VERSION "AgOpen Rate CAN ECU DBC with S0-S3 banks, 16 nodes, and service CAN"

NS_ :

BS_:

BU_: MASTER TOOL NODE1 NODE2 NODE3 NODE4 NODE5 NODE6 NODE7 NODE8 NODE9 NODE10 NODE11 NODE12 NODE13 NODE14 NODE15 NODE16

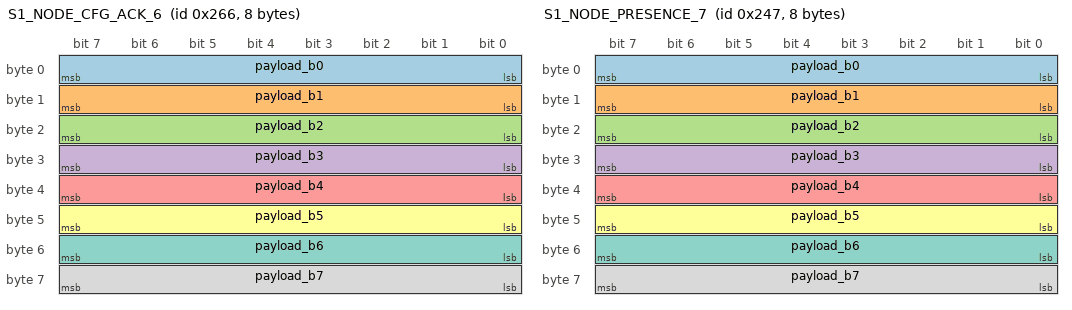
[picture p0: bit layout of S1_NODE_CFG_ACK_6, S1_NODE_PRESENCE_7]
BO_ 614 S1_NODE_CFG_ACK_6: 8 NODE6
 SG_ payload_b0 : 0|8@1+ (1,0) [0|255] "raw"  MASTER,NODE1,NODE2,NODE3,NODE4,NODE5,NODE6,NODE7,NODE8,NODE9,NODE10,NODE11,NODE12,NODE13,NODE14,NODE15,NODE16,TOOL
 SG_ payload_b1 : 8|8@1+ (1,0) [0|255] "raw"  MASTER,NODE1,NODE2,NODE3,NODE4,NODE5,NODE6,NODE7,NODE8,NODE9,NODE10,NODE11,NODE12,NODE13,NODE14,NODE15,NODE16,TOOL
 SG_ payload_b2 : 16|8@1+ (1,0) [0|255] "raw"  MASTER,NODE1,NODE2,NODE3,NODE4,NODE5,NODE6,NODE7,NODE8,NODE9,NODE10,NODE11,NODE12,NODE13,NODE14,NODE15,NODE16,TOOL
 SG_ payload_b3 : 24|8@1+ (1,0) [0|255] "raw"  MASTER,NODE1,NODE2,NODE3,NODE4,NODE5,NODE6,NODE7,NODE8,NODE9,NODE10,NODE11,NODE12,NODE13,NODE14,NODE15,NODE16,TOOL
 SG_ payload_b4 : 32|8@1+ (1,0) [0|255] "raw"  MASTER,NODE1,NODE2,NODE3,NODE4,NODE5,NODE6,NODE7,NODE8,NODE9,NODE10,NODE11,NODE12,NODE13,NODE14,NODE15,NODE16,TOOL
 SG_ payload_b5 : 40|8@1+ (1,0) [0|255] "raw"  MASTER,NODE1,NODE2,NODE3,NODE4,NODE5,NODE6,NODE7,NODE8,NODE9,NODE10,NODE11,NODE12,NODE13,NODE14,NODE15,NODE16,TOOL
 SG_ payload_b6 : 48|8@1+ (1,0) [0|255] "raw"  MASTER,NODE1,NODE2,NODE3,NODE4,NODE5,NODE6,NODE7,NODE8,NODE9,NODE10,NODE11,NODE12,NODE13,NODE14,NODE15,NODE16,TOOL
 SG_ payload_b7 : 56|8@1+ (1,0) [0|255] "raw"  MASTER,NODE1,NODE2,NODE3,NODE4,NODE5,NODE6,NODE7,NODE8,NODE9,NODE10,NODE11,NODE12,NODE13,NODE14,NODE15,NODE16,TOOL

BO_ 646 S1_NODE_STATUS_FAST_6: 8 NODE6
 SG_ status_flags : 0|8@1+ (1,0) [0|255] "bitfield"  MASTER,NODE1,NODE2,NODE3,NODE4,NODE5,NODE6,NODE7,NODE8,NODE9,NODE10,NODE11,NODE12,NODE13,NODE14,NODE15,NODE16,TOOL
 SG_ error_code : 8|8@1+ (1,0) [0|255] ""  MASTER,NODE1,NODE2,NODE3,NODE4,NODE5,NODE6,NODE7,NODE8,NODE9,NODE10,NODE11,NODE12,NODE13,NODE14,NODE15,NODE16,TOOL
 SG_ actual_rpm : 16|16@1+ (1,0) [0|10000] "rpm"  MASTER,NODE1,NODE2,NODE3,NODE4,NODE5,NODE6,NODE7,NODE8,NODE9,NODE10,NODE11,NODE12,NODE13,NODE14,NODE15,NODE16,TOOL
 SG_ actual_pos : 32|16@1+ (1.52587890625e-05,0) [0|0.9999847412109375] "rev"  MASTER,NODE1,NODE2,NODE3,NODE4,NODE5,NODE6,NODE7,NODE8,NODE9,NODE10,NODE11,NODE12,NODE13,NODE14,NODE15,NODE16,TOOL
 SG_ alive_counter : 48|8@1+ (1,0) [0|255] ""  MASTER,NODE1,NODE2,NODE3,NODE4,NODE5,NODE6,NODE7,NODE8,NODE9,NODE10,NODE11,NODE12,NODE13,NODE14,NODE15,NODE16,TOOL
 SG_ sync_error : 56|8@1- (0.00390625,0) [-0.5|0.49609375] "rev"  MASTER,NODE1,NODE2,NODE3,NODE4,NODE5,NODE6,NODE7,NODE8,NODE9,NODE10,NODE11,NODE12,NODE13,NODE14,NODE15,NODE16,TOOL

BO_ 710 S1_NODE_DIAG_6: 8 NODE6
 SG_ bus_voltage : 0|16@1+ (0.1,0) [0|6553.5] "V"  MASTER,NODE1,NODE2,NODE3,NODE4,NODE5,NODE6,NODE7,NODE8,NODE9,NODE10,NODE11,NODE12,NODE13,NODE14,NODE15,NODE16,TOOL
 SG_ motor_current : 16|16@1- (0.1,0) [-3276.8|3276.7] "A"  MASTER,NODE1,NODE2,NODE3,NODE4,NODE5,NODE6,NODE7,NODE8,NODE9,NODE10,NODE11,NODE12,NODE13,NODE14,NODE15,NODE16,TOOL
 SG_ controller_temp : 32|8@1- (1,0) [-128|127] "degC"  MASTER,NODE1,NODE2,NODE3,NODE4,NODE5,NODE6,NODE7,NODE8,NODE9,NODE10,NODE11,NODE12,NODE13,NODE14,NODE15,NODE16,TOOL
 SG_ motor_temp : 40|8@1- (1,0) [-128|127] "degC"  MASTER,NODE1,NODE2,NODE3,NODE4,NODE5,NODE6,NODE7,NODE8,NODE9,NODE10,NODE11,NODE12,NODE13,NODE14,NODE15,NODE16,TOOL
 SG_ fault_flags : 48|8@1+ (1,0) [0|255] "bitfield"  MASTER,NODE1,NODE2,NODE3,NODE4,NODE5,NODE6,NODE7,NODE8,NODE9,NODE10,NODE11,NODE12,NODE13,NODE14,NODE15,NODE16,TOOL
 SG_ warning_flags : 56|8@1+ (1,0) [0|255] "bitfield"  MASTER,NODE1,NODE2,NODE3,NODE4,NODE5,NODE6,NODE7,NODE8,NODE9,NODE10,NODE11,NODE12,NODE13,NODE14,NODE15,NODE16,TOOL

BO_ 535 S1_NODE_CMD_7: 8 MASTER
 SG_ node_command : 0|8@1+ (1,0) [0|255] ""  MASTER,NODE1,NODE2,NODE3,NODE4,NODE5,NODE6,NODE7,NODE8,NODE9,NODE10,NODE11,NODE12,NODE13,NODE14,NODE15,NODE16,TOOL
 SG_ node_flags : 8|8@1+ (1,0) [0|255] "bitfield"  MASTER,NODE1,NODE2,NODE3,NODE4,NODE5,NODE6,NODE7,NODE8,NODE9,NODE10,NODE11,NODE12,NODE13,NODE14,NODE15,NODE16,TOOL
 SG_ trim_rpm : 16|16@1- (0.1,0) [-3276.8|3276.7] "rpm"  MASTER,NODE1,NODE2,NODE3,NODE4,NODE5,NODE6,NODE7,NODE8,NODE9,NODE10,NODE11,NODE12,NODE13,NODE14,NODE15,NODE16,TOOL
 SG_ section_mask : 32|16@1+ (1,0) [0|65535] "bitmask"  MASTER,NODE1,NODE2,NODE3,NODE4,NODE5,NODE6,NODE7,NODE8,NODE9,NODE10,NODE11,NODE12,NODE13,NODE14,NODE15,NODE16,TOOL
 SG_ seq : 48|8@1+ (1,0) [0|255] ""  MASTER,NODE1,NODE2,NODE3,NODE4,NODE5,NODE6,NODE7,NODE8,NODE9,NODE10,NODE11,NODE12,NODE13,NODE14,NODE15,NODE16,TOOL
 SG_ reserved : 56|8@1+ (1,0) [0|255] ""  MASTER,NODE1,NODE2,NODE3,NODE4,NODE5,NODE6,NODE7,NODE8,NODE9,NODE10,NODE11,NODE12,NODE13,NODE14,NODE15,NODE16,TOOL

BO_ 583 S1_NODE_PRESENCE_7: 8 NODE7
 SG_ payload_b0 : 0|8@1+ (1,0) [0|255] "raw"  MASTER,NODE1,NODE2,NODE3,NODE4,NODE5,NODE6,NODE7,NODE8,NODE9,NODE10,NODE11,NODE12,NODE13,NODE14,NODE15,NODE16,TOOL
 SG_ payload_b1 : 8|8@1+ (1,0) [0|255] "raw"  MASTER,NODE1,NODE2,NODE3,NODE4,NODE5,NODE6,NODE7,NODE8,NODE9,NODE10,NODE11,NODE12,NODE13,NODE14,NODE15,NODE16,TOOL
 SG_ payload_b2 : 16|8@1+ (1,0) [0|255] "raw"  MASTER,NODE1,NODE2,NODE3,NODE4,NODE5,NODE6,NODE7,NODE8,NODE9,NODE10,NODE11,NODE12,NODE13,NODE14,NODE15,NODE16,TOOL
 SG_ payload_b3 : 24|8@1+ (1,0) [0|255] "raw"  MASTER,NODE1,NODE2,NODE3,NODE4,NODE5,NODE6,NODE7,NODE8,NODE9,NODE10,NODE11,NODE12,NODE13,NODE14,NODE15,NODE16,TOOL
 SG_ payload_b4 : 32|8@1+ (1,0) [0|255] "raw"  MASTER,NODE1,NODE2,NODE3,NODE4,NODE5,NODE6,NODE7,NODE8,NODE9,NODE10,NODE11,NODE12,NODE13,NODE14,NODE15,NODE16,TOOL
 SG_ payload_b5 : 40|8@1+ (1,0) [0|255] "raw"  MASTER,NODE1,NODE2,NODE3,NODE4,NODE5,NODE6,NODE7,NODE8,NODE9,NODE10,NODE11,NODE12,NODE13,NODE14,NODE15,NODE16,TOOL
 SG_ payload_b6 : 48|8@1+ (1,0) [0|255] "raw"  MASTER,NODE1,NODE2,NODE3,NODE4,NODE5,NODE6,NODE7,NODE8,NODE9,NODE10,NODE11,NODE12,NODE13,NODE14,NODE15,NODE16,TOOL
 SG_ payload_b7 : 56|8@1+ (1,0) [0|255] "raw"  MASTER,NODE1,NODE2,NODE3,NODE4,NODE5,NODE6,NODE7,NODE8,NODE9,NODE10,NODE11,NODE12,NODE13,NODE14,NODE15,NODE16,TOOL

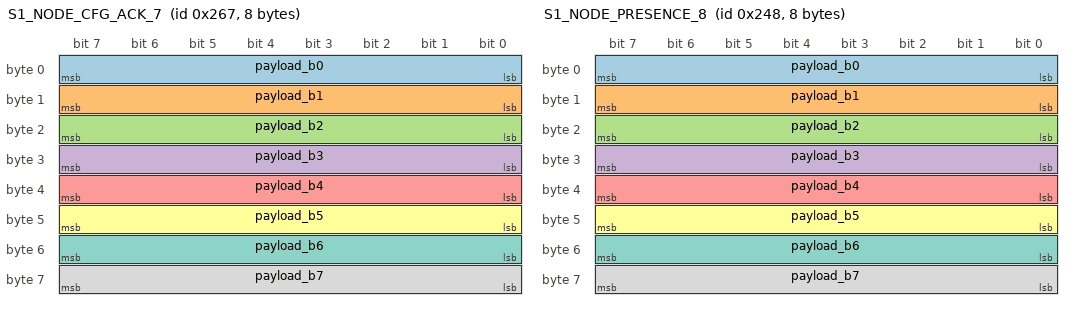
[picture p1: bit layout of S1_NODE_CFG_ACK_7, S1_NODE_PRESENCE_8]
BO_ 615 S1_NODE_CFG_ACK_7: 8 NODE7
 SG_ payload_b0 : 0|8@1+ (1,0) [0|255] "raw"  MASTER,NODE1,NODE2,NODE3,NODE4,NODE5,NODE6,NODE7,NODE8,NODE9,NODE10,NODE11,NODE12,NODE13,NODE14,NODE15,NODE16,TOOL
 SG_ payload_b1 : 8|8@1+ (1,0) [0|255] "raw"  MASTER,NODE1,NODE2,NODE3,NODE4,NODE5,NODE6,NODE7,NODE8,NODE9,NODE10,NODE11,NODE12,NODE13,NODE14,NODE15,NODE16,TOOL
 SG_ payload_b2 : 16|8@1+ (1,0) [0|255] "raw"  MASTER,NODE1,NODE2,NODE3,NODE4,NODE5,NODE6,NODE7,NODE8,NODE9,NODE10,NODE11,NODE12,NODE13,NODE14,NODE15,NODE16,TOOL
 SG_ payload_b3 : 24|8@1+ (1,0) [0|255] "raw"  MASTER,NODE1,NODE2,NODE3,NODE4,NODE5,NODE6,NODE7,NODE8,NODE9,NODE10,NODE11,NODE12,NODE13,NODE14,NODE15,NODE16,TOOL
 SG_ payload_b4 : 32|8@1+ (1,0) [0|255] "raw"  MASTER,NODE1,NODE2,NODE3,NODE4,NODE5,NODE6,NODE7,NODE8,NODE9,NODE10,NODE11,NODE12,NODE13,NODE14,NODE15,NODE16,TOOL
 SG_ payload_b5 : 40|8@1+ (1,0) [0|255] "raw"  MASTER,NODE1,NODE2,NODE3,NODE4,NODE5,NODE6,NODE7,NODE8,NODE9,NODE10,NODE11,NODE12,NODE13,NODE14,NODE15,NODE16,TOOL
 SG_ payload_b6 : 48|8@1+ (1,0) [0|255] "raw"  MASTER,NODE1,NODE2,NODE3,NODE4,NODE5,NODE6,NODE7,NODE8,NODE9,NODE10,NODE11,NODE12,NODE13,NODE14,NODE15,NODE16,TOOL
 SG_ payload_b7 : 56|8@1+ (1,0) [0|255] "raw"  MASTER,NODE1,NODE2,NODE3,NODE4,NODE5,NODE6,NODE7,NODE8,NODE9,NODE10,NODE11,NODE12,NODE13,NODE14,NODE15,NODE16,TOOL

BO_ 647 S1_NODE_STATUS_FAST_7: 8 NODE7
 SG_ status_flags : 0|8@1+ (1,0) [0|255] "bitfield"  MASTER,NODE1,NODE2,NODE3,NODE4,NODE5,NODE6,NODE7,NODE8,NODE9,NODE10,NODE11,NODE12,NODE13,NODE14,NODE15,NODE16,TOOL
 SG_ error_code : 8|8@1+ (1,0) [0|255] ""  MASTER,NODE1,NODE2,NODE3,NODE4,NODE5,NODE6,NODE7,NODE8,NODE9,NODE10,NODE11,NODE12,NODE13,NODE14,NODE15,NODE16,TOOL
 SG_ actual_rpm : 16|16@1+ (1,0) [0|10000] "rpm"  MASTER,NODE1,NODE2,NODE3,NODE4,NODE5,NODE6,NODE7,NODE8,NODE9,NODE10,NODE11,NODE12,NODE13,NODE14,NODE15,NODE16,TOOL
 SG_ actual_pos : 32|16@1+ (1.52587890625e-05,0) [0|0.9999847412109375] "rev"  MASTER,NODE1,NODE2,NODE3,NODE4,NODE5,NODE6,NODE7,NODE8,NODE9,NODE10,NODE11,NODE12,NODE13,NODE14,NODE15,NODE16,TOOL
 SG_ alive_counter : 48|8@1+ (1,0) [0|255] ""  MASTER,NODE1,NODE2,NODE3,NODE4,NODE5,NODE6,NODE7,NODE8,NODE9,NODE10,NODE11,NODE12,NODE13,NODE14,NODE15,NODE16,TOOL
 SG_ sync_error : 56|8@1- (0.00390625,0) [-0.5|0.49609375] "rev"  MASTER,NODE1,NODE2,NODE3,NODE4,NODE5,NODE6,NODE7,NODE8,NODE9,NODE10,NODE11,NODE12,NODE13,NODE14,NODE15,NODE16,TOOL

BO_ 711 S1_NODE_DIAG_7: 8 NODE7
 SG_ bus_voltage : 0|16@1+ (0.1,0) [0|6553.5] "V"  MASTER,NODE1,NODE2,NODE3,NODE4,NODE5,NODE6,NODE7,NODE8,NODE9,NODE10,NODE11,NODE12,NODE13,NODE14,NODE15,NODE16,TOOL
 SG_ motor_current : 16|16@1- (0.1,0) [-3276.8|3276.7] "A"  MASTER,NODE1,NODE2,NODE3,NODE4,NODE5,NODE6,NODE7,NODE8,NODE9,NODE10,NODE11,NODE12,NODE13,NODE14,NODE15,NODE16,TOOL
 SG_ controller_temp : 32|8@1- (1,0) [-128|127] "degC"  MASTER,NODE1,NODE2,NODE3,NODE4,NODE5,NODE6,NODE7,NODE8,NODE9,NODE10,NODE11,NODE12,NODE13,NODE14,NODE15,NODE16,TOOL
 SG_ motor_temp : 40|8@1- (1,0) [-128|127] "degC"  MASTER,NODE1,NODE2,NODE3,NODE4,NODE5,NODE6,NODE7,NODE8,NODE9,NODE10,NODE11,NODE12,NODE13,NODE14,NODE15,NODE16,TOOL
 SG_ fault_flags : 48|8@1+ (1,0) [0|255] "bitfield"  MASTER,NODE1,NODE2,NODE3,NODE4,NODE5,NODE6,NODE7,NODE8,NODE9,NODE10,NODE11,NODE12,NODE13,NODE14,NODE15,NODE16,TOOL
 SG_ warning_flags : 56|8@1+ (1,0) [0|255] "bitfield"  MASTER,NODE1,NODE2,NODE3,NODE4,NODE5,NODE6,NODE7,NODE8,NODE9,NODE10,NODE11,NODE12,NODE13,NODE14,NODE15,NODE16,TOOL

BO_ 536 S1_NODE_CMD_8: 8 MASTER
 SG_ node_command : 0|8@1+ (1,0) [0|255] ""  MASTER,NODE1,NODE2,NODE3,NODE4,NODE5,NODE6,NODE7,NODE8,NODE9,NODE10,NODE11,NODE12,NODE13,NODE14,NODE15,NODE16,TOOL
 SG_ node_flags : 8|8@1+ (1,0) [0|255] "bitfield"  MASTER,NODE1,NODE2,NODE3,NODE4,NODE5,NODE6,NODE7,NODE8,NODE9,NODE10,NODE11,NODE12,NODE13,NODE14,NODE15,NODE16,TOOL
 SG_ trim_rpm : 16|16@1- (0.1,0) [-3276.8|3276.7] "rpm"  MASTER,NODE1,NODE2,NODE3,NODE4,NODE5,NODE6,NODE7,NODE8,NODE9,NODE10,NODE11,NODE12,NODE13,NODE14,NODE15,NODE16,TOOL
 SG_ section_mask : 32|16@1+ (1,0) [0|65535] "bitmask"  MASTER,NODE1,NODE2,NODE3,NODE4,NODE5,NODE6,NODE7,NODE8,NODE9,NODE10,NODE11,NODE12,NODE13,NODE14,NODE15,NODE16,TOOL
 SG_ seq : 48|8@1+ (1,0) [0|255] ""  MASTER,NODE1,NODE2,NODE3,NODE4,NODE5,NODE6,NODE7,NODE8,NODE9,NODE10,NODE11,NODE12,NODE13,NODE14,NODE15,NODE16,TOOL
 SG_ reserved : 56|8@1+ (1,0) [0|255] ""  MASTER,NODE1,NODE2,NODE3,NODE4,NODE5,NODE6,NODE7,NODE8,NODE9,NODE10,NODE11,NODE12,NODE13,NODE14,NODE15,NODE16,TOOL

BO_ 584 S1_NODE_PRESENCE_8: 8 NODE8
 SG_ payload_b0 : 0|8@1+ (1,0) [0|255] "raw"  MASTER,NODE1,NODE2,NODE3,NODE4,NODE5,NODE6,NODE7,NODE8,NODE9,NODE10,NODE11,NODE12,NODE13,NODE14,NODE15,NODE16,TOOL
 SG_ payload_b1 : 8|8@1+ (1,0) [0|255] "raw"  MASTER,NODE1,NODE2,NODE3,NODE4,NODE5,NODE6,NODE7,NODE8,NODE9,NODE10,NODE11,NODE12,NODE13,NODE14,NODE15,NODE16,TOOL
 SG_ payload_b2 : 16|8@1+ (1,0) [0|255] "raw"  MASTER,NODE1,NODE2,NODE3,NODE4,NODE5,NODE6,NODE7,NODE8,NODE9,NODE10,NODE11,NODE12,NODE13,NODE14,NODE15,NODE16,TOOL
 SG_ payload_b3 : 24|8@1+ (1,0) [0|255] "raw"  MASTER,NODE1,NODE2,NODE3,NODE4,NODE5,NODE6,NODE7,NODE8,NODE9,NODE10,NODE11,NODE12,NODE13,NODE14,NODE15,NODE16,TOOL
 SG_ payload_b4 : 32|8@1+ (1,0) [0|255] "raw"  MASTER,NODE1,NODE2,NODE3,NODE4,NODE5,NODE6,NODE7,NODE8,NODE9,NODE10,NODE11,NODE12,NODE13,NODE14,NODE15,NODE16,TOOL
 SG_ payload_b5 : 40|8@1+ (1,0) [0|255] "raw"  MASTER,NODE1,NODE2,NODE3,NODE4,NODE5,NODE6,NODE7,NODE8,NODE9,NODE10,NODE11,NODE12,NODE13,NODE14,NODE15,NODE16,TOOL
 SG_ payload_b6 : 48|8@1+ (1,0) [0|255] "raw"  MASTER,NODE1,NODE2,NODE3,NODE4,NODE5,NODE6,NODE7,NODE8,NODE9,NODE10,NODE11,NODE12,NODE13,NODE14,NODE15,NODE16,TOOL
 SG_ payload_b7 : 56|8@1+ (1,0) [0|255] "raw"  MASTER,NODE1,NODE2,NODE3,NODE4,NODE5,NODE6,NODE7,NODE8,NODE9,NODE10,NODE11,NODE12,NODE13,NODE14,NODE15,NODE16,TOOL

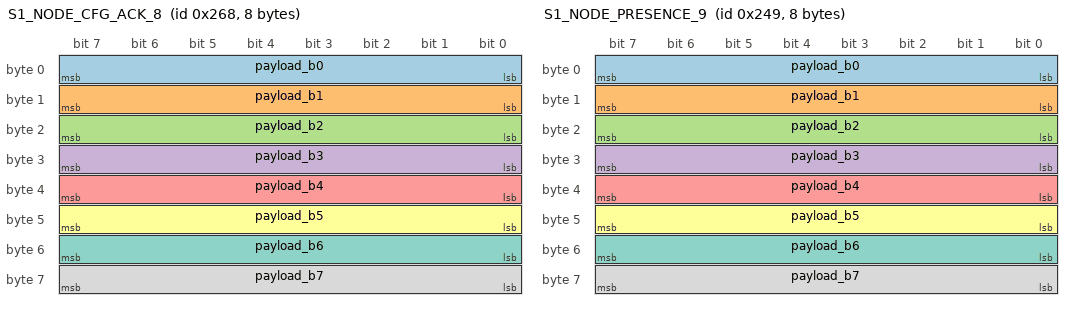
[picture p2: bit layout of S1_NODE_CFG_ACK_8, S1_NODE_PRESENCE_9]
BO_ 616 S1_NODE_CFG_ACK_8: 8 NODE8
 SG_ payload_b0 : 0|8@1+ (1,0) [0|255] "raw"  MASTER,NODE1,NODE2,NODE3,NODE4,NODE5,NODE6,NODE7,NODE8,NODE9,NODE10,NODE11,NODE12,NODE13,NODE14,NODE15,NODE16,TOOL
 SG_ payload_b1 : 8|8@1+ (1,0) [0|255] "raw"  MASTER,NODE1,NODE2,NODE3,NODE4,NODE5,NODE6,NODE7,NODE8,NODE9,NODE10,NODE11,NODE12,NODE13,NODE14,NODE15,NODE16,TOOL
 SG_ payload_b2 : 16|8@1+ (1,0) [0|255] "raw"  MASTER,NODE1,NODE2,NODE3,NODE4,NODE5,NODE6,NODE7,NODE8,NODE9,NODE10,NODE11,NODE12,NODE13,NODE14,NODE15,NODE16,TOOL
 SG_ payload_b3 : 24|8@1+ (1,0) [0|255] "raw"  MASTER,NODE1,NODE2,NODE3,NODE4,NODE5,NODE6,NODE7,NODE8,NODE9,NODE10,NODE11,NODE12,NODE13,NODE14,NODE15,NODE16,TOOL
 SG_ payload_b4 : 32|8@1+ (1,0) [0|255] "raw"  MASTER,NODE1,NODE2,NODE3,NODE4,NODE5,NODE6,NODE7,NODE8,NODE9,NODE10,NODE11,NODE12,NODE13,NODE14,NODE15,NODE16,TOOL
 SG_ payload_b5 : 40|8@1+ (1,0) [0|255] "raw"  MASTER,NODE1,NODE2,NODE3,NODE4,NODE5,NODE6,NODE7,NODE8,NODE9,NODE10,NODE11,NODE12,NODE13,NODE14,NODE15,NODE16,TOOL
 SG_ payload_b6 : 48|8@1+ (1,0) [0|255] "raw"  MASTER,NODE1,NODE2,NODE3,NODE4,NODE5,NODE6,NODE7,NODE8,NODE9,NODE10,NODE11,NODE12,NODE13,NODE14,NODE15,NODE16,TOOL
 SG_ payload_b7 : 56|8@1+ (1,0) [0|255] "raw"  MASTER,NODE1,NODE2,NODE3,NODE4,NODE5,NODE6,NODE7,NODE8,NODE9,NODE10,NODE11,NODE12,NODE13,NODE14,NODE15,NODE16,TOOL

BO_ 648 S1_NODE_STATUS_FAST_8: 8 NODE8
 SG_ status_flags : 0|8@1+ (1,0) [0|255] "bitfield"  MASTER,NODE1,NODE2,NODE3,NODE4,NODE5,NODE6,NODE7,NODE8,NODE9,NODE10,NODE11,NODE12,NODE13,NODE14,NODE15,NODE16,TOOL
 SG_ error_code : 8|8@1+ (1,0) [0|255] ""  MASTER,NODE1,NODE2,NODE3,NODE4,NODE5,NODE6,NODE7,NODE8,NODE9,NODE10,NODE11,NODE12,NODE13,NODE14,NODE15,NODE16,TOOL
 SG_ actual_rpm : 16|16@1+ (1,0) [0|10000] "rpm"  MASTER,NODE1,NODE2,NODE3,NODE4,NODE5,NODE6,NODE7,NODE8,NODE9,NODE10,NODE11,NODE12,NODE13,NODE14,NODE15,NODE16,TOOL
 SG_ actual_pos : 32|16@1+ (1.52587890625e-05,0) [0|0.9999847412109375] "rev"  MASTER,NODE1,NODE2,NODE3,NODE4,NODE5,NODE6,NODE7,NODE8,NODE9,NODE10,NODE11,NODE12,NODE13,NODE14,NODE15,NODE16,TOOL
 SG_ alive_counter : 48|8@1+ (1,0) [0|255] ""  MASTER,NODE1,NODE2,NODE3,NODE4,NODE5,NODE6,NODE7,NODE8,NODE9,NODE10,NODE11,NODE12,NODE13,NODE14,NODE15,NODE16,TOOL
 SG_ sync_error : 56|8@1- (0.00390625,0) [-0.5|0.49609375] "rev"  MASTER,NODE1,NODE2,NODE3,NODE4,NODE5,NODE6,NODE7,NODE8,NODE9,NODE10,NODE11,NODE12,NODE13,NODE14,NODE15,NODE16,TOOL

BO_ 712 S1_NODE_DIAG_8: 8 NODE8
 SG_ bus_voltage : 0|16@1+ (0.1,0) [0|6553.5] "V"  MASTER,NODE1,NODE2,NODE3,NODE4,NODE5,NODE6,NODE7,NODE8,NODE9,NODE10,NODE11,NODE12,NODE13,NODE14,NODE15,NODE16,TOOL
 SG_ motor_current : 16|16@1- (0.1,0) [-3276.8|3276.7] "A"  MASTER,NODE1,NODE2,NODE3,NODE4,NODE5,NODE6,NODE7,NODE8,NODE9,NODE10,NODE11,NODE12,NODE13,NODE14,NODE15,NODE16,TOOL
 SG_ controller_temp : 32|8@1- (1,0) [-128|127] "degC"  MASTER,NODE1,NODE2,NODE3,NODE4,NODE5,NODE6,NODE7,NODE8,NODE9,NODE10,NODE11,NODE12,NODE13,NODE14,NODE15,NODE16,TOOL
 SG_ motor_temp : 40|8@1- (1,0) [-128|127] "degC"  MASTER,NODE1,NODE2,NODE3,NODE4,NODE5,NODE6,NODE7,NODE8,NODE9,NODE10,NODE11,NODE12,NODE13,NODE14,NODE15,NODE16,TOOL
 SG_ fault_flags : 48|8@1+ (1,0) [0|255] "bitfield"  MASTER,NODE1,NODE2,NODE3,NODE4,NODE5,NODE6,NODE7,NODE8,NODE9,NODE10,NODE11,NODE12,NODE13,NODE14,NODE15,NODE16,TOOL
 SG_ warning_flags : 56|8@1+ (1,0) [0|255] "bitfield"  MASTER,NODE1,NODE2,NODE3,NODE4,NODE5,NODE6,NODE7,NODE8,NODE9,NODE10,NODE11,NODE12,NODE13,NODE14,NODE15,NODE16,TOOL

BO_ 537 S1_NODE_CMD_9: 8 MASTER
 SG_ node_command : 0|8@1+ (1,0) [0|255] ""  MASTER,NODE1,NODE2,NODE3,NODE4,NODE5,NODE6,NODE7,NODE8,NODE9,NODE10,NODE11,NODE12,NODE13,NODE14,NODE15,NODE16,TOOL
 SG_ node_flags : 8|8@1+ (1,0) [0|255] "bitfield"  MASTER,NODE1,NODE2,NODE3,NODE4,NODE5,NODE6,NODE7,NODE8,NODE9,NODE10,NODE11,NODE12,NODE13,NODE14,NODE15,NODE16,TOOL
 SG_ trim_rpm : 16|16@1- (0.1,0) [-3276.8|3276.7] "rpm"  MASTER,NODE1,NODE2,NODE3,NODE4,NODE5,NODE6,NODE7,NODE8,NODE9,NODE10,NODE11,NODE12,NODE13,NODE14,NODE15,NODE16,TOOL
 SG_ section_mask : 32|16@1+ (1,0) [0|65535] "bitmask"  MASTER,NODE1,NODE2,NODE3,NODE4,NODE5,NODE6,NODE7,NODE8,NODE9,NODE10,NODE11,NODE12,NODE13,NODE14,NODE15,NODE16,TOOL
 SG_ seq : 48|8@1+ (1,0) [0|255] ""  MASTER,NODE1,NODE2,NODE3,NODE4,NODE5,NODE6,NODE7,NODE8,NODE9,NODE10,NODE11,NODE12,NODE13,NODE14,NODE15,NODE16,TOOL
 SG_ reserved : 56|8@1+ (1,0) [0|255] ""  MASTER,NODE1,NODE2,NODE3,NODE4,NODE5,NODE6,NODE7,NODE8,NODE9,NODE10,NODE11,NODE12,NODE13,NODE14,NODE15,NODE16,TOOL

BO_ 585 S1_NODE_PRESENCE_9: 8 NODE9
 SG_ payload_b0 : 0|8@1+ (1,0) [0|255] "raw"  MASTER,NODE1,NODE2,NODE3,NODE4,NODE5,NODE6,NODE7,NODE8,NODE9,NODE10,NODE11,NODE12,NODE13,NODE14,NODE15,NODE16,TOOL
 SG_ payload_b1 : 8|8@1+ (1,0) [0|255] "raw"  MASTER,NODE1,NODE2,NODE3,NODE4,NODE5,NODE6,NODE7,NODE8,NODE9,NODE10,NODE11,NODE12,NODE13,NODE14,NODE15,NODE16,TOOL
 SG_ payload_b2 : 16|8@1+ (1,0) [0|255] "raw"  MASTER,NODE1,NODE2,NODE3,NODE4,NODE5,NODE6,NODE7,NODE8,NODE9,NODE10,NODE11,NODE12,NODE13,NODE14,NODE15,NODE16,TOOL
 SG_ payload_b3 : 24|8@1+ (1,0) [0|255] "raw"  MASTER,NODE1,NODE2,NODE3,NODE4,NODE5,NODE6,NODE7,NODE8,NODE9,NODE10,NODE11,NODE12,NODE13,NODE14,NODE15,NODE16,TOOL
 SG_ payload_b4 : 32|8@1+ (1,0) [0|255] "raw"  MASTER,NODE1,NODE2,NODE3,NODE4,NODE5,NODE6,NODE7,NODE8,NODE9,NODE10,NODE11,NODE12,NODE13,NODE14,NODE15,NODE16,TOOL
 SG_ payload_b5 : 40|8@1+ (1,0) [0|255] "raw"  MASTER,NODE1,NODE2,NODE3,NODE4,NODE5,NODE6,NODE7,NODE8,NODE9,NODE10,NODE11,NODE12,NODE13,NODE14,NODE15,NODE16,TOOL
 SG_ payload_b6 : 48|8@1+ (1,0) [0|255] "raw"  MASTER,NODE1,NODE2,NODE3,NODE4,NODE5,NODE6,NODE7,NODE8,NODE9,NODE10,NODE11,NODE12,NODE13,NODE14,NODE15,NODE16,TOOL
 SG_ payload_b7 : 56|8@1+ (1,0) [0|255] "raw"  MASTER,NODE1,NODE2,NODE3,NODE4,NODE5,NODE6,NODE7,NODE8,NODE9,NODE10,NODE11,NODE12,NODE13,NODE14,NODE15,NODE16,TOOL

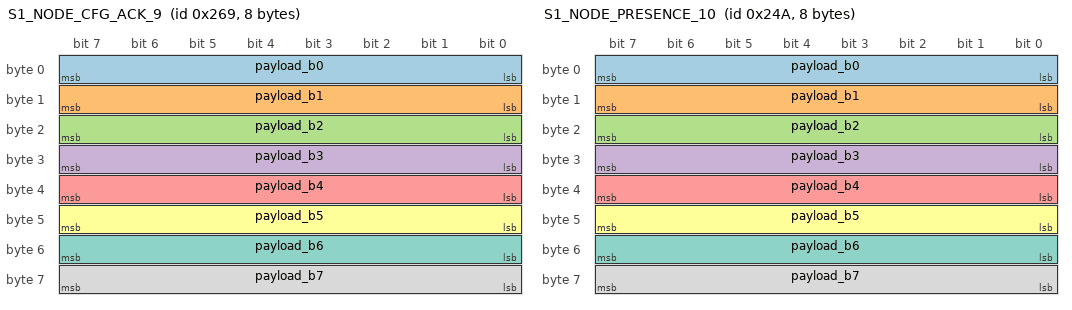
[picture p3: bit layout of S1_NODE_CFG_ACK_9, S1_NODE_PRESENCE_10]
BO_ 617 S1_NODE_CFG_ACK_9: 8 NODE9
 SG_ payload_b0 : 0|8@1+ (1,0) [0|255] "raw"  MASTER,NODE1,NODE2,NODE3,NODE4,NODE5,NODE6,NODE7,NODE8,NODE9,NODE10,NODE11,NODE12,NODE13,NODE14,NODE15,NODE16,TOOL
 SG_ payload_b1 : 8|8@1+ (1,0) [0|255] "raw"  MASTER,NODE1,NODE2,NODE3,NODE4,NODE5,NODE6,NODE7,NODE8,NODE9,NODE10,NODE11,NODE12,NODE13,NODE14,NODE15,NODE16,TOOL
 SG_ payload_b2 : 16|8@1+ (1,0) [0|255] "raw"  MASTER,NODE1,NODE2,NODE3,NODE4,NODE5,NODE6,NODE7,NODE8,NODE9,NODE10,NODE11,NODE12,NODE13,NODE14,NODE15,NODE16,TOOL
 SG_ payload_b3 : 24|8@1+ (1,0) [0|255] "raw"  MASTER,NODE1,NODE2,NODE3,NODE4,NODE5,NODE6,NODE7,NODE8,NODE9,NODE10,NODE11,NODE12,NODE13,NODE14,NODE15,NODE16,TOOL
 SG_ payload_b4 : 32|8@1+ (1,0) [0|255] "raw"  MASTER,NODE1,NODE2,NODE3,NODE4,NODE5,NODE6,NODE7,NODE8,NODE9,NODE10,NODE11,NODE12,NODE13,NODE14,NODE15,NODE16,TOOL
 SG_ payload_b5 : 40|8@1+ (1,0) [0|255] "raw"  MASTER,NODE1,NODE2,NODE3,NODE4,NODE5,NODE6,NODE7,NODE8,NODE9,NODE10,NODE11,NODE12,NODE13,NODE14,NODE15,NODE16,TOOL
 SG_ payload_b6 : 48|8@1+ (1,0) [0|255] "raw"  MASTER,NODE1,NODE2,NODE3,NODE4,NODE5,NODE6,NODE7,NODE8,NODE9,NODE10,NODE11,NODE12,NODE13,NODE14,NODE15,NODE16,TOOL
 SG_ payload_b7 : 56|8@1+ (1,0) [0|255] "raw"  MASTER,NODE1,NODE2,NODE3,NODE4,NODE5,NODE6,NODE7,NODE8,NODE9,NODE10,NODE11,NODE12,NODE13,NODE14,NODE15,NODE16,TOOL

BO_ 649 S1_NODE_STATUS_FAST_9: 8 NODE9
 SG_ status_flags : 0|8@1+ (1,0) [0|255] "bitfield"  MASTER,NODE1,NODE2,NODE3,NODE4,NODE5,NODE6,NODE7,NODE8,NODE9,NODE10,NODE11,NODE12,NODE13,NODE14,NODE15,NODE16,TOOL
 SG_ error_code : 8|8@1+ (1,0) [0|255] ""  MASTER,NODE1,NODE2,NODE3,NODE4,NODE5,NODE6,NODE7,NODE8,NODE9,NODE10,NODE11,NODE12,NODE13,NODE14,NODE15,NODE16,TOOL
 SG_ actual_rpm : 16|16@1+ (1,0) [0|10000] "rpm"  MASTER,NODE1,NODE2,NODE3,NODE4,NODE5,NODE6,NODE7,NODE8,NODE9,NODE10,NODE11,NODE12,NODE13,NODE14,NODE15,NODE16,TOOL
 SG_ actual_pos : 32|16@1+ (1.52587890625e-05,0) [0|0.9999847412109375] "rev"  MASTER,NODE1,NODE2,NODE3,NODE4,NODE5,NODE6,NODE7,NODE8,NODE9,NODE10,NODE11,NODE12,NODE13,NODE14,NODE15,NODE16,TOOL
 SG_ alive_counter : 48|8@1+ (1,0) [0|255] ""  MASTER,NODE1,NODE2,NODE3,NODE4,NODE5,NODE6,NODE7,NODE8,NODE9,NODE10,NODE11,NODE12,NODE13,NODE14,NODE15,NODE16,TOOL
 SG_ sync_error : 56|8@1- (0.00390625,0) [-0.5|0.49609375] "rev"  MASTER,NODE1,NODE2,NODE3,NODE4,NODE5,NODE6,NODE7,NODE8,NODE9,NODE10,NODE11,NODE12,NODE13,NODE14,NODE15,NODE16,TOOL

BO_ 713 S1_NODE_DIAG_9: 8 NODE9
 SG_ bus_voltage : 0|16@1+ (0.1,0) [0|6553.5] "V"  MASTER,NODE1,NODE2,NODE3,NODE4,NODE5,NODE6,NODE7,NODE8,NODE9,NODE10,NODE11,NODE12,NODE13,NODE14,NODE15,NODE16,TOOL
 SG_ motor_current : 16|16@1- (0.1,0) [-3276.8|3276.7] "A"  MASTER,NODE1,NODE2,NODE3,NODE4,NODE5,NODE6,NODE7,NODE8,NODE9,NODE10,NODE11,NODE12,NODE13,NODE14,NODE15,NODE16,TOOL
 SG_ controller_temp : 32|8@1- (1,0) [-128|127] "degC"  MASTER,NODE1,NODE2,NODE3,NODE4,NODE5,NODE6,NODE7,NODE8,NODE9,NODE10,NODE11,NODE12,NODE13,NODE14,NODE15,NODE16,TOOL
 SG_ motor_temp : 40|8@1- (1,0) [-128|127] "degC"  MASTER,NODE1,NODE2,NODE3,NODE4,NODE5,NODE6,NODE7,NODE8,NODE9,NODE10,NODE11,NODE12,NODE13,NODE14,NODE15,NODE16,TOOL
 SG_ fault_flags : 48|8@1+ (1,0) [0|255] "bitfield"  MASTER,NODE1,NODE2,NODE3,NODE4,NODE5,NODE6,NODE7,NODE8,NODE9,NODE10,NODE11,NODE12,NODE13,NODE14,NODE15,NODE16,TOOL
 SG_ warning_flags : 56|8@1+ (1,0) [0|255] "bitfield"  MASTER,NODE1,NODE2,NODE3,NODE4,NODE5,NODE6,NODE7,NODE8,NODE9,NODE10,NODE11,NODE12,NODE13,NODE14,NODE15,NODE16,TOOL

BO_ 538 S1_NODE_CMD_10: 8 MASTER
 SG_ node_command : 0|8@1+ (1,0) [0|255] ""  MASTER,NODE1,NODE2,NODE3,NODE4,NODE5,NODE6,NODE7,NODE8,NODE9,NODE10,NODE11,NODE12,NODE13,NODE14,NODE15,NODE16,TOOL
 SG_ node_flags : 8|8@1+ (1,0) [0|255] "bitfield"  MASTER,NODE1,NODE2,NODE3,NODE4,NODE5,NODE6,NODE7,NODE8,NODE9,NODE10,NODE11,NODE12,NODE13,NODE14,NODE15,NODE16,TOOL
 SG_ trim_rpm : 16|16@1- (0.1,0) [-3276.8|3276.7] "rpm"  MASTER,NODE1,NODE2,NODE3,NODE4,NODE5,NODE6,NODE7,NODE8,NODE9,NODE10,NODE11,NODE12,NODE13,NODE14,NODE15,NODE16,TOOL
 SG_ section_mask : 32|16@1+ (1,0) [0|65535] "bitmask"  MASTER,NODE1,NODE2,NODE3,NODE4,NODE5,NODE6,NODE7,NODE8,NODE9,NODE10,NODE11,NODE12,NODE13,NODE14,NODE15,NODE16,TOOL
 SG_ seq : 48|8@1+ (1,0) [0|255] ""  MASTER,NODE1,NODE2,NODE3,NODE4,NODE5,NODE6,NODE7,NODE8,NODE9,NODE10,NODE11,NODE12,NODE13,NODE14,NODE15,NODE16,TOOL
 SG_ reserved : 56|8@1+ (1,0) [0|255] ""  MASTER,NODE1,NODE2,NODE3,NODE4,NODE5,NODE6,NODE7,NODE8,NODE9,NODE10,NODE11,NODE12,NODE13,NODE14,NODE15,NODE16,TOOL

BO_ 586 S1_NODE_PRESENCE_10: 8 NODE10
 SG_ payload_b0 : 0|8@1+ (1,0) [0|255] "raw"  MASTER,NODE1,NODE2,NODE3,NODE4,NODE5,NODE6,NODE7,NODE8,NODE9,NODE10,NODE11,NODE12,NODE13,NODE14,NODE15,NODE16,TOOL
 SG_ payload_b1 : 8|8@1+ (1,0) [0|255] "raw"  MASTER,NODE1,NODE2,NODE3,NODE4,NODE5,NODE6,NODE7,NODE8,NODE9,NODE10,NODE11,NODE12,NODE13,NODE14,NODE15,NODE16,TOOL
 SG_ payload_b2 : 16|8@1+ (1,0) [0|255] "raw"  MASTER,NODE1,NODE2,NODE3,NODE4,NODE5,NODE6,NODE7,NODE8,NODE9,NODE10,NODE11,NODE12,NODE13,NODE14,NODE15,NODE16,TOOL
 SG_ payload_b3 : 24|8@1+ (1,0) [0|255] "raw"  MASTER,NODE1,NODE2,NODE3,NODE4,NODE5,NODE6,NODE7,NODE8,NODE9,NODE10,NODE11,NODE12,NODE13,NODE14,NODE15,NODE16,TOOL
 SG_ payload_b4 : 32|8@1+ (1,0) [0|255] "raw"  MASTER,NODE1,NODE2,NODE3,NODE4,NODE5,NODE6,NODE7,NODE8,NODE9,NODE10,NODE11,NODE12,NODE13,NODE14,NODE15,NODE16,TOOL
 SG_ payload_b5 : 40|8@1+ (1,0) [0|255] "raw"  MASTER,NODE1,NODE2,NODE3,NODE4,NODE5,NODE6,NODE7,NODE8,NODE9,NODE10,NODE11,NODE12,NODE13,NODE14,NODE15,NODE16,TOOL
 SG_ payload_b6 : 48|8@1+ (1,0) [0|255] "raw"  MASTER,NODE1,NODE2,NODE3,NODE4,NODE5,NODE6,NODE7,NODE8,NODE9,NODE10,NODE11,NODE12,NODE13,NODE14,NODE15,NODE16,TOOL
 SG_ payload_b7 : 56|8@1+ (1,0) [0|255] "raw"  MASTER,NODE1,NODE2,NODE3,NODE4,NODE5,NODE6,NODE7,NODE8,NODE9,NODE10,NODE11,NODE12,NODE13,NODE14,NODE15,NODE16,TOOL

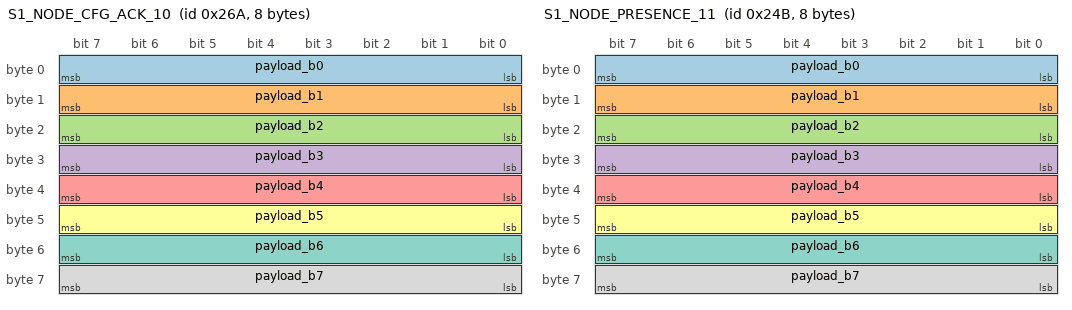
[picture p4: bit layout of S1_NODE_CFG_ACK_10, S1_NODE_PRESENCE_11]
BO_ 618 S1_NODE_CFG_ACK_10: 8 NODE10
 SG_ payload_b0 : 0|8@1+ (1,0) [0|255] "raw"  MASTER,NODE1,NODE2,NODE3,NODE4,NODE5,NODE6,NODE7,NODE8,NODE9,NODE10,NODE11,NODE12,NODE13,NODE14,NODE15,NODE16,TOOL
 SG_ payload_b1 : 8|8@1+ (1,0) [0|255] "raw"  MASTER,NODE1,NODE2,NODE3,NODE4,NODE5,NODE6,NODE7,NODE8,NODE9,NODE10,NODE11,NODE12,NODE13,NODE14,NODE15,NODE16,TOOL
 SG_ payload_b2 : 16|8@1+ (1,0) [0|255] "raw"  MASTER,NODE1,NODE2,NODE3,NODE4,NODE5,NODE6,NODE7,NODE8,NODE9,NODE10,NODE11,NODE12,NODE13,NODE14,NODE15,NODE16,TOOL
 SG_ payload_b3 : 24|8@1+ (1,0) [0|255] "raw"  MASTER,NODE1,NODE2,NODE3,NODE4,NODE5,NODE6,NODE7,NODE8,NODE9,NODE10,NODE11,NODE12,NODE13,NODE14,NODE15,NODE16,TOOL
 SG_ payload_b4 : 32|8@1+ (1,0) [0|255] "raw"  MASTER,NODE1,NODE2,NODE3,NODE4,NODE5,NODE6,NODE7,NODE8,NODE9,NODE10,NODE11,NODE12,NODE13,NODE14,NODE15,NODE16,TOOL
 SG_ payload_b5 : 40|8@1+ (1,0) [0|255] "raw"  MASTER,NODE1,NODE2,NODE3,NODE4,NODE5,NODE6,NODE7,NODE8,NODE9,NODE10,NODE11,NODE12,NODE13,NODE14,NODE15,NODE16,TOOL
 SG_ payload_b6 : 48|8@1+ (1,0) [0|255] "raw"  MASTER,NODE1,NODE2,NODE3,NODE4,NODE5,NODE6,NODE7,NODE8,NODE9,NODE10,NODE11,NODE12,NODE13,NODE14,NODE15,NODE16,TOOL
 SG_ payload_b7 : 56|8@1+ (1,0) [0|255] "raw"  MASTER,NODE1,NODE2,NODE3,NODE4,NODE5,NODE6,NODE7,NODE8,NODE9,NODE10,NODE11,NODE12,NODE13,NODE14,NODE15,NODE16,TOOL

BO_ 650 S1_NODE_STATUS_FAST_10: 8 NODE10
 SG_ status_flags : 0|8@1+ (1,0) [0|255] "bitfield"  MASTER,NODE1,NODE2,NODE3,NODE4,NODE5,NODE6,NODE7,NODE8,NODE9,NODE10,NODE11,NODE12,NODE13,NODE14,NODE15,NODE16,TOOL
 SG_ error_code : 8|8@1+ (1,0) [0|255] ""  MASTER,NODE1,NODE2,NODE3,NODE4,NODE5,NODE6,NODE7,NODE8,NODE9,NODE10,NODE11,NODE12,NODE13,NODE14,NODE15,NODE16,TOOL
 SG_ actual_rpm : 16|16@1+ (1,0) [0|10000] "rpm"  MASTER,NODE1,NODE2,NODE3,NODE4,NODE5,NODE6,NODE7,NODE8,NODE9,NODE10,NODE11,NODE12,NODE13,NODE14,NODE15,NODE16,TOOL
 SG_ actual_pos : 32|16@1+ (1.52587890625e-05,0) [0|0.9999847412109375] "rev"  MASTER,NODE1,NODE2,NODE3,NODE4,NODE5,NODE6,NODE7,NODE8,NODE9,NODE10,NODE11,NODE12,NODE13,NODE14,NODE15,NODE16,TOOL
 SG_ alive_counter : 48|8@1+ (1,0) [0|255] ""  MASTER,NODE1,NODE2,NODE3,NODE4,NODE5,NODE6,NODE7,NODE8,NODE9,NODE10,NODE11,NODE12,NODE13,NODE14,NODE15,NODE16,TOOL
 SG_ sync_error : 56|8@1- (0.00390625,0) [-0.5|0.49609375] "rev"  MASTER,NODE1,NODE2,NODE3,NODE4,NODE5,NODE6,NODE7,NODE8,NODE9,NODE10,NODE11,NODE12,NODE13,NODE14,NODE15,NODE16,TOOL

BO_ 714 S1_NODE_DIAG_10: 8 NODE10
 SG_ bus_voltage : 0|16@1+ (0.1,0) [0|6553.5] "V"  MASTER,NODE1,NODE2,NODE3,NODE4,NODE5,NODE6,NODE7,NODE8,NODE9,NODE10,NODE11,NODE12,NODE13,NODE14,NODE15,NODE16,TOOL
 SG_ motor_current : 16|16@1- (0.1,0) [-3276.8|3276.7] "A"  MASTER,NODE1,NODE2,NODE3,NODE4,NODE5,NODE6,NODE7,NODE8,NODE9,NODE10,NODE11,NODE12,NODE13,NODE14,NODE15,NODE16,TOOL
 SG_ controller_temp : 32|8@1- (1,0) [-128|127] "degC"  MASTER,NODE1,NODE2,NODE3,NODE4,NODE5,NODE6,NODE7,NODE8,NODE9,NODE10,NODE11,NODE12,NODE13,NODE14,NODE15,NODE16,TOOL
 SG_ motor_temp : 40|8@1- (1,0) [-128|127] "degC"  MASTER,NODE1,NODE2,NODE3,NODE4,NODE5,NODE6,NODE7,NODE8,NODE9,NODE10,NODE11,NODE12,NODE13,NODE14,NODE15,NODE16,TOOL
 SG_ fault_flags : 48|8@1+ (1,0) [0|255] "bitfield"  MASTER,NODE1,NODE2,NODE3,NODE4,NODE5,NODE6,NODE7,NODE8,NODE9,NODE10,NODE11,NODE12,NODE13,NODE14,NODE15,NODE16,TOOL
 SG_ warning_flags : 56|8@1+ (1,0) [0|255] "bitfield"  MASTER,NODE1,NODE2,NODE3,NODE4,NODE5,NODE6,NODE7,NODE8,NODE9,NODE10,NODE11,NODE12,NODE13,NODE14,NODE15,NODE16,TOOL

BO_ 539 S1_NODE_CMD_11: 8 MASTER
 SG_ node_command : 0|8@1+ (1,0) [0|255] ""  MASTER,NODE1,NODE2,NODE3,NODE4,NODE5,NODE6,NODE7,NODE8,NODE9,NODE10,NODE11,NODE12,NODE13,NODE14,NODE15,NODE16,TOOL
 SG_ node_flags : 8|8@1+ (1,0) [0|255] "bitfield"  MASTER,NODE1,NODE2,NODE3,NODE4,NODE5,NODE6,NODE7,NODE8,NODE9,NODE10,NODE11,NODE12,NODE13,NODE14,NODE15,NODE16,TOOL
 SG_ trim_rpm : 16|16@1- (0.1,0) [-3276.8|3276.7] "rpm"  MASTER,NODE1,NODE2,NODE3,NODE4,NODE5,NODE6,NODE7,NODE8,NODE9,NODE10,NODE11,NODE12,NODE13,NODE14,NODE15,NODE16,TOOL
 SG_ section_mask : 32|16@1+ (1,0) [0|65535] "bitmask"  MASTER,NODE1,NODE2,NODE3,NODE4,NODE5,NODE6,NODE7,NODE8,NODE9,NODE10,NODE11,NODE12,NODE13,NODE14,NODE15,NODE16,TOOL
 SG_ seq : 48|8@1+ (1,0) [0|255] ""  MASTER,NODE1,NODE2,NODE3,NODE4,NODE5,NODE6,NODE7,NODE8,NODE9,NODE10,NODE11,NODE12,NODE13,NODE14,NODE15,NODE16,TOOL
 SG_ reserved : 56|8@1+ (1,0) [0|255] ""  MASTER,NODE1,NODE2,NODE3,NODE4,NODE5,NODE6,NODE7,NODE8,NODE9,NODE10,NODE11,NODE12,NODE13,NODE14,NODE15,NODE16,TOOL

BO_ 587 S1_NODE_PRESENCE_11: 8 NODE11
 SG_ payload_b0 : 0|8@1+ (1,0) [0|255] "raw"  MASTER,NODE1,NODE2,NODE3,NODE4,NODE5,NODE6,NODE7,NODE8,NODE9,NODE10,NODE11,NODE12,NODE13,NODE14,NODE15,NODE16,TOOL
 SG_ payload_b1 : 8|8@1+ (1,0) [0|255] "raw"  MASTER,NODE1,NODE2,NODE3,NODE4,NODE5,NODE6,NODE7,NODE8,NODE9,NODE10,NODE11,NODE12,NODE13,NODE14,NODE15,NODE16,TOOL
 SG_ payload_b2 : 16|8@1+ (1,0) [0|255] "raw"  MASTER,NODE1,NODE2,NODE3,NODE4,NODE5,NODE6,NODE7,NODE8,NODE9,NODE10,NODE11,NODE12,NODE13,NODE14,NODE15,NODE16,TOOL
 SG_ payload_b3 : 24|8@1+ (1,0) [0|255] "raw"  MASTER,NODE1,NODE2,NODE3,NODE4,NODE5,NODE6,NODE7,NODE8,NODE9,NODE10,NODE11,NODE12,NODE13,NODE14,NODE15,NODE16,TOOL
 SG_ payload_b4 : 32|8@1+ (1,0) [0|255] "raw"  MASTER,NODE1,NODE2,NODE3,NODE4,NODE5,NODE6,NODE7,NODE8,NODE9,NODE10,NODE11,NODE12,NODE13,NODE14,NODE15,NODE16,TOOL
 SG_ payload_b5 : 40|8@1+ (1,0) [0|255] "raw"  MASTER,NODE1,NODE2,NODE3,NODE4,NODE5,NODE6,NODE7,NODE8,NODE9,NODE10,NODE11,NODE12,NODE13,NODE14,NODE15,NODE16,TOOL
 SG_ payload_b6 : 48|8@1+ (1,0) [0|255] "raw"  MASTER,NODE1,NODE2,NODE3,NODE4,NODE5,NODE6,NODE7,NODE8,NODE9,NODE10,NODE11,NODE12,NODE13,NODE14,NODE15,NODE16,TOOL
 SG_ payload_b7 : 56|8@1+ (1,0) [0|255] "raw"  MASTER,NODE1,NODE2,NODE3,NODE4,NODE5,NODE6,NODE7,NODE8,NODE9,NODE10,NODE11,NODE12,NODE13,NODE14,NODE15,NODE16,TOOL

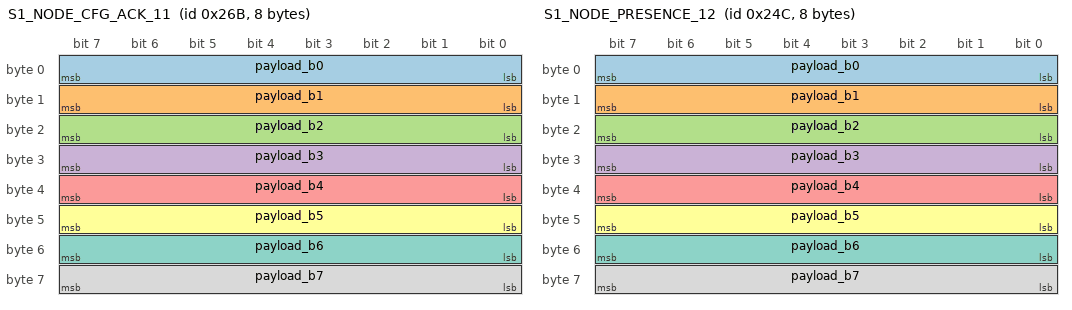
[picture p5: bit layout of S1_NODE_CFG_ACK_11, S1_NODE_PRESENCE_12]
BO_ 619 S1_NODE_CFG_ACK_11: 8 NODE11
 SG_ payload_b0 : 0|8@1+ (1,0) [0|255] "raw"  MASTER,NODE1,NODE2,NODE3,NODE4,NODE5,NODE6,NODE7,NODE8,NODE9,NODE10,NODE11,NODE12,NODE13,NODE14,NODE15,NODE16,TOOL
 SG_ payload_b1 : 8|8@1+ (1,0) [0|255] "raw"  MASTER,NODE1,NODE2,NODE3,NODE4,NODE5,NODE6,NODE7,NODE8,NODE9,NODE10,NODE11,NODE12,NODE13,NODE14,NODE15,NODE16,TOOL
 SG_ payload_b2 : 16|8@1+ (1,0) [0|255] "raw"  MASTER,NODE1,NODE2,NODE3,NODE4,NODE5,NODE6,NODE7,NODE8,NODE9,NODE10,NODE11,NODE12,NODE13,NODE14,NODE15,NODE16,TOOL
 SG_ payload_b3 : 24|8@1+ (1,0) [0|255] "raw"  MASTER,NODE1,NODE2,NODE3,NODE4,NODE5,NODE6,NODE7,NODE8,NODE9,NODE10,NODE11,NODE12,NODE13,NODE14,NODE15,NODE16,TOOL
 SG_ payload_b4 : 32|8@1+ (1,0) [0|255] "raw"  MASTER,NODE1,NODE2,NODE3,NODE4,NODE5,NODE6,NODE7,NODE8,NODE9,NODE10,NODE11,NODE12,NODE13,NODE14,NODE15,NODE16,TOOL
 SG_ payload_b5 : 40|8@1+ (1,0) [0|255] "raw"  MASTER,NODE1,NODE2,NODE3,NODE4,NODE5,NODE6,NODE7,NODE8,NODE9,NODE10,NODE11,NODE12,NODE13,NODE14,NODE15,NODE16,TOOL
 SG_ payload_b6 : 48|8@1+ (1,0) [0|255] "raw"  MASTER,NODE1,NODE2,NODE3,NODE4,NODE5,NODE6,NODE7,NODE8,NODE9,NODE10,NODE11,NODE12,NODE13,NODE14,NODE15,NODE16,TOOL
 SG_ payload_b7 : 56|8@1+ (1,0) [0|255] "raw"  MASTER,NODE1,NODE2,NODE3,NODE4,NODE5,NODE6,NODE7,NODE8,NODE9,NODE10,NODE11,NODE12,NODE13,NODE14,NODE15,NODE16,TOOL

BO_ 651 S1_NODE_STATUS_FAST_11: 8 NODE11
 SG_ status_flags : 0|8@1+ (1,0) [0|255] "bitfield"  MASTER,NODE1,NODE2,NODE3,NODE4,NODE5,NODE6,NODE7,NODE8,NODE9,NODE10,NODE11,NODE12,NODE13,NODE14,NODE15,NODE16,TOOL
 SG_ error_code : 8|8@1+ (1,0) [0|255] ""  MASTER,NODE1,NODE2,NODE3,NODE4,NODE5,NODE6,NODE7,NODE8,NODE9,NODE10,NODE11,NODE12,NODE13,NODE14,NODE15,NODE16,TOOL
 SG_ actual_rpm : 16|16@1+ (1,0) [0|10000] "rpm"  MASTER,NODE1,NODE2,NODE3,NODE4,NODE5,NODE6,NODE7,NODE8,NODE9,NODE10,NODE11,NODE12,NODE13,NODE14,NODE15,NODE16,TOOL
 SG_ actual_pos : 32|16@1+ (1.52587890625e-05,0) [0|0.9999847412109375] "rev"  MASTER,NODE1,NODE2,NODE3,NODE4,NODE5,NODE6,NODE7,NODE8,NODE9,NODE10,NODE11,NODE12,NODE13,NODE14,NODE15,NODE16,TOOL
 SG_ alive_counter : 48|8@1+ (1,0) [0|255] ""  MASTER,NODE1,NODE2,NODE3,NODE4,NODE5,NODE6,NODE7,NODE8,NODE9,NODE10,NODE11,NODE12,NODE13,NODE14,NODE15,NODE16,TOOL
 SG_ sync_error : 56|8@1- (0.00390625,0) [-0.5|0.49609375] "rev"  MASTER,NODE1,NODE2,NODE3,NODE4,NODE5,NODE6,NODE7,NODE8,NODE9,NODE10,NODE11,NODE12,NODE13,NODE14,NODE15,NODE16,TOOL

BO_ 715 S1_NODE_DIAG_11: 8 NODE11
 SG_ bus_voltage : 0|16@1+ (0.1,0) [0|6553.5] "V"  MASTER,NODE1,NODE2,NODE3,NODE4,NODE5,NODE6,NODE7,NODE8,NODE9,NODE10,NODE11,NODE12,NODE13,NODE14,NODE15,NODE16,TOOL
 SG_ motor_current : 16|16@1- (0.1,0) [-3276.8|3276.7] "A"  MASTER,NODE1,NODE2,NODE3,NODE4,NODE5,NODE6,NODE7,NODE8,NODE9,NODE10,NODE11,NODE12,NODE13,NODE14,NODE15,NODE16,TOOL
 SG_ controller_temp : 32|8@1- (1,0) [-128|127] "degC"  MASTER,NODE1,NODE2,NODE3,NODE4,NODE5,NODE6,NODE7,NODE8,NODE9,NODE10,NODE11,NODE12,NODE13,NODE14,NODE15,NODE16,TOOL
 SG_ motor_temp : 40|8@1- (1,0) [-128|127] "degC"  MASTER,NODE1,NODE2,NODE3,NODE4,NODE5,NODE6,NODE7,NODE8,NODE9,NODE10,NODE11,NODE12,NODE13,NODE14,NODE15,NODE16,TOOL
 SG_ fault_flags : 48|8@1+ (1,0) [0|255] "bitfield"  MASTER,NODE1,NODE2,NODE3,NODE4,NODE5,NODE6,NODE7,NODE8,NODE9,NODE10,NODE11,NODE12,NODE13,NODE14,NODE15,NODE16,TOOL
 SG_ warning_flags : 56|8@1+ (1,0) [0|255] "bitfield"  MASTER,NODE1,NODE2,NODE3,NODE4,NODE5,NODE6,NODE7,NODE8,NODE9,NODE10,NODE11,NODE12,NODE13,NODE14,NODE15,NODE16,TOOL

BO_ 540 S1_NODE_CMD_12: 8 MASTER
 SG_ node_command : 0|8@1+ (1,0) [0|255] ""  MASTER,NODE1,NODE2,NODE3,NODE4,NODE5,NODE6,NODE7,NODE8,NODE9,NODE10,NODE11,NODE12,NODE13,NODE14,NODE15,NODE16,TOOL
 SG_ node_flags : 8|8@1+ (1,0) [0|255] "bitfield"  MASTER,NODE1,NODE2,NODE3,NODE4,NODE5,NODE6,NODE7,NODE8,NODE9,NODE10,NODE11,NODE12,NODE13,NODE14,NODE15,NODE16,TOOL
 SG_ trim_rpm : 16|16@1- (0.1,0) [-3276.8|3276.7] "rpm"  MASTER,NODE1,NODE2,NODE3,NODE4,NODE5,NODE6,NODE7,NODE8,NODE9,NODE10,NODE11,NODE12,NODE13,NODE14,NODE15,NODE16,TOOL
 SG_ section_mask : 32|16@1+ (1,0) [0|65535] "bitmask"  MASTER,NODE1,NODE2,NODE3,NODE4,NODE5,NODE6,NODE7,NODE8,NODE9,NODE10,NODE11,NODE12,NODE13,NODE14,NODE15,NODE16,TOOL
 SG_ seq : 48|8@1+ (1,0) [0|255] ""  MASTER,NODE1,NODE2,NODE3,NODE4,NODE5,NODE6,NODE7,NODE8,NODE9,NODE10,NODE11,NODE12,NODE13,NODE14,NODE15,NODE16,TOOL
 SG_ reserved : 56|8@1+ (1,0) [0|255] ""  MASTER,NODE1,NODE2,NODE3,NODE4,NODE5,NODE6,NODE7,NODE8,NODE9,NODE10,NODE11,NODE12,NODE13,NODE14,NODE15,NODE16,TOOL

BO_ 588 S1_NODE_PRESENCE_12: 8 NODE12
 SG_ payload_b0 : 0|8@1+ (1,0) [0|255] "raw"  MASTER,NODE1,NODE2,NODE3,NODE4,NODE5,NODE6,NODE7,NODE8,NODE9,NODE10,NODE11,NODE12,NODE13,NODE14,NODE15,NODE16,TOOL
 SG_ payload_b1 : 8|8@1+ (1,0) [0|255] "raw"  MASTER,NODE1,NODE2,NODE3,NODE4,NODE5,NODE6,NODE7,NODE8,NODE9,NODE10,NODE11,NODE12,NODE13,NODE14,NODE15,NODE16,TOOL
 SG_ payload_b2 : 16|8@1+ (1,0) [0|255] "raw"  MASTER,NODE1,NODE2,NODE3,NODE4,NODE5,NODE6,NODE7,NODE8,NODE9,NODE10,NODE11,NODE12,NODE13,NODE14,NODE15,NODE16,TOOL
 SG_ payload_b3 : 24|8@1+ (1,0) [0|255] "raw"  MASTER,NODE1,NODE2,NODE3,NODE4,NODE5,NODE6,NODE7,NODE8,NODE9,NODE10,NODE11,NODE12,NODE13,NODE14,NODE15,NODE16,TOOL
 SG_ payload_b4 : 32|8@1+ (1,0) [0|255] "raw"  MASTER,NODE1,NODE2,NODE3,NODE4,NODE5,NODE6,NODE7,NODE8,NODE9,NODE10,NODE11,NODE12,NODE13,NODE14,NODE15,NODE16,TOOL
 SG_ payload_b5 : 40|8@1+ (1,0) [0|255] "raw"  MASTER,NODE1,NODE2,NODE3,NODE4,NODE5,NODE6,NODE7,NODE8,NODE9,NODE10,NODE11,NODE12,NODE13,NODE14,NODE15,NODE16,TOOL
 SG_ payload_b6 : 48|8@1+ (1,0) [0|255] "raw"  MASTER,NODE1,NODE2,NODE3,NODE4,NODE5,NODE6,NODE7,NODE8,NODE9,NODE10,NODE11,NODE12,NODE13,NODE14,NODE15,NODE16,TOOL
 SG_ payload_b7 : 56|8@1+ (1,0) [0|255] "raw"  MASTER,NODE1,NODE2,NODE3,NODE4,NODE5,NODE6,NODE7,NODE8,NODE9,NODE10,NODE11,NODE12,NODE13,NODE14,NODE15,NODE16,TOOL

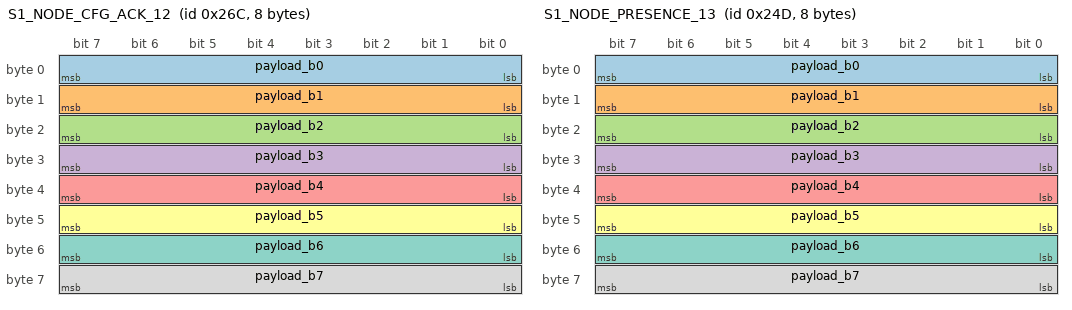
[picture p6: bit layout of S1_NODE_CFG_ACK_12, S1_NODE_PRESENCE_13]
BO_ 620 S1_NODE_CFG_ACK_12: 8 NODE12
 SG_ payload_b0 : 0|8@1+ (1,0) [0|255] "raw"  MASTER,NODE1,NODE2,NODE3,NODE4,NODE5,NODE6,NODE7,NODE8,NODE9,NODE10,NODE11,NODE12,NODE13,NODE14,NODE15,NODE16,TOOL
 SG_ payload_b1 : 8|8@1+ (1,0) [0|255] "raw"  MASTER,NODE1,NODE2,NODE3,NODE4,NODE5,NODE6,NODE7,NODE8,NODE9,NODE10,NODE11,NODE12,NODE13,NODE14,NODE15,NODE16,TOOL
 SG_ payload_b2 : 16|8@1+ (1,0) [0|255] "raw"  MASTER,NODE1,NODE2,NODE3,NODE4,NODE5,NODE6,NODE7,NODE8,NODE9,NODE10,NODE11,NODE12,NODE13,NODE14,NODE15,NODE16,TOOL
 SG_ payload_b3 : 24|8@1+ (1,0) [0|255] "raw"  MASTER,NODE1,NODE2,NODE3,NODE4,NODE5,NODE6,NODE7,NODE8,NODE9,NODE10,NODE11,NODE12,NODE13,NODE14,NODE15,NODE16,TOOL
 SG_ payload_b4 : 32|8@1+ (1,0) [0|255] "raw"  MASTER,NODE1,NODE2,NODE3,NODE4,NODE5,NODE6,NODE7,NODE8,NODE9,NODE10,NODE11,NODE12,NODE13,NODE14,NODE15,NODE16,TOOL
 SG_ payload_b5 : 40|8@1+ (1,0) [0|255] "raw"  MASTER,NODE1,NODE2,NODE3,NODE4,NODE5,NODE6,NODE7,NODE8,NODE9,NODE10,NODE11,NODE12,NODE13,NODE14,NODE15,NODE16,TOOL
 SG_ payload_b6 : 48|8@1+ (1,0) [0|255] "raw"  MASTER,NODE1,NODE2,NODE3,NODE4,NODE5,NODE6,NODE7,NODE8,NODE9,NODE10,NODE11,NODE12,NODE13,NODE14,NODE15,NODE16,TOOL
 SG_ payload_b7 : 56|8@1+ (1,0) [0|255] "raw"  MASTER,NODE1,NODE2,NODE3,NODE4,NODE5,NODE6,NODE7,NODE8,NODE9,NODE10,NODE11,NODE12,NODE13,NODE14,NODE15,NODE16,TOOL

BO_ 652 S1_NODE_STATUS_FAST_12: 8 NODE12
 SG_ status_flags : 0|8@1+ (1,0) [0|255] "bitfield"  MASTER,NODE1,NODE2,NODE3,NODE4,NODE5,NODE6,NODE7,NODE8,NODE9,NODE10,NODE11,NODE12,NODE13,NODE14,NODE15,NODE16,TOOL
 SG_ error_code : 8|8@1+ (1,0) [0|255] ""  MASTER,NODE1,NODE2,NODE3,NODE4,NODE5,NODE6,NODE7,NODE8,NODE9,NODE10,NODE11,NODE12,NODE13,NODE14,NODE15,NODE16,TOOL
 SG_ actual_rpm : 16|16@1+ (1,0) [0|10000] "rpm"  MASTER,NODE1,NODE2,NODE3,NODE4,NODE5,NODE6,NODE7,NODE8,NODE9,NODE10,NODE11,NODE12,NODE13,NODE14,NODE15,NODE16,TOOL
 SG_ actual_pos : 32|16@1+ (1.52587890625e-05,0) [0|0.9999847412109375] "rev"  MASTER,NODE1,NODE2,NODE3,NODE4,NODE5,NODE6,NODE7,NODE8,NODE9,NODE10,NODE11,NODE12,NODE13,NODE14,NODE15,NODE16,TOOL
 SG_ alive_counter : 48|8@1+ (1,0) [0|255] ""  MASTER,NODE1,NODE2,NODE3,NODE4,NODE5,NODE6,NODE7,NODE8,NODE9,NODE10,NODE11,NODE12,NODE13,NODE14,NODE15,NODE16,TOOL
 SG_ sync_error : 56|8@1- (0.00390625,0) [-0.5|0.49609375] "rev"  MASTER,NODE1,NODE2,NODE3,NODE4,NODE5,NODE6,NODE7,NODE8,NODE9,NODE10,NODE11,NODE12,NODE13,NODE14,NODE15,NODE16,TOOL

BO_ 716 S1_NODE_DIAG_12: 8 NODE12
 SG_ bus_voltage : 0|16@1+ (0.1,0) [0|6553.5] "V"  MASTER,NODE1,NODE2,NODE3,NODE4,NODE5,NODE6,NODE7,NODE8,NODE9,NODE10,NODE11,NODE12,NODE13,NODE14,NODE15,NODE16,TOOL
 SG_ motor_current : 16|16@1- (0.1,0) [-3276.8|3276.7] "A"  MASTER,NODE1,NODE2,NODE3,NODE4,NODE5,NODE6,NODE7,NODE8,NODE9,NODE10,NODE11,NODE12,NODE13,NODE14,NODE15,NODE16,TOOL
 SG_ controller_temp : 32|8@1- (1,0) [-128|127] "degC"  MASTER,NODE1,NODE2,NODE3,NODE4,NODE5,NODE6,NODE7,NODE8,NODE9,NODE10,NODE11,NODE12,NODE13,NODE14,NODE15,NODE16,TOOL
 SG_ motor_temp : 40|8@1- (1,0) [-128|127] "degC"  MASTER,NODE1,NODE2,NODE3,NODE4,NODE5,NODE6,NODE7,NODE8,NODE9,NODE10,NODE11,NODE12,NODE13,NODE14,NODE15,NODE16,TOOL
 SG_ fault_flags : 48|8@1+ (1,0) [0|255] "bitfield"  MASTER,NODE1,NODE2,NODE3,NODE4,NODE5,NODE6,NODE7,NODE8,NODE9,NODE10,NODE11,NODE12,NODE13,NODE14,NODE15,NODE16,TOOL
 SG_ warning_flags : 56|8@1+ (1,0) [0|255] "bitfield"  MASTER,NODE1,NODE2,NODE3,NODE4,NODE5,NODE6,NODE7,NODE8,NODE9,NODE10,NODE11,NODE12,NODE13,NODE14,NODE15,NODE16,TOOL

BO_ 541 S1_NODE_CMD_13: 8 MASTER
 SG_ node_command : 0|8@1+ (1,0) [0|255] ""  MASTER,NODE1,NODE2,NODE3,NODE4,NODE5,NODE6,NODE7,NODE8,NODE9,NODE10,NODE11,NODE12,NODE13,NODE14,NODE15,NODE16,TOOL
 SG_ node_flags : 8|8@1+ (1,0) [0|255] "bitfield"  MASTER,NODE1,NODE2,NODE3,NODE4,NODE5,NODE6,NODE7,NODE8,NODE9,NODE10,NODE11,NODE12,NODE13,NODE14,NODE15,NODE16,TOOL
 SG_ trim_rpm : 16|16@1- (0.1,0) [-3276.8|3276.7] "rpm"  MASTER,NODE1,NODE2,NODE3,NODE4,NODE5,NODE6,NODE7,NODE8,NODE9,NODE10,NODE11,NODE12,NODE13,NODE14,NODE15,NODE16,TOOL
 SG_ section_mask : 32|16@1+ (1,0) [0|65535] "bitmask"  MASTER,NODE1,NODE2,NODE3,NODE4,NODE5,NODE6,NODE7,NODE8,NODE9,NODE10,NODE11,NODE12,NODE13,NODE14,NODE15,NODE16,TOOL
 SG_ seq : 48|8@1+ (1,0) [0|255] ""  MASTER,NODE1,NODE2,NODE3,NODE4,NODE5,NODE6,NODE7,NODE8,NODE9,NODE10,NODE11,NODE12,NODE13,NODE14,NODE15,NODE16,TOOL
 SG_ reserved : 56|8@1+ (1,0) [0|255] ""  MASTER,NODE1,NODE2,NODE3,NODE4,NODE5,NODE6,NODE7,NODE8,NODE9,NODE10,NODE11,NODE12,NODE13,NODE14,NODE15,NODE16,TOOL

BO_ 589 S1_NODE_PRESENCE_13: 8 NODE13
 SG_ payload_b0 : 0|8@1+ (1,0) [0|255] "raw"  MASTER,NODE1,NODE2,NODE3,NODE4,NODE5,NODE6,NODE7,NODE8,NODE9,NODE10,NODE11,NODE12,NODE13,NODE14,NODE15,NODE16,TOOL
 SG_ payload_b1 : 8|8@1+ (1,0) [0|255] "raw"  MASTER,NODE1,NODE2,NODE3,NODE4,NODE5,NODE6,NODE7,NODE8,NODE9,NODE10,NODE11,NODE12,NODE13,NODE14,NODE15,NODE16,TOOL
 SG_ payload_b2 : 16|8@1+ (1,0) [0|255] "raw"  MASTER,NODE1,NODE2,NODE3,NODE4,NODE5,NODE6,NODE7,NODE8,NODE9,NODE10,NODE11,NODE12,NODE13,NODE14,NODE15,NODE16,TOOL
 SG_ payload_b3 : 24|8@1+ (1,0) [0|255] "raw"  MASTER,NODE1,NODE2,NODE3,NODE4,NODE5,NODE6,NODE7,NODE8,NODE9,NODE10,NODE11,NODE12,NODE13,NODE14,NODE15,NODE16,TOOL
 SG_ payload_b4 : 32|8@1+ (1,0) [0|255] "raw"  MASTER,NODE1,NODE2,NODE3,NODE4,NODE5,NODE6,NODE7,NODE8,NODE9,NODE10,NODE11,NODE12,NODE13,NODE14,NODE15,NODE16,TOOL
 SG_ payload_b5 : 40|8@1+ (1,0) [0|255] "raw"  MASTER,NODE1,NODE2,NODE3,NODE4,NODE5,NODE6,NODE7,NODE8,NODE9,NODE10,NODE11,NODE12,NODE13,NODE14,NODE15,NODE16,TOOL
 SG_ payload_b6 : 48|8@1+ (1,0) [0|255] "raw"  MASTER,NODE1,NODE2,NODE3,NODE4,NODE5,NODE6,NODE7,NODE8,NODE9,NODE10,NODE11,NODE12,NODE13,NODE14,NODE15,NODE16,TOOL
 SG_ payload_b7 : 56|8@1+ (1,0) [0|255] "raw"  MASTER,NODE1,NODE2,NODE3,NODE4,NODE5,NODE6,NODE7,NODE8,NODE9,NODE10,NODE11,NODE12,NODE13,NODE14,NODE15,NODE16,TOOL

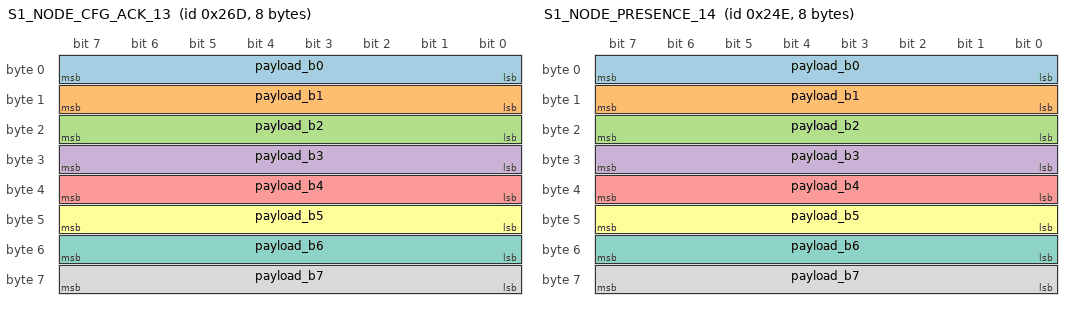
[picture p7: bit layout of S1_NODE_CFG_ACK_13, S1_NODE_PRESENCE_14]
BO_ 621 S1_NODE_CFG_ACK_13: 8 NODE13
 SG_ payload_b0 : 0|8@1+ (1,0) [0|255] "raw"  MASTER,NODE1,NODE2,NODE3,NODE4,NODE5,NODE6,NODE7,NODE8,NODE9,NODE10,NODE11,NODE12,NODE13,NODE14,NODE15,NODE16,TOOL
 SG_ payload_b1 : 8|8@1+ (1,0) [0|255] "raw"  MASTER,NODE1,NODE2,NODE3,NODE4,NODE5,NODE6,NODE7,NODE8,NODE9,NODE10,NODE11,NODE12,NODE13,NODE14,NODE15,NODE16,TOOL
 SG_ payload_b2 : 16|8@1+ (1,0) [0|255] "raw"  MASTER,NODE1,NODE2,NODE3,NODE4,NODE5,NODE6,NODE7,NODE8,NODE9,NODE10,NODE11,NODE12,NODE13,NODE14,NODE15,NODE16,TOOL
 SG_ payload_b3 : 24|8@1+ (1,0) [0|255] "raw"  MASTER,NODE1,NODE2,NODE3,NODE4,NODE5,NODE6,NODE7,NODE8,NODE9,NODE10,NODE11,NODE12,NODE13,NODE14,NODE15,NODE16,TOOL
 SG_ payload_b4 : 32|8@1+ (1,0) [0|255] "raw"  MASTER,NODE1,NODE2,NODE3,NODE4,NODE5,NODE6,NODE7,NODE8,NODE9,NODE10,NODE11,NODE12,NODE13,NODE14,NODE15,NODE16,TOOL
 SG_ payload_b5 : 40|8@1+ (1,0) [0|255] "raw"  MASTER,NODE1,NODE2,NODE3,NODE4,NODE5,NODE6,NODE7,NODE8,NODE9,NODE10,NODE11,NODE12,NODE13,NODE14,NODE15,NODE16,TOOL
 SG_ payload_b6 : 48|8@1+ (1,0) [0|255] "raw"  MASTER,NODE1,NODE2,NODE3,NODE4,NODE5,NODE6,NODE7,NODE8,NODE9,NODE10,NODE11,NODE12,NODE13,NODE14,NODE15,NODE16,TOOL
 SG_ payload_b7 : 56|8@1+ (1,0) [0|255] "raw"  MASTER,NODE1,NODE2,NODE3,NODE4,NODE5,NODE6,NODE7,NODE8,NODE9,NODE10,NODE11,NODE12,NODE13,NODE14,NODE15,NODE16,TOOL

BO_ 653 S1_NODE_STATUS_FAST_13: 8 NODE13
 SG_ status_flags : 0|8@1+ (1,0) [0|255] "bitfield"  MASTER,NODE1,NODE2,NODE3,NODE4,NODE5,NODE6,NODE7,NODE8,NODE9,NODE10,NODE11,NODE12,NODE13,NODE14,NODE15,NODE16,TOOL
 SG_ error_code : 8|8@1+ (1,0) [0|255] ""  MASTER,NODE1,NODE2,NODE3,NODE4,NODE5,NODE6,NODE7,NODE8,NODE9,NODE10,NODE11,NODE12,NODE13,NODE14,NODE15,NODE16,TOOL
 SG_ actual_rpm : 16|16@1+ (1,0) [0|10000] "rpm"  MASTER,NODE1,NODE2,NODE3,NODE4,NODE5,NODE6,NODE7,NODE8,NODE9,NODE10,NODE11,NODE12,NODE13,NODE14,NODE15,NODE16,TOOL
 SG_ actual_pos : 32|16@1+ (1.52587890625e-05,0) [0|0.9999847412109375] "rev"  MASTER,NODE1,NODE2,NODE3,NODE4,NODE5,NODE6,NODE7,NODE8,NODE9,NODE10,NODE11,NODE12,NODE13,NODE14,NODE15,NODE16,TOOL
 SG_ alive_counter : 48|8@1+ (1,0) [0|255] ""  MASTER,NODE1,NODE2,NODE3,NODE4,NODE5,NODE6,NODE7,NODE8,NODE9,NODE10,NODE11,NODE12,NODE13,NODE14,NODE15,NODE16,TOOL
 SG_ sync_error : 56|8@1- (0.00390625,0) [-0.5|0.49609375] "rev"  MASTER,NODE1,NODE2,NODE3,NODE4,NODE5,NODE6,NODE7,NODE8,NODE9,NODE10,NODE11,NODE12,NODE13,NODE14,NODE15,NODE16,TOOL

BO_ 717 S1_NODE_DIAG_13: 8 NODE13
 SG_ bus_voltage : 0|16@1+ (0.1,0) [0|6553.5] "V"  MASTER,NODE1,NODE2,NODE3,NODE4,NODE5,NODE6,NODE7,NODE8,NODE9,NODE10,NODE11,NODE12,NODE13,NODE14,NODE15,NODE16,TOOL
 SG_ motor_current : 16|16@1- (0.1,0) [-3276.8|3276.7] "A"  MASTER,NODE1,NODE2,NODE3,NODE4,NODE5,NODE6,NODE7,NODE8,NODE9,NODE10,NODE11,NODE12,NODE13,NODE14,NODE15,NODE16,TOOL
 SG_ controller_temp : 32|8@1- (1,0) [-128|127] "degC"  MASTER,NODE1,NODE2,NODE3,NODE4,NODE5,NODE6,NODE7,NODE8,NODE9,NODE10,NODE11,NODE12,NODE13,NODE14,NODE15,NODE16,TOOL
 SG_ motor_temp : 40|8@1- (1,0) [-128|127] "degC"  MASTER,NODE1,NODE2,NODE3,NODE4,NODE5,NODE6,NODE7,NODE8,NODE9,NODE10,NODE11,NODE12,NODE13,NODE14,NODE15,NODE16,TOOL
 SG_ fault_flags : 48|8@1+ (1,0) [0|255] "bitfield"  MASTER,NODE1,NODE2,NODE3,NODE4,NODE5,NODE6,NODE7,NODE8,NODE9,NODE10,NODE11,NODE12,NODE13,NODE14,NODE15,NODE16,TOOL
 SG_ warning_flags : 56|8@1+ (1,0) [0|255] "bitfield"  MASTER,NODE1,NODE2,NODE3,NODE4,NODE5,NODE6,NODE7,NODE8,NODE9,NODE10,NODE11,NODE12,NODE13,NODE14,NODE15,NODE16,TOOL

BO_ 542 S1_NODE_CMD_14: 8 MASTER
 SG_ node_command : 0|8@1+ (1,0) [0|255] ""  MASTER,NODE1,NODE2,NODE3,NODE4,NODE5,NODE6,NODE7,NODE8,NODE9,NODE10,NODE11,NODE12,NODE13,NODE14,NODE15,NODE16,TOOL
 SG_ node_flags : 8|8@1+ (1,0) [0|255] "bitfield"  MASTER,NODE1,NODE2,NODE3,NODE4,NODE5,NODE6,NODE7,NODE8,NODE9,NODE10,NODE11,NODE12,NODE13,NODE14,NODE15,NODE16,TOOL
 SG_ trim_rpm : 16|16@1- (0.1,0) [-3276.8|3276.7] "rpm"  MASTER,NODE1,NODE2,NODE3,NODE4,NODE5,NODE6,NODE7,NODE8,NODE9,NODE10,NODE11,NODE12,NODE13,NODE14,NODE15,NODE16,TOOL
 SG_ section_mask : 32|16@1+ (1,0) [0|65535] "bitmask"  MASTER,NODE1,NODE2,NODE3,NODE4,NODE5,NODE6,NODE7,NODE8,NODE9,NODE10,NODE11,NODE12,NODE13,NODE14,NODE15,NODE16,TOOL
 SG_ seq : 48|8@1+ (1,0) [0|255] ""  MASTER,NODE1,NODE2,NODE3,NODE4,NODE5,NODE6,NODE7,NODE8,NODE9,NODE10,NODE11,NODE12,NODE13,NODE14,NODE15,NODE16,TOOL
 SG_ reserved : 56|8@1+ (1,0) [0|255] ""  MASTER,NODE1,NODE2,NODE3,NODE4,NODE5,NODE6,NODE7,NODE8,NODE9,NODE10,NODE11,NODE12,NODE13,NODE14,NODE15,NODE16,TOOL

BO_ 590 S1_NODE_PRESENCE_14: 8 NODE14
 SG_ payload_b0 : 0|8@1+ (1,0) [0|255] "raw"  MASTER,NODE1,NODE2,NODE3,NODE4,NODE5,NODE6,NODE7,NODE8,NODE9,NODE10,NODE11,NODE12,NODE13,NODE14,NODE15,NODE16,TOOL
 SG_ payload_b1 : 8|8@1+ (1,0) [0|255] "raw"  MASTER,NODE1,NODE2,NODE3,NODE4,NODE5,NODE6,NODE7,NODE8,NODE9,NODE10,NODE11,NODE12,NODE13,NODE14,NODE15,NODE16,TOOL
 SG_ payload_b2 : 16|8@1+ (1,0) [0|255] "raw"  MASTER,NODE1,NODE2,NODE3,NODE4,NODE5,NODE6,NODE7,NODE8,NODE9,NODE10,NODE11,NODE12,NODE13,NODE14,NODE15,NODE16,TOOL
 SG_ payload_b3 : 24|8@1+ (1,0) [0|255] "raw"  MASTER,NODE1,NODE2,NODE3,NODE4,NODE5,NODE6,NODE7,NODE8,NODE9,NODE10,NODE11,NODE12,NODE13,NODE14,NODE15,NODE16,TOOL
 SG_ payload_b4 : 32|8@1+ (1,0) [0|255] "raw"  MASTER,NODE1,NODE2,NODE3,NODE4,NODE5,NODE6,NODE7,NODE8,NODE9,NODE10,NODE11,NODE12,NODE13,NODE14,NODE15,NODE16,TOOL
 SG_ payload_b5 : 40|8@1+ (1,0) [0|255] "raw"  MASTER,NODE1,NODE2,NODE3,NODE4,NODE5,NODE6,NODE7,NODE8,NODE9,NODE10,NODE11,NODE12,NODE13,NODE14,NODE15,NODE16,TOOL
 SG_ payload_b6 : 48|8@1+ (1,0) [0|255] "raw"  MASTER,NODE1,NODE2,NODE3,NODE4,NODE5,NODE6,NODE7,NODE8,NODE9,NODE10,NODE11,NODE12,NODE13,NODE14,NODE15,NODE16,TOOL
 SG_ payload_b7 : 56|8@1+ (1,0) [0|255] "raw"  MASTER,NODE1,NODE2,NODE3,NODE4,NODE5,NODE6,NODE7,NODE8,NODE9,NODE10,NODE11,NODE12,NODE13,NODE14,NODE15,NODE16,TOOL

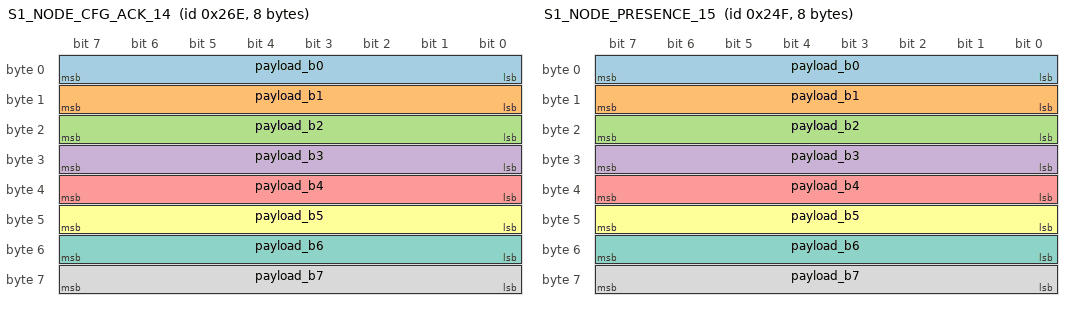
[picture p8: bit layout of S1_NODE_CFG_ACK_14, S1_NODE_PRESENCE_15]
BO_ 622 S1_NODE_CFG_ACK_14: 8 NODE14
 SG_ payload_b0 : 0|8@1+ (1,0) [0|255] "raw"  MASTER,NODE1,NODE2,NODE3,NODE4,NODE5,NODE6,NODE7,NODE8,NODE9,NODE10,NODE11,NODE12,NODE13,NODE14,NODE15,NODE16,TOOL
 SG_ payload_b1 : 8|8@1+ (1,0) [0|255] "raw"  MASTER,NODE1,NODE2,NODE3,NODE4,NODE5,NODE6,NODE7,NODE8,NODE9,NODE10,NODE11,NODE12,NODE13,NODE14,NODE15,NODE16,TOOL
 SG_ payload_b2 : 16|8@1+ (1,0) [0|255] "raw"  MASTER,NODE1,NODE2,NODE3,NODE4,NODE5,NODE6,NODE7,NODE8,NODE9,NODE10,NODE11,NODE12,NODE13,NODE14,NODE15,NODE16,TOOL
 SG_ payload_b3 : 24|8@1+ (1,0) [0|255] "raw"  MASTER,NODE1,NODE2,NODE3,NODE4,NODE5,NODE6,NODE7,NODE8,NODE9,NODE10,NODE11,NODE12,NODE13,NODE14,NODE15,NODE16,TOOL
 SG_ payload_b4 : 32|8@1+ (1,0) [0|255] "raw"  MASTER,NODE1,NODE2,NODE3,NODE4,NODE5,NODE6,NODE7,NODE8,NODE9,NODE10,NODE11,NODE12,NODE13,NODE14,NODE15,NODE16,TOOL
 SG_ payload_b5 : 40|8@1+ (1,0) [0|255] "raw"  MASTER,NODE1,NODE2,NODE3,NODE4,NODE5,NODE6,NODE7,NODE8,NODE9,NODE10,NODE11,NODE12,NODE13,NODE14,NODE15,NODE16,TOOL
 SG_ payload_b6 : 48|8@1+ (1,0) [0|255] "raw"  MASTER,NODE1,NODE2,NODE3,NODE4,NODE5,NODE6,NODE7,NODE8,NODE9,NODE10,NODE11,NODE12,NODE13,NODE14,NODE15,NODE16,TOOL
 SG_ payload_b7 : 56|8@1+ (1,0) [0|255] "raw"  MASTER,NODE1,NODE2,NODE3,NODE4,NODE5,NODE6,NODE7,NODE8,NODE9,NODE10,NODE11,NODE12,NODE13,NODE14,NODE15,NODE16,TOOL

BO_ 654 S1_NODE_STATUS_FAST_14: 8 NODE14
 SG_ status_flags : 0|8@1+ (1,0) [0|255] "bitfield"  MASTER,NODE1,NODE2,NODE3,NODE4,NODE5,NODE6,NODE7,NODE8,NODE9,NODE10,NODE11,NODE12,NODE13,NODE14,NODE15,NODE16,TOOL
 SG_ error_code : 8|8@1+ (1,0) [0|255] ""  MASTER,NODE1,NODE2,NODE3,NODE4,NODE5,NODE6,NODE7,NODE8,NODE9,NODE10,NODE11,NODE12,NODE13,NODE14,NODE15,NODE16,TOOL
 SG_ actual_rpm : 16|16@1+ (1,0) [0|10000] "rpm"  MASTER,NODE1,NODE2,NODE3,NODE4,NODE5,NODE6,NODE7,NODE8,NODE9,NODE10,NODE11,NODE12,NODE13,NODE14,NODE15,NODE16,TOOL
 SG_ actual_pos : 32|16@1+ (1.52587890625e-05,0) [0|0.9999847412109375] "rev"  MASTER,NODE1,NODE2,NODE3,NODE4,NODE5,NODE6,NODE7,NODE8,NODE9,NODE10,NODE11,NODE12,NODE13,NODE14,NODE15,NODE16,TOOL
 SG_ alive_counter : 48|8@1+ (1,0) [0|255] ""  MASTER,NODE1,NODE2,NODE3,NODE4,NODE5,NODE6,NODE7,NODE8,NODE9,NODE10,NODE11,NODE12,NODE13,NODE14,NODE15,NODE16,TOOL
 SG_ sync_error : 56|8@1- (0.00390625,0) [-0.5|0.49609375] "rev"  MASTER,NODE1,NODE2,NODE3,NODE4,NODE5,NODE6,NODE7,NODE8,NODE9,NODE10,NODE11,NODE12,NODE13,NODE14,NODE15,NODE16,TOOL

BO_ 718 S1_NODE_DIAG_14: 8 NODE14
 SG_ bus_voltage : 0|16@1+ (0.1,0) [0|6553.5] "V"  MASTER,NODE1,NODE2,NODE3,NODE4,NODE5,NODE6,NODE7,NODE8,NODE9,NODE10,NODE11,NODE12,NODE13,NODE14,NODE15,NODE16,TOOL
 SG_ motor_current : 16|16@1- (0.1,0) [-3276.8|3276.7] "A"  MASTER,NODE1,NODE2,NODE3,NODE4,NODE5,NODE6,NODE7,NODE8,NODE9,NODE10,NODE11,NODE12,NODE13,NODE14,NODE15,NODE16,TOOL
 SG_ controller_temp : 32|8@1- (1,0) [-128|127] "degC"  MASTER,NODE1,NODE2,NODE3,NODE4,NODE5,NODE6,NODE7,NODE8,NODE9,NODE10,NODE11,NODE12,NODE13,NODE14,NODE15,NODE16,TOOL
 SG_ motor_temp : 40|8@1- (1,0) [-128|127] "degC"  MASTER,NODE1,NODE2,NODE3,NODE4,NODE5,NODE6,NODE7,NODE8,NODE9,NODE10,NODE11,NODE12,NODE13,NODE14,NODE15,NODE16,TOOL
 SG_ fault_flags : 48|8@1+ (1,0) [0|255] "bitfield"  MASTER,NODE1,NODE2,NODE3,NODE4,NODE5,NODE6,NODE7,NODE8,NODE9,NODE10,NODE11,NODE12,NODE13,NODE14,NODE15,NODE16,TOOL
 SG_ warning_flags : 56|8@1+ (1,0) [0|255] "bitfield"  MASTER,NODE1,NODE2,NODE3,NODE4,NODE5,NODE6,NODE7,NODE8,NODE9,NODE10,NODE11,NODE12,NODE13,NODE14,NODE15,NODE16,TOOL

BO_ 543 S1_NODE_CMD_15: 8 MASTER
 SG_ node_command : 0|8@1+ (1,0) [0|255] ""  MASTER,NODE1,NODE2,NODE3,NODE4,NODE5,NODE6,NODE7,NODE8,NODE9,NODE10,NODE11,NODE12,NODE13,NODE14,NODE15,NODE16,TOOL
 SG_ node_flags : 8|8@1+ (1,0) [0|255] "bitfield"  MASTER,NODE1,NODE2,NODE3,NODE4,NODE5,NODE6,NODE7,NODE8,NODE9,NODE10,NODE11,NODE12,NODE13,NODE14,NODE15,NODE16,TOOL
 SG_ trim_rpm : 16|16@1- (0.1,0) [-3276.8|3276.7] "rpm"  MASTER,NODE1,NODE2,NODE3,NODE4,NODE5,NODE6,NODE7,NODE8,NODE9,NODE10,NODE11,NODE12,NODE13,NODE14,NODE15,NODE16,TOOL
 SG_ section_mask : 32|16@1+ (1,0) [0|65535] "bitmask"  MASTER,NODE1,NODE2,NODE3,NODE4,NODE5,NODE6,NODE7,NODE8,NODE9,NODE10,NODE11,NODE12,NODE13,NODE14,NODE15,NODE16,TOOL
 SG_ seq : 48|8@1+ (1,0) [0|255] ""  MASTER,NODE1,NODE2,NODE3,NODE4,NODE5,NODE6,NODE7,NODE8,NODE9,NODE10,NODE11,NODE12,NODE13,NODE14,NODE15,NODE16,TOOL
 SG_ reserved : 56|8@1+ (1,0) [0|255] ""  MASTER,NODE1,NODE2,NODE3,NODE4,NODE5,NODE6,NODE7,NODE8,NODE9,NODE10,NODE11,NODE12,NODE13,NODE14,NODE15,NODE16,TOOL

BO_ 591 S1_NODE_PRESENCE_15: 8 NODE15
 SG_ payload_b0 : 0|8@1+ (1,0) [0|255] "raw"  MASTER,NODE1,NODE2,NODE3,NODE4,NODE5,NODE6,NODE7,NODE8,NODE9,NODE10,NODE11,NODE12,NODE13,NODE14,NODE15,NODE16,TOOL
 SG_ payload_b1 : 8|8@1+ (1,0) [0|255] "raw"  MASTER,NODE1,NODE2,NODE3,NODE4,NODE5,NODE6,NODE7,NODE8,NODE9,NODE10,NODE11,NODE12,NODE13,NODE14,NODE15,NODE16,TOOL
 SG_ payload_b2 : 16|8@1+ (1,0) [0|255] "raw"  MASTER,NODE1,NODE2,NODE3,NODE4,NODE5,NODE6,NODE7,NODE8,NODE9,NODE10,NODE11,NODE12,NODE13,NODE14,NODE15,NODE16,TOOL
 SG_ payload_b3 : 24|8@1+ (1,0) [0|255] "raw"  MASTER,NODE1,NODE2,NODE3,NODE4,NODE5,NODE6,NODE7,NODE8,NODE9,NODE10,NODE11,NODE12,NODE13,NODE14,NODE15,NODE16,TOOL
 SG_ payload_b4 : 32|8@1+ (1,0) [0|255] "raw"  MASTER,NODE1,NODE2,NODE3,NODE4,NODE5,NODE6,NODE7,NODE8,NODE9,NODE10,NODE11,NODE12,NODE13,NODE14,NODE15,NODE16,TOOL
 SG_ payload_b5 : 40|8@1+ (1,0) [0|255] "raw"  MASTER,NODE1,NODE2,NODE3,NODE4,NODE5,NODE6,NODE7,NODE8,NODE9,NODE10,NODE11,NODE12,NODE13,NODE14,NODE15,NODE16,TOOL
 SG_ payload_b6 : 48|8@1+ (1,0) [0|255] "raw"  MASTER,NODE1,NODE2,NODE3,NODE4,NODE5,NODE6,NODE7,NODE8,NODE9,NODE10,NODE11,NODE12,NODE13,NODE14,NODE15,NODE16,TOOL
 SG_ payload_b7 : 56|8@1+ (1,0) [0|255] "raw"  MASTER,NODE1,NODE2,NODE3,NODE4,NODE5,NODE6,NODE7,NODE8,NODE9,NODE10,NODE11,NODE12,NODE13,NODE14,NODE15,NODE16,TOOL

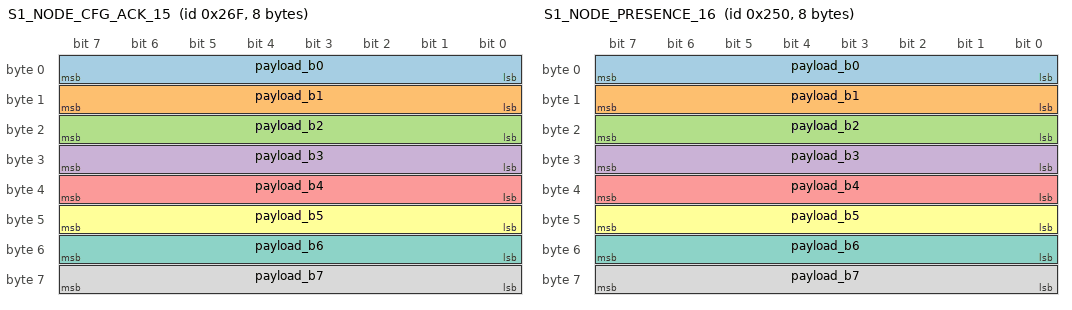
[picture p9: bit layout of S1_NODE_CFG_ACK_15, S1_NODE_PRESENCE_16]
BO_ 623 S1_NODE_CFG_ACK_15: 8 NODE15
 SG_ payload_b0 : 0|8@1+ (1,0) [0|255] "raw"  MASTER,NODE1,NODE2,NODE3,NODE4,NODE5,NODE6,NODE7,NODE8,NODE9,NODE10,NODE11,NODE12,NODE13,NODE14,NODE15,NODE16,TOOL
 SG_ payload_b1 : 8|8@1+ (1,0) [0|255] "raw"  MASTER,NODE1,NODE2,NODE3,NODE4,NODE5,NODE6,NODE7,NODE8,NODE9,NODE10,NODE11,NODE12,NODE13,NODE14,NODE15,NODE16,TOOL
 SG_ payload_b2 : 16|8@1+ (1,0) [0|255] "raw"  MASTER,NODE1,NODE2,NODE3,NODE4,NODE5,NODE6,NODE7,NODE8,NODE9,NODE10,NODE11,NODE12,NODE13,NODE14,NODE15,NODE16,TOOL
 SG_ payload_b3 : 24|8@1+ (1,0) [0|255] "raw"  MASTER,NODE1,NODE2,NODE3,NODE4,NODE5,NODE6,NODE7,NODE8,NODE9,NODE10,NODE11,NODE12,NODE13,NODE14,NODE15,NODE16,TOOL
 SG_ payload_b4 : 32|8@1+ (1,0) [0|255] "raw"  MASTER,NODE1,NODE2,NODE3,NODE4,NODE5,NODE6,NODE7,NODE8,NODE9,NODE10,NODE11,NODE12,NODE13,NODE14,NODE15,NODE16,TOOL
 SG_ payload_b5 : 40|8@1+ (1,0) [0|255] "raw"  MASTER,NODE1,NODE2,NODE3,NODE4,NODE5,NODE6,NODE7,NODE8,NODE9,NODE10,NODE11,NODE12,NODE13,NODE14,NODE15,NODE16,TOOL
 SG_ payload_b6 : 48|8@1+ (1,0) [0|255] "raw"  MASTER,NODE1,NODE2,NODE3,NODE4,NODE5,NODE6,NODE7,NODE8,NODE9,NODE10,NODE11,NODE12,NODE13,NODE14,NODE15,NODE16,TOOL
 SG_ payload_b7 : 56|8@1+ (1,0) [0|255] "raw"  MASTER,NODE1,NODE2,NODE3,NODE4,NODE5,NODE6,NODE7,NODE8,NODE9,NODE10,NODE11,NODE12,NODE13,NODE14,NODE15,NODE16,TOOL

BO_ 655 S1_NODE_STATUS_FAST_15: 8 NODE15
 SG_ status_flags : 0|8@1+ (1,0) [0|255] "bitfield"  MASTER,NODE1,NODE2,NODE3,NODE4,NODE5,NODE6,NODE7,NODE8,NODE9,NODE10,NODE11,NODE12,NODE13,NODE14,NODE15,NODE16,TOOL
 SG_ error_code : 8|8@1+ (1,0) [0|255] ""  MASTER,NODE1,NODE2,NODE3,NODE4,NODE5,NODE6,NODE7,NODE8,NODE9,NODE10,NODE11,NODE12,NODE13,NODE14,NODE15,NODE16,TOOL
 SG_ actual_rpm : 16|16@1+ (1,0) [0|10000] "rpm"  MASTER,NODE1,NODE2,NODE3,NODE4,NODE5,NODE6,NODE7,NODE8,NODE9,NODE10,NODE11,NODE12,NODE13,NODE14,NODE15,NODE16,TOOL
 SG_ actual_pos : 32|16@1+ (1.52587890625e-05,0) [0|0.9999847412109375] "rev"  MASTER,NODE1,NODE2,NODE3,NODE4,NODE5,NODE6,NODE7,NODE8,NODE9,NODE10,NODE11,NODE12,NODE13,NODE14,NODE15,NODE16,TOOL
 SG_ alive_counter : 48|8@1+ (1,0) [0|255] ""  MASTER,NODE1,NODE2,NODE3,NODE4,NODE5,NODE6,NODE7,NODE8,NODE9,NODE10,NODE11,NODE12,NODE13,NODE14,NODE15,NODE16,TOOL
 SG_ sync_error : 56|8@1- (0.00390625,0) [-0.5|0.49609375] "rev"  MASTER,NODE1,NODE2,NODE3,NODE4,NODE5,NODE6,NODE7,NODE8,NODE9,NODE10,NODE11,NODE12,NODE13,NODE14,NODE15,NODE16,TOOL

BO_ 719 S1_NODE_DIAG_15: 8 NODE15
 SG_ bus_voltage : 0|16@1+ (0.1,0) [0|6553.5] "V"  MASTER,NODE1,NODE2,NODE3,NODE4,NODE5,NODE6,NODE7,NODE8,NODE9,NODE10,NODE11,NODE12,NODE13,NODE14,NODE15,NODE16,TOOL
 SG_ motor_current : 16|16@1- (0.1,0) [-3276.8|3276.7] "A"  MASTER,NODE1,NODE2,NODE3,NODE4,NODE5,NODE6,NODE7,NODE8,NODE9,NODE10,NODE11,NODE12,NODE13,NODE14,NODE15,NODE16,TOOL
 SG_ controller_temp : 32|8@1- (1,0) [-128|127] "degC"  MASTER,NODE1,NODE2,NODE3,NODE4,NODE5,NODE6,NODE7,NODE8,NODE9,NODE10,NODE11,NODE12,NODE13,NODE14,NODE15,NODE16,TOOL
 SG_ motor_temp : 40|8@1- (1,0) [-128|127] "degC"  MASTER,NODE1,NODE2,NODE3,NODE4,NODE5,NODE6,NODE7,NODE8,NODE9,NODE10,NODE11,NODE12,NODE13,NODE14,NODE15,NODE16,TOOL
 SG_ fault_flags : 48|8@1+ (1,0) [0|255] "bitfield"  MASTER,NODE1,NODE2,NODE3,NODE4,NODE5,NODE6,NODE7,NODE8,NODE9,NODE10,NODE11,NODE12,NODE13,NODE14,NODE15,NODE16,TOOL
 SG_ warning_flags : 56|8@1+ (1,0) [0|255] "bitfield"  MASTER,NODE1,NODE2,NODE3,NODE4,NODE5,NODE6,NODE7,NODE8,NODE9,NODE10,NODE11,NODE12,NODE13,NODE14,NODE15,NODE16,TOOL

BO_ 544 S1_NODE_CMD_16: 8 MASTER
 SG_ node_command : 0|8@1+ (1,0) [0|255] ""  MASTER,NODE1,NODE2,NODE3,NODE4,NODE5,NODE6,NODE7,NODE8,NODE9,NODE10,NODE11,NODE12,NODE13,NODE14,NODE15,NODE16,TOOL
 SG_ node_flags : 8|8@1+ (1,0) [0|255] "bitfield"  MASTER,NODE1,NODE2,NODE3,NODE4,NODE5,NODE6,NODE7,NODE8,NODE9,NODE10,NODE11,NODE12,NODE13,NODE14,NODE15,NODE16,TOOL
 SG_ trim_rpm : 16|16@1- (0.1,0) [-3276.8|3276.7] "rpm"  MASTER,NODE1,NODE2,NODE3,NODE4,NODE5,NODE6,NODE7,NODE8,NODE9,NODE10,NODE11,NODE12,NODE13,NODE14,NODE15,NODE16,TOOL
 SG_ section_mask : 32|16@1+ (1,0) [0|65535] "bitmask"  MASTER,NODE1,NODE2,NODE3,NODE4,NODE5,NODE6,NODE7,NODE8,NODE9,NODE10,NODE11,NODE12,NODE13,NODE14,NODE15,NODE16,TOOL
 SG_ seq : 48|8@1+ (1,0) [0|255] ""  MASTER,NODE1,NODE2,NODE3,NODE4,NODE5,NODE6,NODE7,NODE8,NODE9,NODE10,NODE11,NODE12,NODE13,NODE14,NODE15,NODE16,TOOL
 SG_ reserved : 56|8@1+ (1,0) [0|255] ""  MASTER,NODE1,NODE2,NODE3,NODE4,NODE5,NODE6,NODE7,NODE8,NODE9,NODE10,NODE11,NODE12,NODE13,NODE14,NODE15,NODE16,TOOL

BO_ 592 S1_NODE_PRESENCE_16: 8 NODE16
 SG_ payload_b0 : 0|8@1+ (1,0) [0|255] "raw"  MASTER,NODE1,NODE2,NODE3,NODE4,NODE5,NODE6,NODE7,NODE8,NODE9,NODE10,NODE11,NODE12,NODE13,NODE14,NODE15,NODE16,TOOL
 SG_ payload_b1 : 8|8@1+ (1,0) [0|255] "raw"  MASTER,NODE1,NODE2,NODE3,NODE4,NODE5,NODE6,NODE7,NODE8,NODE9,NODE10,NODE11,NODE12,NODE13,NODE14,NODE15,NODE16,TOOL
 SG_ payload_b2 : 16|8@1+ (1,0) [0|255] "raw"  MASTER,NODE1,NODE2,NODE3,NODE4,NODE5,NODE6,NODE7,NODE8,NODE9,NODE10,NODE11,NODE12,NODE13,NODE14,NODE15,NODE16,TOOL
 SG_ payload_b3 : 24|8@1+ (1,0) [0|255] "raw"  MASTER,NODE1,NODE2,NODE3,NODE4,NODE5,NODE6,NODE7,NODE8,NODE9,NODE10,NODE11,NODE12,NODE13,NODE14,NODE15,NODE16,TOOL
 SG_ payload_b4 : 32|8@1+ (1,0) [0|255] "raw"  MASTER,NODE1,NODE2,NODE3,NODE4,NODE5,NODE6,NODE7,NODE8,NODE9,NODE10,NODE11,NODE12,NODE13,NODE14,NODE15,NODE16,TOOL
 SG_ payload_b5 : 40|8@1+ (1,0) [0|255] "raw"  MASTER,NODE1,NODE2,NODE3,NODE4,NODE5,NODE6,NODE7,NODE8,NODE9,NODE10,NODE11,NODE12,NODE13,NODE14,NODE15,NODE16,TOOL
 SG_ payload_b6 : 48|8@1+ (1,0) [0|255] "raw"  MASTER,NODE1,NODE2,NODE3,NODE4,NODE5,NODE6,NODE7,NODE8,NODE9,NODE10,NODE11,NODE12,NODE13,NODE14,NODE15,NODE16,TOOL
 SG_ payload_b7 : 56|8@1+ (1,0) [0|255] "raw"  MASTER,NODE1,NODE2,NODE3,NODE4,NODE5,NODE6,NODE7,NODE8,NODE9,NODE10,NODE11,NODE12,NODE13,NODE14,NODE15,NODE16,TOOL

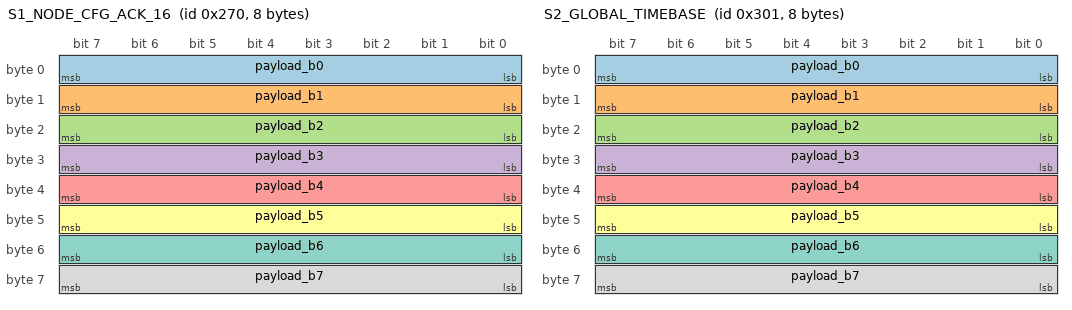
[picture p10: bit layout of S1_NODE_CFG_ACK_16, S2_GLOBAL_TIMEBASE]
BO_ 624 S1_NODE_CFG_ACK_16: 8 NODE16
 SG_ payload_b0 : 0|8@1+ (1,0) [0|255] "raw"  MASTER,NODE1,NODE2,NODE3,NODE4,NODE5,NODE6,NODE7,NODE8,NODE9,NODE10,NODE11,NODE12,NODE13,NODE14,NODE15,NODE16,TOOL
 SG_ payload_b1 : 8|8@1+ (1,0) [0|255] "raw"  MASTER,NODE1,NODE2,NODE3,NODE4,NODE5,NODE6,NODE7,NODE8,NODE9,NODE10,NODE11,NODE12,NODE13,NODE14,NODE15,NODE16,TOOL
 SG_ payload_b2 : 16|8@1+ (1,0) [0|255] "raw"  MASTER,NODE1,NODE2,NODE3,NODE4,NODE5,NODE6,NODE7,NODE8,NODE9,NODE10,NODE11,NODE12,NODE13,NODE14,NODE15,NODE16,TOOL
 SG_ payload_b3 : 24|8@1+ (1,0) [0|255] "raw"  MASTER,NODE1,NODE2,NODE3,NODE4,NODE5,NODE6,NODE7,NODE8,NODE9,NODE10,NODE11,NODE12,NODE13,NODE14,NODE15,NODE16,TOOL
 SG_ payload_b4 : 32|8@1+ (1,0) [0|255] "raw"  MASTER,NODE1,NODE2,NODE3,NODE4,NODE5,NODE6,NODE7,NODE8,NODE9,NODE10,NODE11,NODE12,NODE13,NODE14,NODE15,NODE16,TOOL
 SG_ payload_b5 : 40|8@1+ (1,0) [0|255] "raw"  MASTER,NODE1,NODE2,NODE3,NODE4,NODE5,NODE6,NODE7,NODE8,NODE9,NODE10,NODE11,NODE12,NODE13,NODE14,NODE15,NODE16,TOOL
 SG_ payload_b6 : 48|8@1+ (1,0) [0|255] "raw"  MASTER,NODE1,NODE2,NODE3,NODE4,NODE5,NODE6,NODE7,NODE8,NODE9,NODE10,NODE11,NODE12,NODE13,NODE14,NODE15,NODE16,TOOL
 SG_ payload_b7 : 56|8@1+ (1,0) [0|255] "raw"  MASTER,NODE1,NODE2,NODE3,NODE4,NODE5,NODE6,NODE7,NODE8,NODE9,NODE10,NODE11,NODE12,NODE13,NODE14,NODE15,NODE16,TOOL

BO_ 656 S1_NODE_STATUS_FAST_16: 8 NODE16
 SG_ status_flags : 0|8@1+ (1,0) [0|255] "bitfield"  MASTER,NODE1,NODE2,NODE3,NODE4,NODE5,NODE6,NODE7,NODE8,NODE9,NODE10,NODE11,NODE12,NODE13,NODE14,NODE15,NODE16,TOOL
 SG_ error_code : 8|8@1+ (1,0) [0|255] ""  MASTER,NODE1,NODE2,NODE3,NODE4,NODE5,NODE6,NODE7,NODE8,NODE9,NODE10,NODE11,NODE12,NODE13,NODE14,NODE15,NODE16,TOOL
 SG_ actual_rpm : 16|16@1+ (1,0) [0|10000] "rpm"  MASTER,NODE1,NODE2,NODE3,NODE4,NODE5,NODE6,NODE7,NODE8,NODE9,NODE10,NODE11,NODE12,NODE13,NODE14,NODE15,NODE16,TOOL
 SG_ actual_pos : 32|16@1+ (1.52587890625e-05,0) [0|0.9999847412109375] "rev"  MASTER,NODE1,NODE2,NODE3,NODE4,NODE5,NODE6,NODE7,NODE8,NODE9,NODE10,NODE11,NODE12,NODE13,NODE14,NODE15,NODE16,TOOL
 SG_ alive_counter : 48|8@1+ (1,0) [0|255] ""  MASTER,NODE1,NODE2,NODE3,NODE4,NODE5,NODE6,NODE7,NODE8,NODE9,NODE10,NODE11,NODE12,NODE13,NODE14,NODE15,NODE16,TOOL
 SG_ sync_error : 56|8@1- (0.00390625,0) [-0.5|0.49609375] "rev"  MASTER,NODE1,NODE2,NODE3,NODE4,NODE5,NODE6,NODE7,NODE8,NODE9,NODE10,NODE11,NODE12,NODE13,NODE14,NODE15,NODE16,TOOL

BO_ 720 S1_NODE_DIAG_16: 8 NODE16
 SG_ bus_voltage : 0|16@1+ (0.1,0) [0|6553.5] "V"  MASTER,NODE1,NODE2,NODE3,NODE4,NODE5,NODE6,NODE7,NODE8,NODE9,NODE10,NODE11,NODE12,NODE13,NODE14,NODE15,NODE16,TOOL
 SG_ motor_current : 16|16@1- (0.1,0) [-3276.8|3276.7] "A"  MASTER,NODE1,NODE2,NODE3,NODE4,NODE5,NODE6,NODE7,NODE8,NODE9,NODE10,NODE11,NODE12,NODE13,NODE14,NODE15,NODE16,TOOL
 SG_ controller_temp : 32|8@1- (1,0) [-128|127] "degC"  MASTER,NODE1,NODE2,NODE3,NODE4,NODE5,NODE6,NODE7,NODE8,NODE9,NODE10,NODE11,NODE12,NODE13,NODE14,NODE15,NODE16,TOOL
 SG_ motor_temp : 40|8@1- (1,0) [-128|127] "degC"  MASTER,NODE1,NODE2,NODE3,NODE4,NODE5,NODE6,NODE7,NODE8,NODE9,NODE10,NODE11,NODE12,NODE13,NODE14,NODE15,NODE16,TOOL
 SG_ fault_flags : 48|8@1+ (1,0) [0|255] "bitfield"  MASTER,NODE1,NODE2,NODE3,NODE4,NODE5,NODE6,NODE7,NODE8,NODE9,NODE10,NODE11,NODE12,NODE13,NODE14,NODE15,NODE16,TOOL
 SG_ warning_flags : 56|8@1+ (1,0) [0|255] "bitfield"  MASTER,NODE1,NODE2,NODE3,NODE4,NODE5,NODE6,NODE7,NODE8,NODE9,NODE10,NODE11,NODE12,NODE13,NODE14,NODE15,NODE16,TOOL

BO_ 768 S2_GLOBAL_CONTROL: 8 MASTER
 SG_ system_mode : 0|8@1+ (1,0) [0|255] ""  MASTER,NODE1,NODE2,NODE3,NODE4,NODE5,NODE6,NODE7,NODE8,NODE9,NODE10,NODE11,NODE12,NODE13,NODE14,NODE15,NODE16,TOOL
 SG_ control_flags : 8|8@1+ (1,0) [0|255] "bitfield"  MASTER,NODE1,NODE2,NODE3,NODE4,NODE5,NODE6,NODE7,NODE8,NODE9,NODE10,NODE11,NODE12,NODE13,NODE14,NODE15,NODE16,TOOL
 SG_ ctrl_drive_enable : 8|1@1+ (1,0) [0|1] "bool"  MASTER,NODE1,NODE2,NODE3,NODE4,NODE5,NODE6,NODE7,NODE8,NODE9,NODE10,NODE11,NODE12,NODE13,NODE14,NODE15,NODE16,TOOL
 SG_ ctrl_sync_enable : 9|1@1+ (1,0) [0|1] "bool"  MASTER,NODE1,NODE2,NODE3,NODE4,NODE5,NODE6,NODE7,NODE8,NODE9,NODE10,NODE11,NODE12,NODE13,NODE14,NODE15,NODE16,TOOL
 SG_ ctrl_estop : 10|1@1+ (1,0) [0|1] "bool"  MASTER,NODE1,NODE2,NODE3,NODE4,NODE5,NODE6,NODE7,NODE8,NODE9,NODE10,NODE11,NODE12,NODE13,NODE14,NODE15,NODE16,TOOL
 SG_ ctrl_diag_enable : 11|1@1+ (1,0) [0|1] "bool"  MASTER,NODE1,NODE2,NODE3,NODE4,NODE5,NODE6,NODE7,NODE8,NODE9,NODE10,NODE11,NODE12,NODE13,NODE14,NODE15,NODE16,TOOL
 SG_ base_rpm : 16|16@1+ (1,0) [0|10000] "rpm"  MASTER,NODE1,NODE2,NODE3,NODE4,NODE5,NODE6,NODE7,NODE8,NODE9,NODE10,NODE11,NODE12,NODE13,NODE14,NODE15,NODE16,TOOL
 SG_ sync_pos : 32|16@1+ (1.52587890625e-05,0) [0|0.9999847412109375] "rev"  MASTER,NODE1,NODE2,NODE3,NODE4,NODE5,NODE6,NODE7,NODE8,NODE9,NODE10,NODE11,NODE12,NODE13,NODE14,NODE15,NODE16,TOOL
 SG_ sequence : 48|8@1+ (1,0) [0|255] ""  MASTER,NODE1,NODE2,NODE3,NODE4,NODE5,NODE6,NODE7,NODE8,NODE9,NODE10,NODE11,NODE12,NODE13,NODE14,NODE15,NODE16,TOOL
 SG_ reserved : 56|8@1+ (1,0) [0|255] ""  MASTER,NODE1,NODE2,NODE3,NODE4,NODE5,NODE6,NODE7,NODE8,NODE9,NODE10,NODE11,NODE12,NODE13,NODE14,NODE15,NODE16,TOOL

BO_ 769 S2_GLOBAL_TIMEBASE: 8 MASTER
 SG_ payload_b0 : 0|8@1+ (1,0) [0|255] "raw"  MASTER,NODE1,NODE2,NODE3,NODE4,NODE5,NODE6,NODE7,NODE8,NODE9,NODE10,NODE11,NODE12,NODE13,NODE14,NODE15,NODE16,TOOL
 SG_ payload_b1 : 8|8@1+ (1,0) [0|255] "raw"  MASTER,NODE1,NODE2,NODE3,NODE4,NODE5,NODE6,NODE7,NODE8,NODE9,NODE10,NODE11,NODE12,NODE13,NODE14,NODE15,NODE16,TOOL
 SG_ payload_b2 : 16|8@1+ (1,0) [0|255] "raw"  MASTER,NODE1,NODE2,NODE3,NODE4,NODE5,NODE6,NODE7,NODE8,NODE9,NODE10,NODE11,NODE12,NODE13,NODE14,NODE15,NODE16,TOOL
 SG_ payload_b3 : 24|8@1+ (1,0) [0|255] "raw"  MASTER,NODE1,NODE2,NODE3,NODE4,NODE5,NODE6,NODE7,NODE8,NODE9,NODE10,NODE11,NODE12,NODE13,NODE14,NODE15,NODE16,TOOL
 SG_ payload_b4 : 32|8@1+ (1,0) [0|255] "raw"  MASTER,NODE1,NODE2,NODE3,NODE4,NODE5,NODE6,NODE7,NODE8,NODE9,NODE10,NODE11,NODE12,NODE13,NODE14,NODE15,NODE16,TOOL
 SG_ payload_b5 : 40|8@1+ (1,0) [0|255] "raw"  MASTER,NODE1,NODE2,NODE3,NODE4,NODE5,NODE6,NODE7,NODE8,NODE9,NODE10,NODE11,NODE12,NODE13,NODE14,NODE15,NODE16,TOOL
 SG_ payload_b6 : 48|8@1+ (1,0) [0|255] "raw"  MASTER,NODE1,NODE2,NODE3,NODE4,NODE5,NODE6,NODE7,NODE8,NODE9,NODE10,NODE11,NODE12,NODE13,NODE14,NODE15,NODE16,TOOL
 SG_ payload_b7 : 56|8@1+ (1,0) [0|255] "raw"  MASTER,NODE1,NODE2,NODE3,NODE4,NODE5,NODE6,NODE7,NODE8,NODE9,NODE10,NODE11,NODE12,NODE13,NODE14,NODE15,NODE16,TOOL

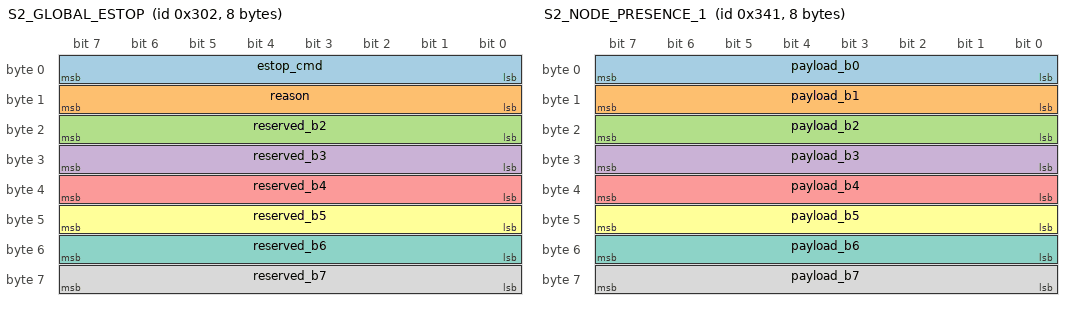
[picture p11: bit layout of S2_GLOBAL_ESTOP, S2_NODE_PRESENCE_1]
BO_ 770 S2_GLOBAL_ESTOP: 8 MASTER
 SG_ estop_cmd : 0|8@1+ (1,0) [0|255] ""  MASTER,NODE1,NODE2,NODE3,NODE4,NODE5,NODE6,NODE7,NODE8,NODE9,NODE10,NODE11,NODE12,NODE13,NODE14,NODE15,NODE16,TOOL
 SG_ reason : 8|8@1+ (1,0) [0|255] ""  MASTER,NODE1,NODE2,NODE3,NODE4,NODE5,NODE6,NODE7,NODE8,NODE9,NODE10,NODE11,NODE12,NODE13,NODE14,NODE15,NODE16,TOOL
 SG_ reserved_b2 : 16|8@1+ (1,0) [0|255] ""  MASTER,NODE1,NODE2,NODE3,NODE4,NODE5,NODE6,NODE7,NODE8,NODE9,NODE10,NODE11,NODE12,NODE13,NODE14,NODE15,NODE16,TOOL
 SG_ reserved_b3 : 24|8@1+ (1,0) [0|255] ""  MASTER,NODE1,NODE2,NODE3,NODE4,NODE5,NODE6,NODE7,NODE8,NODE9,NODE10,NODE11,NODE12,NODE13,NODE14,NODE15,NODE16,TOOL
 SG_ reserved_b4 : 32|8@1+ (1,0) [0|255] ""  MASTER,NODE1,NODE2,NODE3,NODE4,NODE5,NODE6,NODE7,NODE8,NODE9,NODE10,NODE11,NODE12,NODE13,NODE14,NODE15,NODE16,TOOL
 SG_ reserved_b5 : 40|8@1+ (1,0) [0|255] ""  MASTER,NODE1,NODE2,NODE3,NODE4,NODE5,NODE6,NODE7,NODE8,NODE9,NODE10,NODE11,NODE12,NODE13,NODE14,NODE15,NODE16,TOOL
 SG_ reserved_b6 : 48|8@1+ (1,0) [0|255] ""  MASTER,NODE1,NODE2,NODE3,NODE4,NODE5,NODE6,NODE7,NODE8,NODE9,NODE10,NODE11,NODE12,NODE13,NODE14,NODE15,NODE16,TOOL
 SG_ reserved_b7 : 56|8@1+ (1,0) [0|255] ""  MASTER,NODE1,NODE2,NODE3,NODE4,NODE5,NODE6,NODE7,NODE8,NODE9,NODE10,NODE11,NODE12,NODE13,NODE14,NODE15,NODE16,TOOL

BO_ 785 S2_NODE_CMD_1: 8 MASTER
 SG_ node_command : 0|8@1+ (1,0) [0|255] ""  MASTER,NODE1,NODE2,NODE3,NODE4,NODE5,NODE6,NODE7,NODE8,NODE9,NODE10,NODE11,NODE12,NODE13,NODE14,NODE15,NODE16,TOOL
 SG_ node_flags : 8|8@1+ (1,0) [0|255] "bitfield"  MASTER,NODE1,NODE2,NODE3,NODE4,NODE5,NODE6,NODE7,NODE8,NODE9,NODE10,NODE11,NODE12,NODE13,NODE14,NODE15,NODE16,TOOL
 SG_ trim_rpm : 16|16@1- (0.1,0) [-3276.8|3276.7] "rpm"  MASTER,NODE1,NODE2,NODE3,NODE4,NODE5,NODE6,NODE7,NODE8,NODE9,NODE10,NODE11,NODE12,NODE13,NODE14,NODE15,NODE16,TOOL
 SG_ section_mask : 32|16@1+ (1,0) [0|65535] "bitmask"  MASTER,NODE1,NODE2,NODE3,NODE4,NODE5,NODE6,NODE7,NODE8,NODE9,NODE10,NODE11,NODE12,NODE13,NODE14,NODE15,NODE16,TOOL
 SG_ seq : 48|8@1+ (1,0) [0|255] ""  MASTER,NODE1,NODE2,NODE3,NODE4,NODE5,NODE6,NODE7,NODE8,NODE9,NODE10,NODE11,NODE12,NODE13,NODE14,NODE15,NODE16,TOOL
 SG_ reserved : 56|8@1+ (1,0) [0|255] ""  MASTER,NODE1,NODE2,NODE3,NODE4,NODE5,NODE6,NODE7,NODE8,NODE9,NODE10,NODE11,NODE12,NODE13,NODE14,NODE15,NODE16,TOOL

BO_ 833 S2_NODE_PRESENCE_1: 8 NODE1
 SG_ payload_b0 : 0|8@1+ (1,0) [0|255] "raw"  MASTER,NODE1,NODE2,NODE3,NODE4,NODE5,NODE6,NODE7,NODE8,NODE9,NODE10,NODE11,NODE12,NODE13,NODE14,NODE15,NODE16,TOOL
 SG_ payload_b1 : 8|8@1+ (1,0) [0|255] "raw"  MASTER,NODE1,NODE2,NODE3,NODE4,NODE5,NODE6,NODE7,NODE8,NODE9,NODE10,NODE11,NODE12,NODE13,NODE14,NODE15,NODE16,TOOL
 SG_ payload_b2 : 16|8@1+ (1,0) [0|255] "raw"  MASTER,NODE1,NODE2,NODE3,NODE4,NODE5,NODE6,NODE7,NODE8,NODE9,NODE10,NODE11,NODE12,NODE13,NODE14,NODE15,NODE16,TOOL
 SG_ payload_b3 : 24|8@1+ (1,0) [0|255] "raw"  MASTER,NODE1,NODE2,NODE3,NODE4,NODE5,NODE6,NODE7,NODE8,NODE9,NODE10,NODE11,NODE12,NODE13,NODE14,NODE15,NODE16,TOOL
 SG_ payload_b4 : 32|8@1+ (1,0) [0|255] "raw"  MASTER,NODE1,NODE2,NODE3,NODE4,NODE5,NODE6,NODE7,NODE8,NODE9,NODE10,NODE11,NODE12,NODE13,NODE14,NODE15,NODE16,TOOL
 SG_ payload_b5 : 40|8@1+ (1,0) [0|255] "raw"  MASTER,NODE1,NODE2,NODE3,NODE4,NODE5,NODE6,NODE7,NODE8,NODE9,NODE10,NODE11,NODE12,NODE13,NODE14,NODE15,NODE16,TOOL
 SG_ payload_b6 : 48|8@1+ (1,0) [0|255] "raw"  MASTER,NODE1,NODE2,NODE3,NODE4,NODE5,NODE6,NODE7,NODE8,NODE9,NODE10,NODE11,NODE12,NODE13,NODE14,NODE15,NODE16,TOOL
 SG_ payload_b7 : 56|8@1+ (1,0) [0|255] "raw"  MASTER,NODE1,NODE2,NODE3,NODE4,NODE5,NODE6,NODE7,NODE8,NODE9,NODE10,NODE11,NODE12,NODE13,NODE14,NODE15,NODE16,TOOL

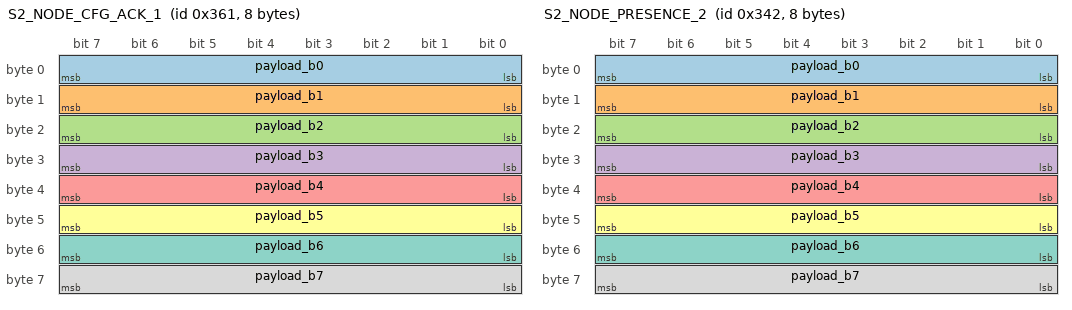
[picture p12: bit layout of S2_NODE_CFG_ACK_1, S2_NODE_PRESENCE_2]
BO_ 865 S2_NODE_CFG_ACK_1: 8 NODE1
 SG_ payload_b0 : 0|8@1+ (1,0) [0|255] "raw"  MASTER,NODE1,NODE2,NODE3,NODE4,NODE5,NODE6,NODE7,NODE8,NODE9,NODE10,NODE11,NODE12,NODE13,NODE14,NODE15,NODE16,TOOL
 SG_ payload_b1 : 8|8@1+ (1,0) [0|255] "raw"  MASTER,NODE1,NODE2,NODE3,NODE4,NODE5,NODE6,NODE7,NODE8,NODE9,NODE10,NODE11,NODE12,NODE13,NODE14,NODE15,NODE16,TOOL
 SG_ payload_b2 : 16|8@1+ (1,0) [0|255] "raw"  MASTER,NODE1,NODE2,NODE3,NODE4,NODE5,NODE6,NODE7,NODE8,NODE9,NODE10,NODE11,NODE12,NODE13,NODE14,NODE15,NODE16,TOOL
 SG_ payload_b3 : 24|8@1+ (1,0) [0|255] "raw"  MASTER,NODE1,NODE2,NODE3,NODE4,NODE5,NODE6,NODE7,NODE8,NODE9,NODE10,NODE11,NODE12,NODE13,NODE14,NODE15,NODE16,TOOL
 SG_ payload_b4 : 32|8@1+ (1,0) [0|255] "raw"  MASTER,NODE1,NODE2,NODE3,NODE4,NODE5,NODE6,NODE7,NODE8,NODE9,NODE10,NODE11,NODE12,NODE13,NODE14,NODE15,NODE16,TOOL
 SG_ payload_b5 : 40|8@1+ (1,0) [0|255] "raw"  MASTER,NODE1,NODE2,NODE3,NODE4,NODE5,NODE6,NODE7,NODE8,NODE9,NODE10,NODE11,NODE12,NODE13,NODE14,NODE15,NODE16,TOOL
 SG_ payload_b6 : 48|8@1+ (1,0) [0|255] "raw"  MASTER,NODE1,NODE2,NODE3,NODE4,NODE5,NODE6,NODE7,NODE8,NODE9,NODE10,NODE11,NODE12,NODE13,NODE14,NODE15,NODE16,TOOL
 SG_ payload_b7 : 56|8@1+ (1,0) [0|255] "raw"  MASTER,NODE1,NODE2,NODE3,NODE4,NODE5,NODE6,NODE7,NODE8,NODE9,NODE10,NODE11,NODE12,NODE13,NODE14,NODE15,NODE16,TOOL

BO_ 897 S2_NODE_STATUS_FAST_1: 8 NODE1
 SG_ status_flags : 0|8@1+ (1,0) [0|255] "bitfield"  MASTER,NODE1,NODE2,NODE3,NODE4,NODE5,NODE6,NODE7,NODE8,NODE9,NODE10,NODE11,NODE12,NODE13,NODE14,NODE15,NODE16,TOOL
 SG_ error_code : 8|8@1+ (1,0) [0|255] ""  MASTER,NODE1,NODE2,NODE3,NODE4,NODE5,NODE6,NODE7,NODE8,NODE9,NODE10,NODE11,NODE12,NODE13,NODE14,NODE15,NODE16,TOOL
 SG_ actual_rpm : 16|16@1+ (1,0) [0|10000] "rpm"  MASTER,NODE1,NODE2,NODE3,NODE4,NODE5,NODE6,NODE7,NODE8,NODE9,NODE10,NODE11,NODE12,NODE13,NODE14,NODE15,NODE16,TOOL
 SG_ actual_pos : 32|16@1+ (1.52587890625e-05,0) [0|0.9999847412109375] "rev"  MASTER,NODE1,NODE2,NODE3,NODE4,NODE5,NODE6,NODE7,NODE8,NODE9,NODE10,NODE11,NODE12,NODE13,NODE14,NODE15,NODE16,TOOL
 SG_ alive_counter : 48|8@1+ (1,0) [0|255] ""  MASTER,NODE1,NODE2,NODE3,NODE4,NODE5,NODE6,NODE7,NODE8,NODE9,NODE10,NODE11,NODE12,NODE13,NODE14,NODE15,NODE16,TOOL
 SG_ sync_error : 56|8@1- (0.00390625,0) [-0.5|0.49609375] "rev"  MASTER,NODE1,NODE2,NODE3,NODE4,NODE5,NODE6,NODE7,NODE8,NODE9,NODE10,NODE11,NODE12,NODE13,NODE14,NODE15,NODE16,TOOL

BO_ 961 S2_NODE_DIAG_1: 8 NODE1
 SG_ bus_voltage : 0|16@1+ (0.1,0) [0|6553.5] "V"  MASTER,NODE1,NODE2,NODE3,NODE4,NODE5,NODE6,NODE7,NODE8,NODE9,NODE10,NODE11,NODE12,NODE13,NODE14,NODE15,NODE16,TOOL
 SG_ motor_current : 16|16@1- (0.1,0) [-3276.8|3276.7] "A"  MASTER,NODE1,NODE2,NODE3,NODE4,NODE5,NODE6,NODE7,NODE8,NODE9,NODE10,NODE11,NODE12,NODE13,NODE14,NODE15,NODE16,TOOL
 SG_ controller_temp : 32|8@1- (1,0) [-128|127] "degC"  MASTER,NODE1,NODE2,NODE3,NODE4,NODE5,NODE6,NODE7,NODE8,NODE9,NODE10,NODE11,NODE12,NODE13,NODE14,NODE15,NODE16,TOOL
 SG_ motor_temp : 40|8@1- (1,0) [-128|127] "degC"  MASTER,NODE1,NODE2,NODE3,NODE4,NODE5,NODE6,NODE7,NODE8,NODE9,NODE10,NODE11,NODE12,NODE13,NODE14,NODE15,NODE16,TOOL
 SG_ fault_flags : 48|8@1+ (1,0) [0|255] "bitfield"  MASTER,NODE1,NODE2,NODE3,NODE4,NODE5,NODE6,NODE7,NODE8,NODE9,NODE10,NODE11,NODE12,NODE13,NODE14,NODE15,NODE16,TOOL
 SG_ warning_flags : 56|8@1+ (1,0) [0|255] "bitfield"  MASTER,NODE1,NODE2,NODE3,NODE4,NODE5,NODE6,NODE7,NODE8,NODE9,NODE10,NODE11,NODE12,NODE13,NODE14,NODE15,NODE16,TOOL

BO_ 786 S2_NODE_CMD_2: 8 MASTER
 SG_ node_command : 0|8@1+ (1,0) [0|255] ""  MASTER,NODE1,NODE2,NODE3,NODE4,NODE5,NODE6,NODE7,NODE8,NODE9,NODE10,NODE11,NODE12,NODE13,NODE14,NODE15,NODE16,TOOL
 SG_ node_flags : 8|8@1+ (1,0) [0|255] "bitfield"  MASTER,NODE1,NODE2,NODE3,NODE4,NODE5,NODE6,NODE7,NODE8,NODE9,NODE10,NODE11,NODE12,NODE13,NODE14,NODE15,NODE16,TOOL
 SG_ trim_rpm : 16|16@1- (0.1,0) [-3276.8|3276.7] "rpm"  MASTER,NODE1,NODE2,NODE3,NODE4,NODE5,NODE6,NODE7,NODE8,NODE9,NODE10,NODE11,NODE12,NODE13,NODE14,NODE15,NODE16,TOOL
 SG_ section_mask : 32|16@1+ (1,0) [0|65535] "bitmask"  MASTER,NODE1,NODE2,NODE3,NODE4,NODE5,NODE6,NODE7,NODE8,NODE9,NODE10,NODE11,NODE12,NODE13,NODE14,NODE15,NODE16,TOOL
 SG_ seq : 48|8@1+ (1,0) [0|255] ""  MASTER,NODE1,NODE2,NODE3,NODE4,NODE5,NODE6,NODE7,NODE8,NODE9,NODE10,NODE11,NODE12,NODE13,NODE14,NODE15,NODE16,TOOL
 SG_ reserved : 56|8@1+ (1,0) [0|255] ""  MASTER,NODE1,NODE2,NODE3,NODE4,NODE5,NODE6,NODE7,NODE8,NODE9,NODE10,NODE11,NODE12,NODE13,NODE14,NODE15,NODE16,TOOL

BO_ 834 S2_NODE_PRESENCE_2: 8 NODE2
 SG_ payload_b0 : 0|8@1+ (1,0) [0|255] "raw"  MASTER,NODE1,NODE2,NODE3,NODE4,NODE5,NODE6,NODE7,NODE8,NODE9,NODE10,NODE11,NODE12,NODE13,NODE14,NODE15,NODE16,TOOL
 SG_ payload_b1 : 8|8@1+ (1,0) [0|255] "raw"  MASTER,NODE1,NODE2,NODE3,NODE4,NODE5,NODE6,NODE7,NODE8,NODE9,NODE10,NODE11,NODE12,NODE13,NODE14,NODE15,NODE16,TOOL
 SG_ payload_b2 : 16|8@1+ (1,0) [0|255] "raw"  MASTER,NODE1,NODE2,NODE3,NODE4,NODE5,NODE6,NODE7,NODE8,NODE9,NODE10,NODE11,NODE12,NODE13,NODE14,NODE15,NODE16,TOOL
 SG_ payload_b3 : 24|8@1+ (1,0) [0|255] "raw"  MASTER,NODE1,NODE2,NODE3,NODE4,NODE5,NODE6,NODE7,NODE8,NODE9,NODE10,NODE11,NODE12,NODE13,NODE14,NODE15,NODE16,TOOL
 SG_ payload_b4 : 32|8@1+ (1,0) [0|255] "raw"  MASTER,NODE1,NODE2,NODE3,NODE4,NODE5,NODE6,NODE7,NODE8,NODE9,NODE10,NODE11,NODE12,NODE13,NODE14,NODE15,NODE16,TOOL
 SG_ payload_b5 : 40|8@1+ (1,0) [0|255] "raw"  MASTER,NODE1,NODE2,NODE3,NODE4,NODE5,NODE6,NODE7,NODE8,NODE9,NODE10,NODE11,NODE12,NODE13,NODE14,NODE15,NODE16,TOOL
 SG_ payload_b6 : 48|8@1+ (1,0) [0|255] "raw"  MASTER,NODE1,NODE2,NODE3,NODE4,NODE5,NODE6,NODE7,NODE8,NODE9,NODE10,NODE11,NODE12,NODE13,NODE14,NODE15,NODE16,TOOL
 SG_ payload_b7 : 56|8@1+ (1,0) [0|255] "raw"  MASTER,NODE1,NODE2,NODE3,NODE4,NODE5,NODE6,NODE7,NODE8,NODE9,NODE10,NODE11,NODE12,NODE13,NODE14,NODE15,NODE16,TOOL

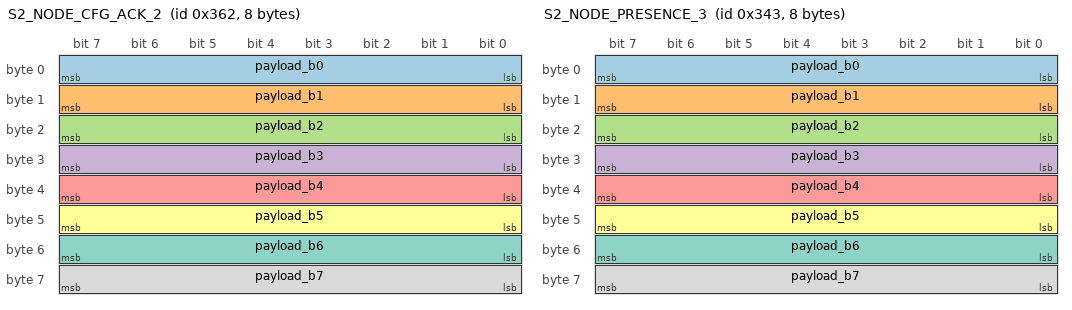
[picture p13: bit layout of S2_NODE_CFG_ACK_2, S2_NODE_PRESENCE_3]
BO_ 866 S2_NODE_CFG_ACK_2: 8 NODE2
 SG_ payload_b0 : 0|8@1+ (1,0) [0|255] "raw"  MASTER,NODE1,NODE2,NODE3,NODE4,NODE5,NODE6,NODE7,NODE8,NODE9,NODE10,NODE11,NODE12,NODE13,NODE14,NODE15,NODE16,TOOL
 SG_ payload_b1 : 8|8@1+ (1,0) [0|255] "raw"  MASTER,NODE1,NODE2,NODE3,NODE4,NODE5,NODE6,NODE7,NODE8,NODE9,NODE10,NODE11,NODE12,NODE13,NODE14,NODE15,NODE16,TOOL
 SG_ payload_b2 : 16|8@1+ (1,0) [0|255] "raw"  MASTER,NODE1,NODE2,NODE3,NODE4,NODE5,NODE6,NODE7,NODE8,NODE9,NODE10,NODE11,NODE12,NODE13,NODE14,NODE15,NODE16,TOOL
 SG_ payload_b3 : 24|8@1+ (1,0) [0|255] "raw"  MASTER,NODE1,NODE2,NODE3,NODE4,NODE5,NODE6,NODE7,NODE8,NODE9,NODE10,NODE11,NODE12,NODE13,NODE14,NODE15,NODE16,TOOL
 SG_ payload_b4 : 32|8@1+ (1,0) [0|255] "raw"  MASTER,NODE1,NODE2,NODE3,NODE4,NODE5,NODE6,NODE7,NODE8,NODE9,NODE10,NODE11,NODE12,NODE13,NODE14,NODE15,NODE16,TOOL
 SG_ payload_b5 : 40|8@1+ (1,0) [0|255] "raw"  MASTER,NODE1,NODE2,NODE3,NODE4,NODE5,NODE6,NODE7,NODE8,NODE9,NODE10,NODE11,NODE12,NODE13,NODE14,NODE15,NODE16,TOOL
 SG_ payload_b6 : 48|8@1+ (1,0) [0|255] "raw"  MASTER,NODE1,NODE2,NODE3,NODE4,NODE5,NODE6,NODE7,NODE8,NODE9,NODE10,NODE11,NODE12,NODE13,NODE14,NODE15,NODE16,TOOL
 SG_ payload_b7 : 56|8@1+ (1,0) [0|255] "raw"  MASTER,NODE1,NODE2,NODE3,NODE4,NODE5,NODE6,NODE7,NODE8,NODE9,NODE10,NODE11,NODE12,NODE13,NODE14,NODE15,NODE16,TOOL

BO_ 898 S2_NODE_STATUS_FAST_2: 8 NODE2
 SG_ status_flags : 0|8@1+ (1,0) [0|255] "bitfield"  MASTER,NODE1,NODE2,NODE3,NODE4,NODE5,NODE6,NODE7,NODE8,NODE9,NODE10,NODE11,NODE12,NODE13,NODE14,NODE15,NODE16,TOOL
 SG_ error_code : 8|8@1+ (1,0) [0|255] ""  MASTER,NODE1,NODE2,NODE3,NODE4,NODE5,NODE6,NODE7,NODE8,NODE9,NODE10,NODE11,NODE12,NODE13,NODE14,NODE15,NODE16,TOOL
 SG_ actual_rpm : 16|16@1+ (1,0) [0|10000] "rpm"  MASTER,NODE1,NODE2,NODE3,NODE4,NODE5,NODE6,NODE7,NODE8,NODE9,NODE10,NODE11,NODE12,NODE13,NODE14,NODE15,NODE16,TOOL
 SG_ actual_pos : 32|16@1+ (1.52587890625e-05,0) [0|0.9999847412109375] "rev"  MASTER,NODE1,NODE2,NODE3,NODE4,NODE5,NODE6,NODE7,NODE8,NODE9,NODE10,NODE11,NODE12,NODE13,NODE14,NODE15,NODE16,TOOL
 SG_ alive_counter : 48|8@1+ (1,0) [0|255] ""  MASTER,NODE1,NODE2,NODE3,NODE4,NODE5,NODE6,NODE7,NODE8,NODE9,NODE10,NODE11,NODE12,NODE13,NODE14,NODE15,NODE16,TOOL
 SG_ sync_error : 56|8@1- (0.00390625,0) [-0.5|0.49609375] "rev"  MASTER,NODE1,NODE2,NODE3,NODE4,NODE5,NODE6,NODE7,NODE8,NODE9,NODE10,NODE11,NODE12,NODE13,NODE14,NODE15,NODE16,TOOL

BO_ 962 S2_NODE_DIAG_2: 8 NODE2
 SG_ bus_voltage : 0|16@1+ (0.1,0) [0|6553.5] "V"  MASTER,NODE1,NODE2,NODE3,NODE4,NODE5,NODE6,NODE7,NODE8,NODE9,NODE10,NODE11,NODE12,NODE13,NODE14,NODE15,NODE16,TOOL
 SG_ motor_current : 16|16@1- (0.1,0) [-3276.8|3276.7] "A"  MASTER,NODE1,NODE2,NODE3,NODE4,NODE5,NODE6,NODE7,NODE8,NODE9,NODE10,NODE11,NODE12,NODE13,NODE14,NODE15,NODE16,TOOL
 SG_ controller_temp : 32|8@1- (1,0) [-128|127] "degC"  MASTER,NODE1,NODE2,NODE3,NODE4,NODE5,NODE6,NODE7,NODE8,NODE9,NODE10,NODE11,NODE12,NODE13,NODE14,NODE15,NODE16,TOOL
 SG_ motor_temp : 40|8@1- (1,0) [-128|127] "degC"  MASTER,NODE1,NODE2,NODE3,NODE4,NODE5,NODE6,NODE7,NODE8,NODE9,NODE10,NODE11,NODE12,NODE13,NODE14,NODE15,NODE16,TOOL
 SG_ fault_flags : 48|8@1+ (1,0) [0|255] "bitfield"  MASTER,NODE1,NODE2,NODE3,NODE4,NODE5,NODE6,NODE7,NODE8,NODE9,NODE10,NODE11,NODE12,NODE13,NODE14,NODE15,NODE16,TOOL
 SG_ warning_flags : 56|8@1+ (1,0) [0|255] "bitfield"  MASTER,NODE1,NODE2,NODE3,NODE4,NODE5,NODE6,NODE7,NODE8,NODE9,NODE10,NODE11,NODE12,NODE13,NODE14,NODE15,NODE16,TOOL

BO_ 787 S2_NODE_CMD_3: 8 MASTER
 SG_ node_command : 0|8@1+ (1,0) [0|255] ""  MASTER,NODE1,NODE2,NODE3,NODE4,NODE5,NODE6,NODE7,NODE8,NODE9,NODE10,NODE11,NODE12,NODE13,NODE14,NODE15,NODE16,TOOL
 SG_ node_flags : 8|8@1+ (1,0) [0|255] "bitfield"  MASTER,NODE1,NODE2,NODE3,NODE4,NODE5,NODE6,NODE7,NODE8,NODE9,NODE10,NODE11,NODE12,NODE13,NODE14,NODE15,NODE16,TOOL
 SG_ trim_rpm : 16|16@1- (0.1,0) [-3276.8|3276.7] "rpm"  MASTER,NODE1,NODE2,NODE3,NODE4,NODE5,NODE6,NODE7,NODE8,NODE9,NODE10,NODE11,NODE12,NODE13,NODE14,NODE15,NODE16,TOOL
 SG_ section_mask : 32|16@1+ (1,0) [0|65535] "bitmask"  MASTER,NODE1,NODE2,NODE3,NODE4,NODE5,NODE6,NODE7,NODE8,NODE9,NODE10,NODE11,NODE12,NODE13,NODE14,NODE15,NODE16,TOOL
 SG_ seq : 48|8@1+ (1,0) [0|255] ""  MASTER,NODE1,NODE2,NODE3,NODE4,NODE5,NODE6,NODE7,NODE8,NODE9,NODE10,NODE11,NODE12,NODE13,NODE14,NODE15,NODE16,TOOL
 SG_ reserved : 56|8@1+ (1,0) [0|255] ""  MASTER,NODE1,NODE2,NODE3,NODE4,NODE5,NODE6,NODE7,NODE8,NODE9,NODE10,NODE11,NODE12,NODE13,NODE14,NODE15,NODE16,TOOL

BO_ 835 S2_NODE_PRESENCE_3: 8 NODE3
 SG_ payload_b0 : 0|8@1+ (1,0) [0|255] "raw"  MASTER,NODE1,NODE2,NODE3,NODE4,NODE5,NODE6,NODE7,NODE8,NODE9,NODE10,NODE11,NODE12,NODE13,NODE14,NODE15,NODE16,TOOL
 SG_ payload_b1 : 8|8@1+ (1,0) [0|255] "raw"  MASTER,NODE1,NODE2,NODE3,NODE4,NODE5,NODE6,NODE7,NODE8,NODE9,NODE10,NODE11,NODE12,NODE13,NODE14,NODE15,NODE16,TOOL
 SG_ payload_b2 : 16|8@1+ (1,0) [0|255] "raw"  MASTER,NODE1,NODE2,NODE3,NODE4,NODE5,NODE6,NODE7,NODE8,NODE9,NODE10,NODE11,NODE12,NODE13,NODE14,NODE15,NODE16,TOOL
 SG_ payload_b3 : 24|8@1+ (1,0) [0|255] "raw"  MASTER,NODE1,NODE2,NODE3,NODE4,NODE5,NODE6,NODE7,NODE8,NODE9,NODE10,NODE11,NODE12,NODE13,NODE14,NODE15,NODE16,TOOL
 SG_ payload_b4 : 32|8@1+ (1,0) [0|255] "raw"  MASTER,NODE1,NODE2,NODE3,NODE4,NODE5,NODE6,NODE7,NODE8,NODE9,NODE10,NODE11,NODE12,NODE13,NODE14,NODE15,NODE16,TOOL
 SG_ payload_b5 : 40|8@1+ (1,0) [0|255] "raw"  MASTER,NODE1,NODE2,NODE3,NODE4,NODE5,NODE6,NODE7,NODE8,NODE9,NODE10,NODE11,NODE12,NODE13,NODE14,NODE15,NODE16,TOOL
 SG_ payload_b6 : 48|8@1+ (1,0) [0|255] "raw"  MASTER,NODE1,NODE2,NODE3,NODE4,NODE5,NODE6,NODE7,NODE8,NODE9,NODE10,NODE11,NODE12,NODE13,NODE14,NODE15,NODE16,TOOL
 SG_ payload_b7 : 56|8@1+ (1,0) [0|255] "raw"  MASTER,NODE1,NODE2,NODE3,NODE4,NODE5,NODE6,NODE7,NODE8,NODE9,NODE10,NODE11,NODE12,NODE13,NODE14,NODE15,NODE16,TOOL

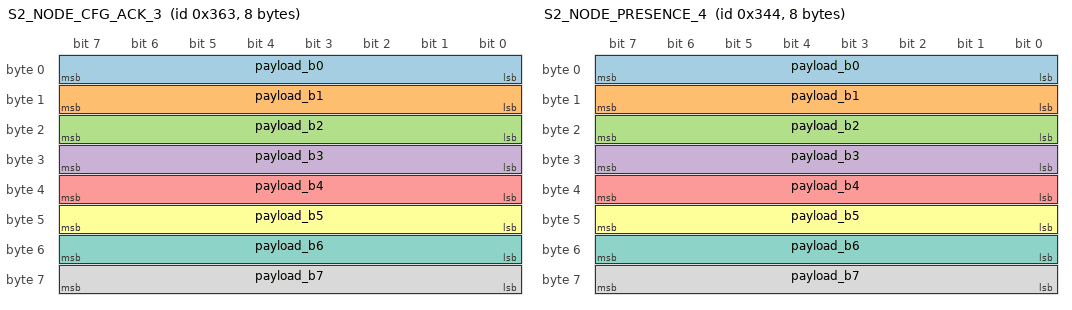
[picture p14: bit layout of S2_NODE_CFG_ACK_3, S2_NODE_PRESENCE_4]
BO_ 867 S2_NODE_CFG_ACK_3: 8 NODE3
 SG_ payload_b0 : 0|8@1+ (1,0) [0|255] "raw"  MASTER,NODE1,NODE2,NODE3,NODE4,NODE5,NODE6,NODE7,NODE8,NODE9,NODE10,NODE11,NODE12,NODE13,NODE14,NODE15,NODE16,TOOL
 SG_ payload_b1 : 8|8@1+ (1,0) [0|255] "raw"  MASTER,NODE1,NODE2,NODE3,NODE4,NODE5,NODE6,NODE7,NODE8,NODE9,NODE10,NODE11,NODE12,NODE13,NODE14,NODE15,NODE16,TOOL
 SG_ payload_b2 : 16|8@1+ (1,0) [0|255] "raw"  MASTER,NODE1,NODE2,NODE3,NODE4,NODE5,NODE6,NODE7,NODE8,NODE9,NODE10,NODE11,NODE12,NODE13,NODE14,NODE15,NODE16,TOOL
 SG_ payload_b3 : 24|8@1+ (1,0) [0|255] "raw"  MASTER,NODE1,NODE2,NODE3,NODE4,NODE5,NODE6,NODE7,NODE8,NODE9,NODE10,NODE11,NODE12,NODE13,NODE14,NODE15,NODE16,TOOL
 SG_ payload_b4 : 32|8@1+ (1,0) [0|255] "raw"  MASTER,NODE1,NODE2,NODE3,NODE4,NODE5,NODE6,NODE7,NODE8,NODE9,NODE10,NODE11,NODE12,NODE13,NODE14,NODE15,NODE16,TOOL
 SG_ payload_b5 : 40|8@1+ (1,0) [0|255] "raw"  MASTER,NODE1,NODE2,NODE3,NODE4,NODE5,NODE6,NODE7,NODE8,NODE9,NODE10,NODE11,NODE12,NODE13,NODE14,NODE15,NODE16,TOOL
 SG_ payload_b6 : 48|8@1+ (1,0) [0|255] "raw"  MASTER,NODE1,NODE2,NODE3,NODE4,NODE5,NODE6,NODE7,NODE8,NODE9,NODE10,NODE11,NODE12,NODE13,NODE14,NODE15,NODE16,TOOL
 SG_ payload_b7 : 56|8@1+ (1,0) [0|255] "raw"  MASTER,NODE1,NODE2,NODE3,NODE4,NODE5,NODE6,NODE7,NODE8,NODE9,NODE10,NODE11,NODE12,NODE13,NODE14,NODE15,NODE16,TOOL

BO_ 899 S2_NODE_STATUS_FAST_3: 8 NODE3
 SG_ status_flags : 0|8@1+ (1,0) [0|255] "bitfield"  MASTER,NODE1,NODE2,NODE3,NODE4,NODE5,NODE6,NODE7,NODE8,NODE9,NODE10,NODE11,NODE12,NODE13,NODE14,NODE15,NODE16,TOOL
 SG_ error_code : 8|8@1+ (1,0) [0|255] ""  MASTER,NODE1,NODE2,NODE3,NODE4,NODE5,NODE6,NODE7,NODE8,NODE9,NODE10,NODE11,NODE12,NODE13,NODE14,NODE15,NODE16,TOOL
 SG_ actual_rpm : 16|16@1+ (1,0) [0|10000] "rpm"  MASTER,NODE1,NODE2,NODE3,NODE4,NODE5,NODE6,NODE7,NODE8,NODE9,NODE10,NODE11,NODE12,NODE13,NODE14,NODE15,NODE16,TOOL
 SG_ actual_pos : 32|16@1+ (1.52587890625e-05,0) [0|0.9999847412109375] "rev"  MASTER,NODE1,NODE2,NODE3,NODE4,NODE5,NODE6,NODE7,NODE8,NODE9,NODE10,NODE11,NODE12,NODE13,NODE14,NODE15,NODE16,TOOL
 SG_ alive_counter : 48|8@1+ (1,0) [0|255] ""  MASTER,NODE1,NODE2,NODE3,NODE4,NODE5,NODE6,NODE7,NODE8,NODE9,NODE10,NODE11,NODE12,NODE13,NODE14,NODE15,NODE16,TOOL
 SG_ sync_error : 56|8@1- (0.00390625,0) [-0.5|0.49609375] "rev"  MASTER,NODE1,NODE2,NODE3,NODE4,NODE5,NODE6,NODE7,NODE8,NODE9,NODE10,NODE11,NODE12,NODE13,NODE14,NODE15,NODE16,TOOL

BO_ 963 S2_NODE_DIAG_3: 8 NODE3
 SG_ bus_voltage : 0|16@1+ (0.1,0) [0|6553.5] "V"  MASTER,NODE1,NODE2,NODE3,NODE4,NODE5,NODE6,NODE7,NODE8,NODE9,NODE10,NODE11,NODE12,NODE13,NODE14,NODE15,NODE16,TOOL
 SG_ motor_current : 16|16@1- (0.1,0) [-3276.8|3276.7] "A"  MASTER,NODE1,NODE2,NODE3,NODE4,NODE5,NODE6,NODE7,NODE8,NODE9,NODE10,NODE11,NODE12,NODE13,NODE14,NODE15,NODE16,TOOL
 SG_ controller_temp : 32|8@1- (1,0) [-128|127] "degC"  MASTER,NODE1,NODE2,NODE3,NODE4,NODE5,NODE6,NODE7,NODE8,NODE9,NODE10,NODE11,NODE12,NODE13,NODE14,NODE15,NODE16,TOOL
 SG_ motor_temp : 40|8@1- (1,0) [-128|127] "degC"  MASTER,NODE1,NODE2,NODE3,NODE4,NODE5,NODE6,NODE7,NODE8,NODE9,NODE10,NODE11,NODE12,NODE13,NODE14,NODE15,NODE16,TOOL
 SG_ fault_flags : 48|8@1+ (1,0) [0|255] "bitfield"  MASTER,NODE1,NODE2,NODE3,NODE4,NODE5,NODE6,NODE7,NODE8,NODE9,NODE10,NODE11,NODE12,NODE13,NODE14,NODE15,NODE16,TOOL
 SG_ warning_flags : 56|8@1+ (1,0) [0|255] "bitfield"  MASTER,NODE1,NODE2,NODE3,NODE4,NODE5,NODE6,NODE7,NODE8,NODE9,NODE10,NODE11,NODE12,NODE13,NODE14,NODE15,NODE16,TOOL

BO_ 788 S2_NODE_CMD_4: 8 MASTER
 SG_ node_command : 0|8@1+ (1,0) [0|255] ""  MASTER,NODE1,NODE2,NODE3,NODE4,NODE5,NODE6,NODE7,NODE8,NODE9,NODE10,NODE11,NODE12,NODE13,NODE14,NODE15,NODE16,TOOL
 SG_ node_flags : 8|8@1+ (1,0) [0|255] "bitfield"  MASTER,NODE1,NODE2,NODE3,NODE4,NODE5,NODE6,NODE7,NODE8,NODE9,NODE10,NODE11,NODE12,NODE13,NODE14,NODE15,NODE16,TOOL
 SG_ trim_rpm : 16|16@1- (0.1,0) [-3276.8|3276.7] "rpm"  MASTER,NODE1,NODE2,NODE3,NODE4,NODE5,NODE6,NODE7,NODE8,NODE9,NODE10,NODE11,NODE12,NODE13,NODE14,NODE15,NODE16,TOOL
 SG_ section_mask : 32|16@1+ (1,0) [0|65535] "bitmask"  MASTER,NODE1,NODE2,NODE3,NODE4,NODE5,NODE6,NODE7,NODE8,NODE9,NODE10,NODE11,NODE12,NODE13,NODE14,NODE15,NODE16,TOOL
 SG_ seq : 48|8@1+ (1,0) [0|255] ""  MASTER,NODE1,NODE2,NODE3,NODE4,NODE5,NODE6,NODE7,NODE8,NODE9,NODE10,NODE11,NODE12,NODE13,NODE14,NODE15,NODE16,TOOL
 SG_ reserved : 56|8@1+ (1,0) [0|255] ""  MASTER,NODE1,NODE2,NODE3,NODE4,NODE5,NODE6,NODE7,NODE8,NODE9,NODE10,NODE11,NODE12,NODE13,NODE14,NODE15,NODE16,TOOL

BO_ 836 S2_NODE_PRESENCE_4: 8 NODE4
 SG_ payload_b0 : 0|8@1+ (1,0) [0|255] "raw"  MASTER,NODE1,NODE2,NODE3,NODE4,NODE5,NODE6,NODE7,NODE8,NODE9,NODE10,NODE11,NODE12,NODE13,NODE14,NODE15,NODE16,TOOL
 SG_ payload_b1 : 8|8@1+ (1,0) [0|255] "raw"  MASTER,NODE1,NODE2,NODE3,NODE4,NODE5,NODE6,NODE7,NODE8,NODE9,NODE10,NODE11,NODE12,NODE13,NODE14,NODE15,NODE16,TOOL
 SG_ payload_b2 : 16|8@1+ (1,0) [0|255] "raw"  MASTER,NODE1,NODE2,NODE3,NODE4,NODE5,NODE6,NODE7,NODE8,NODE9,NODE10,NODE11,NODE12,NODE13,NODE14,NODE15,NODE16,TOOL
 SG_ payload_b3 : 24|8@1+ (1,0) [0|255] "raw"  MASTER,NODE1,NODE2,NODE3,NODE4,NODE5,NODE6,NODE7,NODE8,NODE9,NODE10,NODE11,NODE12,NODE13,NODE14,NODE15,NODE16,TOOL
 SG_ payload_b4 : 32|8@1+ (1,0) [0|255] "raw"  MASTER,NODE1,NODE2,NODE3,NODE4,NODE5,NODE6,NODE7,NODE8,NODE9,NODE10,NODE11,NODE12,NODE13,NODE14,NODE15,NODE16,TOOL
 SG_ payload_b5 : 40|8@1+ (1,0) [0|255] "raw"  MASTER,NODE1,NODE2,NODE3,NODE4,NODE5,NODE6,NODE7,NODE8,NODE9,NODE10,NODE11,NODE12,NODE13,NODE14,NODE15,NODE16,TOOL
 SG_ payload_b6 : 48|8@1+ (1,0) [0|255] "raw"  MASTER,NODE1,NODE2,NODE3,NODE4,NODE5,NODE6,NODE7,NODE8,NODE9,NODE10,NODE11,NODE12,NODE13,NODE14,NODE15,NODE16,TOOL
 SG_ payload_b7 : 56|8@1+ (1,0) [0|255] "raw"  MASTER,NODE1,NODE2,NODE3,NODE4,NODE5,NODE6,NODE7,NODE8,NODE9,NODE10,NODE11,NODE12,NODE13,NODE14,NODE15,NODE16,TOOL

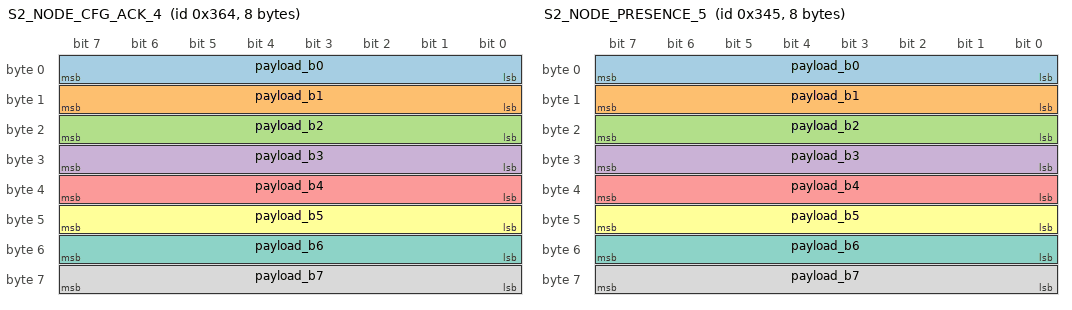
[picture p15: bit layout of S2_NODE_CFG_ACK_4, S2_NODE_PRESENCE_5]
BO_ 868 S2_NODE_CFG_ACK_4: 8 NODE4
 SG_ payload_b0 : 0|8@1+ (1,0) [0|255] "raw"  MASTER,NODE1,NODE2,NODE3,NODE4,NODE5,NODE6,NODE7,NODE8,NODE9,NODE10,NODE11,NODE12,NODE13,NODE14,NODE15,NODE16,TOOL
 SG_ payload_b1 : 8|8@1+ (1,0) [0|255] "raw"  MASTER,NODE1,NODE2,NODE3,NODE4,NODE5,NODE6,NODE7,NODE8,NODE9,NODE10,NODE11,NODE12,NODE13,NODE14,NODE15,NODE16,TOOL
 SG_ payload_b2 : 16|8@1+ (1,0) [0|255] "raw"  MASTER,NODE1,NODE2,NODE3,NODE4,NODE5,NODE6,NODE7,NODE8,NODE9,NODE10,NODE11,NODE12,NODE13,NODE14,NODE15,NODE16,TOOL
 SG_ payload_b3 : 24|8@1+ (1,0) [0|255] "raw"  MASTER,NODE1,NODE2,NODE3,NODE4,NODE5,NODE6,NODE7,NODE8,NODE9,NODE10,NODE11,NODE12,NODE13,NODE14,NODE15,NODE16,TOOL
 SG_ payload_b4 : 32|8@1+ (1,0) [0|255] "raw"  MASTER,NODE1,NODE2,NODE3,NODE4,NODE5,NODE6,NODE7,NODE8,NODE9,NODE10,NODE11,NODE12,NODE13,NODE14,NODE15,NODE16,TOOL
 SG_ payload_b5 : 40|8@1+ (1,0) [0|255] "raw"  MASTER,NODE1,NODE2,NODE3,NODE4,NODE5,NODE6,NODE7,NODE8,NODE9,NODE10,NODE11,NODE12,NODE13,NODE14,NODE15,NODE16,TOOL
 SG_ payload_b6 : 48|8@1+ (1,0) [0|255] "raw"  MASTER,NODE1,NODE2,NODE3,NODE4,NODE5,NODE6,NODE7,NODE8,NODE9,NODE10,NODE11,NODE12,NODE13,NODE14,NODE15,NODE16,TOOL
 SG_ payload_b7 : 56|8@1+ (1,0) [0|255] "raw"  MASTER,NODE1,NODE2,NODE3,NODE4,NODE5,NODE6,NODE7,NODE8,NODE9,NODE10,NODE11,NODE12,NODE13,NODE14,NODE15,NODE16,TOOL

BO_ 900 S2_NODE_STATUS_FAST_4: 8 NODE4
 SG_ status_flags : 0|8@1+ (1,0) [0|255] "bitfield"  MASTER,NODE1,NODE2,NODE3,NODE4,NODE5,NODE6,NODE7,NODE8,NODE9,NODE10,NODE11,NODE12,NODE13,NODE14,NODE15,NODE16,TOOL
 SG_ error_code : 8|8@1+ (1,0) [0|255] ""  MASTER,NODE1,NODE2,NODE3,NODE4,NODE5,NODE6,NODE7,NODE8,NODE9,NODE10,NODE11,NODE12,NODE13,NODE14,NODE15,NODE16,TOOL
 SG_ actual_rpm : 16|16@1+ (1,0) [0|10000] "rpm"  MASTER,NODE1,NODE2,NODE3,NODE4,NODE5,NODE6,NODE7,NODE8,NODE9,NODE10,NODE11,NODE12,NODE13,NODE14,NODE15,NODE16,TOOL
 SG_ actual_pos : 32|16@1+ (1.52587890625e-05,0) [0|0.9999847412109375] "rev"  MASTER,NODE1,NODE2,NODE3,NODE4,NODE5,NODE6,NODE7,NODE8,NODE9,NODE10,NODE11,NODE12,NODE13,NODE14,NODE15,NODE16,TOOL
 SG_ alive_counter : 48|8@1+ (1,0) [0|255] ""  MASTER,NODE1,NODE2,NODE3,NODE4,NODE5,NODE6,NODE7,NODE8,NODE9,NODE10,NODE11,NODE12,NODE13,NODE14,NODE15,NODE16,TOOL
 SG_ sync_error : 56|8@1- (0.00390625,0) [-0.5|0.49609375] "rev"  MASTER,NODE1,NODE2,NODE3,NODE4,NODE5,NODE6,NODE7,NODE8,NODE9,NODE10,NODE11,NODE12,NODE13,NODE14,NODE15,NODE16,TOOL

BO_ 964 S2_NODE_DIAG_4: 8 NODE4
 SG_ bus_voltage : 0|16@1+ (0.1,0) [0|6553.5] "V"  MASTER,NODE1,NODE2,NODE3,NODE4,NODE5,NODE6,NODE7,NODE8,NODE9,NODE10,NODE11,NODE12,NODE13,NODE14,NODE15,NODE16,TOOL
 SG_ motor_current : 16|16@1- (0.1,0) [-3276.8|3276.7] "A"  MASTER,NODE1,NODE2,NODE3,NODE4,NODE5,NODE6,NODE7,NODE8,NODE9,NODE10,NODE11,NODE12,NODE13,NODE14,NODE15,NODE16,TOOL
 SG_ controller_temp : 32|8@1- (1,0) [-128|127] "degC"  MASTER,NODE1,NODE2,NODE3,NODE4,NODE5,NODE6,NODE7,NODE8,NODE9,NODE10,NODE11,NODE12,NODE13,NODE14,NODE15,NODE16,TOOL
 SG_ motor_temp : 40|8@1- (1,0) [-128|127] "degC"  MASTER,NODE1,NODE2,NODE3,NODE4,NODE5,NODE6,NODE7,NODE8,NODE9,NODE10,NODE11,NODE12,NODE13,NODE14,NODE15,NODE16,TOOL
 SG_ fault_flags : 48|8@1+ (1,0) [0|255] "bitfield"  MASTER,NODE1,NODE2,NODE3,NODE4,NODE5,NODE6,NODE7,NODE8,NODE9,NODE10,NODE11,NODE12,NODE13,NODE14,NODE15,NODE16,TOOL
 SG_ warning_flags : 56|8@1+ (1,0) [0|255] "bitfield"  MASTER,NODE1,NODE2,NODE3,NODE4,NODE5,NODE6,NODE7,NODE8,NODE9,NODE10,NODE11,NODE12,NODE13,NODE14,NODE15,NODE16,TOOL

BO_ 789 S2_NODE_CMD_5: 8 MASTER
 SG_ node_command : 0|8@1+ (1,0) [0|255] ""  MASTER,NODE1,NODE2,NODE3,NODE4,NODE5,NODE6,NODE7,NODE8,NODE9,NODE10,NODE11,NODE12,NODE13,NODE14,NODE15,NODE16,TOOL
 SG_ node_flags : 8|8@1+ (1,0) [0|255] "bitfield"  MASTER,NODE1,NODE2,NODE3,NODE4,NODE5,NODE6,NODE7,NODE8,NODE9,NODE10,NODE11,NODE12,NODE13,NODE14,NODE15,NODE16,TOOL
 SG_ trim_rpm : 16|16@1- (0.1,0) [-3276.8|3276.7] "rpm"  MASTER,NODE1,NODE2,NODE3,NODE4,NODE5,NODE6,NODE7,NODE8,NODE9,NODE10,NODE11,NODE12,NODE13,NODE14,NODE15,NODE16,TOOL
 SG_ section_mask : 32|16@1+ (1,0) [0|65535] "bitmask"  MASTER,NODE1,NODE2,NODE3,NODE4,NODE5,NODE6,NODE7,NODE8,NODE9,NODE10,NODE11,NODE12,NODE13,NODE14,NODE15,NODE16,TOOL
 SG_ seq : 48|8@1+ (1,0) [0|255] ""  MASTER,NODE1,NODE2,NODE3,NODE4,NODE5,NODE6,NODE7,NODE8,NODE9,NODE10,NODE11,NODE12,NODE13,NODE14,NODE15,NODE16,TOOL
 SG_ reserved : 56|8@1+ (1,0) [0|255] ""  MASTER,NODE1,NODE2,NODE3,NODE4,NODE5,NODE6,NODE7,NODE8,NODE9,NODE10,NODE11,NODE12,NODE13,NODE14,NODE15,NODE16,TOOL

BO_ 837 S2_NODE_PRESENCE_5: 8 NODE5
 SG_ payload_b0 : 0|8@1+ (1,0) [0|255] "raw"  MASTER,NODE1,NODE2,NODE3,NODE4,NODE5,NODE6,NODE7,NODE8,NODE9,NODE10,NODE11,NODE12,NODE13,NODE14,NODE15,NODE16,TOOL
 SG_ payload_b1 : 8|8@1+ (1,0) [0|255] "raw"  MASTER,NODE1,NODE2,NODE3,NODE4,NODE5,NODE6,NODE7,NODE8,NODE9,NODE10,NODE11,NODE12,NODE13,NODE14,NODE15,NODE16,TOOL
 SG_ payload_b2 : 16|8@1+ (1,0) [0|255] "raw"  MASTER,NODE1,NODE2,NODE3,NODE4,NODE5,NODE6,NODE7,NODE8,NODE9,NODE10,NODE11,NODE12,NODE13,NODE14,NODE15,NODE16,TOOL
 SG_ payload_b3 : 24|8@1+ (1,0) [0|255] "raw"  MASTER,NODE1,NODE2,NODE3,NODE4,NODE5,NODE6,NODE7,NODE8,NODE9,NODE10,NODE11,NODE12,NODE13,NODE14,NODE15,NODE16,TOOL
 SG_ payload_b4 : 32|8@1+ (1,0) [0|255] "raw"  MASTER,NODE1,NODE2,NODE3,NODE4,NODE5,NODE6,NODE7,NODE8,NODE9,NODE10,NODE11,NODE12,NODE13,NODE14,NODE15,NODE16,TOOL
 SG_ payload_b5 : 40|8@1+ (1,0) [0|255] "raw"  MASTER,NODE1,NODE2,NODE3,NODE4,NODE5,NODE6,NODE7,NODE8,NODE9,NODE10,NODE11,NODE12,NODE13,NODE14,NODE15,NODE16,TOOL
 SG_ payload_b6 : 48|8@1+ (1,0) [0|255] "raw"  MASTER,NODE1,NODE2,NODE3,NODE4,NODE5,NODE6,NODE7,NODE8,NODE9,NODE10,NODE11,NODE12,NODE13,NODE14,NODE15,NODE16,TOOL
 SG_ payload_b7 : 56|8@1+ (1,0) [0|255] "raw"  MASTER,NODE1,NODE2,NODE3,NODE4,NODE5,NODE6,NODE7,NODE8,NODE9,NODE10,NODE11,NODE12,NODE13,NODE14,NODE15,NODE16,TOOL

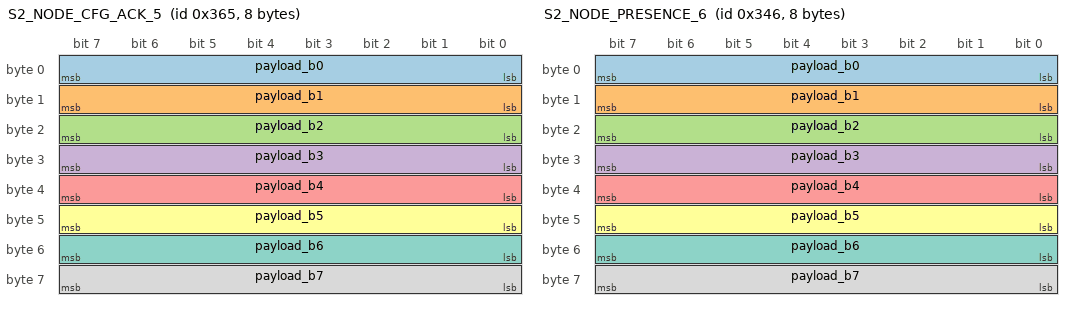
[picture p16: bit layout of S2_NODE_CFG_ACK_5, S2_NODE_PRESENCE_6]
BO_ 869 S2_NODE_CFG_ACK_5: 8 NODE5
 SG_ payload_b0 : 0|8@1+ (1,0) [0|255] "raw"  MASTER,NODE1,NODE2,NODE3,NODE4,NODE5,NODE6,NODE7,NODE8,NODE9,NODE10,NODE11,NODE12,NODE13,NODE14,NODE15,NODE16,TOOL
 SG_ payload_b1 : 8|8@1+ (1,0) [0|255] "raw"  MASTER,NODE1,NODE2,NODE3,NODE4,NODE5,NODE6,NODE7,NODE8,NODE9,NODE10,NODE11,NODE12,NODE13,NODE14,NODE15,NODE16,TOOL
 SG_ payload_b2 : 16|8@1+ (1,0) [0|255] "raw"  MASTER,NODE1,NODE2,NODE3,NODE4,NODE5,NODE6,NODE7,NODE8,NODE9,NODE10,NODE11,NODE12,NODE13,NODE14,NODE15,NODE16,TOOL
 SG_ payload_b3 : 24|8@1+ (1,0) [0|255] "raw"  MASTER,NODE1,NODE2,NODE3,NODE4,NODE5,NODE6,NODE7,NODE8,NODE9,NODE10,NODE11,NODE12,NODE13,NODE14,NODE15,NODE16,TOOL
 SG_ payload_b4 : 32|8@1+ (1,0) [0|255] "raw"  MASTER,NODE1,NODE2,NODE3,NODE4,NODE5,NODE6,NODE7,NODE8,NODE9,NODE10,NODE11,NODE12,NODE13,NODE14,NODE15,NODE16,TOOL
 SG_ payload_b5 : 40|8@1+ (1,0) [0|255] "raw"  MASTER,NODE1,NODE2,NODE3,NODE4,NODE5,NODE6,NODE7,NODE8,NODE9,NODE10,NODE11,NODE12,NODE13,NODE14,NODE15,NODE16,TOOL
 SG_ payload_b6 : 48|8@1+ (1,0) [0|255] "raw"  MASTER,NODE1,NODE2,NODE3,NODE4,NODE5,NODE6,NODE7,NODE8,NODE9,NODE10,NODE11,NODE12,NODE13,NODE14,NODE15,NODE16,TOOL
 SG_ payload_b7 : 56|8@1+ (1,0) [0|255] "raw"  MASTER,NODE1,NODE2,NODE3,NODE4,NODE5,NODE6,NODE7,NODE8,NODE9,NODE10,NODE11,NODE12,NODE13,NODE14,NODE15,NODE16,TOOL

BO_ 901 S2_NODE_STATUS_FAST_5: 8 NODE5
 SG_ status_flags : 0|8@1+ (1,0) [0|255] "bitfield"  MASTER,NODE1,NODE2,NODE3,NODE4,NODE5,NODE6,NODE7,NODE8,NODE9,NODE10,NODE11,NODE12,NODE13,NODE14,NODE15,NODE16,TOOL
 SG_ error_code : 8|8@1+ (1,0) [0|255] ""  MASTER,NODE1,NODE2,NODE3,NODE4,NODE5,NODE6,NODE7,NODE8,NODE9,NODE10,NODE11,NODE12,NODE13,NODE14,NODE15,NODE16,TOOL
 SG_ actual_rpm : 16|16@1+ (1,0) [0|10000] "rpm"  MASTER,NODE1,NODE2,NODE3,NODE4,NODE5,NODE6,NODE7,NODE8,NODE9,NODE10,NODE11,NODE12,NODE13,NODE14,NODE15,NODE16,TOOL
 SG_ actual_pos : 32|16@1+ (1.52587890625e-05,0) [0|0.9999847412109375] "rev"  MASTER,NODE1,NODE2,NODE3,NODE4,NODE5,NODE6,NODE7,NODE8,NODE9,NODE10,NODE11,NODE12,NODE13,NODE14,NODE15,NODE16,TOOL
 SG_ alive_counter : 48|8@1+ (1,0) [0|255] ""  MASTER,NODE1,NODE2,NODE3,NODE4,NODE5,NODE6,NODE7,NODE8,NODE9,NODE10,NODE11,NODE12,NODE13,NODE14,NODE15,NODE16,TOOL
 SG_ sync_error : 56|8@1- (0.00390625,0) [-0.5|0.49609375] "rev"  MASTER,NODE1,NODE2,NODE3,NODE4,NODE5,NODE6,NODE7,NODE8,NODE9,NODE10,NODE11,NODE12,NODE13,NODE14,NODE15,NODE16,TOOL

BO_ 965 S2_NODE_DIAG_5: 8 NODE5
 SG_ bus_voltage : 0|16@1+ (0.1,0) [0|6553.5] "V"  MASTER,NODE1,NODE2,NODE3,NODE4,NODE5,NODE6,NODE7,NODE8,NODE9,NODE10,NODE11,NODE12,NODE13,NODE14,NODE15,NODE16,TOOL
 SG_ motor_current : 16|16@1- (0.1,0) [-3276.8|3276.7] "A"  MASTER,NODE1,NODE2,NODE3,NODE4,NODE5,NODE6,NODE7,NODE8,NODE9,NODE10,NODE11,NODE12,NODE13,NODE14,NODE15,NODE16,TOOL
 SG_ controller_temp : 32|8@1- (1,0) [-128|127] "degC"  MASTER,NODE1,NODE2,NODE3,NODE4,NODE5,NODE6,NODE7,NODE8,NODE9,NODE10,NODE11,NODE12,NODE13,NODE14,NODE15,NODE16,TOOL
 SG_ motor_temp : 40|8@1- (1,0) [-128|127] "degC"  MASTER,NODE1,NODE2,NODE3,NODE4,NODE5,NODE6,NODE7,NODE8,NODE9,NODE10,NODE11,NODE12,NODE13,NODE14,NODE15,NODE16,TOOL
 SG_ fault_flags : 48|8@1+ (1,0) [0|255] "bitfield"  MASTER,NODE1,NODE2,NODE3,NODE4,NODE5,NODE6,NODE7,NODE8,NODE9,NODE10,NODE11,NODE12,NODE13,NODE14,NODE15,NODE16,TOOL
 SG_ warning_flags : 56|8@1+ (1,0) [0|255] "bitfield"  MASTER,NODE1,NODE2,NODE3,NODE4,NODE5,NODE6,NODE7,NODE8,NODE9,NODE10,NODE11,NODE12,NODE13,NODE14,NODE15,NODE16,TOOL

BO_ 790 S2_NODE_CMD_6: 8 MASTER
 SG_ node_command : 0|8@1+ (1,0) [0|255] ""  MASTER,NODE1,NODE2,NODE3,NODE4,NODE5,NODE6,NODE7,NODE8,NODE9,NODE10,NODE11,NODE12,NODE13,NODE14,NODE15,NODE16,TOOL
 SG_ node_flags : 8|8@1+ (1,0) [0|255] "bitfield"  MASTER,NODE1,NODE2,NODE3,NODE4,NODE5,NODE6,NODE7,NODE8,NODE9,NODE10,NODE11,NODE12,NODE13,NODE14,NODE15,NODE16,TOOL
 SG_ trim_rpm : 16|16@1- (0.1,0) [-3276.8|3276.7] "rpm"  MASTER,NODE1,NODE2,NODE3,NODE4,NODE5,NODE6,NODE7,NODE8,NODE9,NODE10,NODE11,NODE12,NODE13,NODE14,NODE15,NODE16,TOOL
 SG_ section_mask : 32|16@1+ (1,0) [0|65535] "bitmask"  MASTER,NODE1,NODE2,NODE3,NODE4,NODE5,NODE6,NODE7,NODE8,NODE9,NODE10,NODE11,NODE12,NODE13,NODE14,NODE15,NODE16,TOOL
 SG_ seq : 48|8@1+ (1,0) [0|255] ""  MASTER,NODE1,NODE2,NODE3,NODE4,NODE5,NODE6,NODE7,NODE8,NODE9,NODE10,NODE11,NODE12,NODE13,NODE14,NODE15,NODE16,TOOL
 SG_ reserved : 56|8@1+ (1,0) [0|255] ""  MASTER,NODE1,NODE2,NODE3,NODE4,NODE5,NODE6,NODE7,NODE8,NODE9,NODE10,NODE11,NODE12,NODE13,NODE14,NODE15,NODE16,TOOL

BO_ 838 S2_NODE_PRESENCE_6: 8 NODE6
 SG_ payload_b0 : 0|8@1+ (1,0) [0|255] "raw"  MASTER,NODE1,NODE2,NODE3,NODE4,NODE5,NODE6,NODE7,NODE8,NODE9,NODE10,NODE11,NODE12,NODE13,NODE14,NODE15,NODE16,TOOL
 SG_ payload_b1 : 8|8@1+ (1,0) [0|255] "raw"  MASTER,NODE1,NODE2,NODE3,NODE4,NODE5,NODE6,NODE7,NODE8,NODE9,NODE10,NODE11,NODE12,NODE13,NODE14,NODE15,NODE16,TOOL
 SG_ payload_b2 : 16|8@1+ (1,0) [0|255] "raw"  MASTER,NODE1,NODE2,NODE3,NODE4,NODE5,NODE6,NODE7,NODE8,NODE9,NODE10,NODE11,NODE12,NODE13,NODE14,NODE15,NODE16,TOOL
 SG_ payload_b3 : 24|8@1+ (1,0) [0|255] "raw"  MASTER,NODE1,NODE2,NODE3,NODE4,NODE5,NODE6,NODE7,NODE8,NODE9,NODE10,NODE11,NODE12,NODE13,NODE14,NODE15,NODE16,TOOL
 SG_ payload_b4 : 32|8@1+ (1,0) [0|255] "raw"  MASTER,NODE1,NODE2,NODE3,NODE4,NODE5,NODE6,NODE7,NODE8,NODE9,NODE10,NODE11,NODE12,NODE13,NODE14,NODE15,NODE16,TOOL
 SG_ payload_b5 : 40|8@1+ (1,0) [0|255] "raw"  MASTER,NODE1,NODE2,NODE3,NODE4,NODE5,NODE6,NODE7,NODE8,NODE9,NODE10,NODE11,NODE12,NODE13,NODE14,NODE15,NODE16,TOOL
 SG_ payload_b6 : 48|8@1+ (1,0) [0|255] "raw"  MASTER,NODE1,NODE2,NODE3,NODE4,NODE5,NODE6,NODE7,NODE8,NODE9,NODE10,NODE11,NODE12,NODE13,NODE14,NODE15,NODE16,TOOL
 SG_ payload_b7 : 56|8@1+ (1,0) [0|255] "raw"  MASTER,NODE1,NODE2,NODE3,NODE4,NODE5,NODE6,NODE7,NODE8,NODE9,NODE10,NODE11,NODE12,NODE13,NODE14,NODE15,NODE16,TOOL

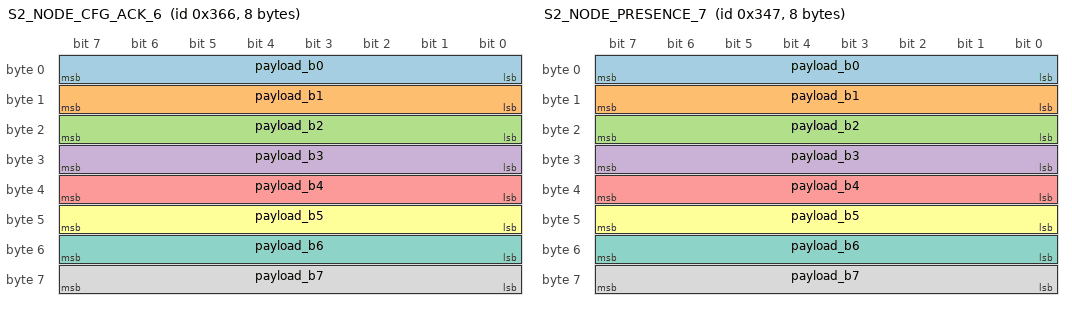
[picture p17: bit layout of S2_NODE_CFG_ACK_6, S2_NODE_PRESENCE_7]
BO_ 870 S2_NODE_CFG_ACK_6: 8 NODE6
 SG_ payload_b0 : 0|8@1+ (1,0) [0|255] "raw"  MASTER,NODE1,NODE2,NODE3,NODE4,NODE5,NODE6,NODE7,NODE8,NODE9,NODE10,NODE11,NODE12,NODE13,NODE14,NODE15,NODE16,TOOL
 SG_ payload_b1 : 8|8@1+ (1,0) [0|255] "raw"  MASTER,NODE1,NODE2,NODE3,NODE4,NODE5,NODE6,NODE7,NODE8,NODE9,NODE10,NODE11,NODE12,NODE13,NODE14,NODE15,NODE16,TOOL
 SG_ payload_b2 : 16|8@1+ (1,0) [0|255] "raw"  MASTER,NODE1,NODE2,NODE3,NODE4,NODE5,NODE6,NODE7,NODE8,NODE9,NODE10,NODE11,NODE12,NODE13,NODE14,NODE15,NODE16,TOOL
 SG_ payload_b3 : 24|8@1+ (1,0) [0|255] "raw"  MASTER,NODE1,NODE2,NODE3,NODE4,NODE5,NODE6,NODE7,NODE8,NODE9,NODE10,NODE11,NODE12,NODE13,NODE14,NODE15,NODE16,TOOL
 SG_ payload_b4 : 32|8@1+ (1,0) [0|255] "raw"  MASTER,NODE1,NODE2,NODE3,NODE4,NODE5,NODE6,NODE7,NODE8,NODE9,NODE10,NODE11,NODE12,NODE13,NODE14,NODE15,NODE16,TOOL
 SG_ payload_b5 : 40|8@1+ (1,0) [0|255] "raw"  MASTER,NODE1,NODE2,NODE3,NODE4,NODE5,NODE6,NODE7,NODE8,NODE9,NODE10,NODE11,NODE12,NODE13,NODE14,NODE15,NODE16,TOOL
 SG_ payload_b6 : 48|8@1+ (1,0) [0|255] "raw"  MASTER,NODE1,NODE2,NODE3,NODE4,NODE5,NODE6,NODE7,NODE8,NODE9,NODE10,NODE11,NODE12,NODE13,NODE14,NODE15,NODE16,TOOL
 SG_ payload_b7 : 56|8@1+ (1,0) [0|255] "raw"  MASTER,NODE1,NODE2,NODE3,NODE4,NODE5,NODE6,NODE7,NODE8,NODE9,NODE10,NODE11,NODE12,NODE13,NODE14,NODE15,NODE16,TOOL

BO_ 902 S2_NODE_STATUS_FAST_6: 8 NODE6
 SG_ status_flags : 0|8@1+ (1,0) [0|255] "bitfield"  MASTER,NODE1,NODE2,NODE3,NODE4,NODE5,NODE6,NODE7,NODE8,NODE9,NODE10,NODE11,NODE12,NODE13,NODE14,NODE15,NODE16,TOOL
 SG_ error_code : 8|8@1+ (1,0) [0|255] ""  MASTER,NODE1,NODE2,NODE3,NODE4,NODE5,NODE6,NODE7,NODE8,NODE9,NODE10,NODE11,NODE12,NODE13,NODE14,NODE15,NODE16,TOOL
 SG_ actual_rpm : 16|16@1+ (1,0) [0|10000] "rpm"  MASTER,NODE1,NODE2,NODE3,NODE4,NODE5,NODE6,NODE7,NODE8,NODE9,NODE10,NODE11,NODE12,NODE13,NODE14,NODE15,NODE16,TOOL
 SG_ actual_pos : 32|16@1+ (1.52587890625e-05,0) [0|0.9999847412109375] "rev"  MASTER,NODE1,NODE2,NODE3,NODE4,NODE5,NODE6,NODE7,NODE8,NODE9,NODE10,NODE11,NODE12,NODE13,NODE14,NODE15,NODE16,TOOL
 SG_ alive_counter : 48|8@1+ (1,0) [0|255] ""  MASTER,NODE1,NODE2,NODE3,NODE4,NODE5,NODE6,NODE7,NODE8,NODE9,NODE10,NODE11,NODE12,NODE13,NODE14,NODE15,NODE16,TOOL
 SG_ sync_error : 56|8@1- (0.00390625,0) [-0.5|0.49609375] "rev"  MASTER,NODE1,NODE2,NODE3,NODE4,NODE5,NODE6,NODE7,NODE8,NODE9,NODE10,NODE11,NODE12,NODE13,NODE14,NODE15,NODE16,TOOL

BO_ 966 S2_NODE_DIAG_6: 8 NODE6
 SG_ bus_voltage : 0|16@1+ (0.1,0) [0|6553.5] "V"  MASTER,NODE1,NODE2,NODE3,NODE4,NODE5,NODE6,NODE7,NODE8,NODE9,NODE10,NODE11,NODE12,NODE13,NODE14,NODE15,NODE16,TOOL
 SG_ motor_current : 16|16@1- (0.1,0) [-3276.8|3276.7] "A"  MASTER,NODE1,NODE2,NODE3,NODE4,NODE5,NODE6,NODE7,NODE8,NODE9,NODE10,NODE11,NODE12,NODE13,NODE14,NODE15,NODE16,TOOL
 SG_ controller_temp : 32|8@1- (1,0) [-128|127] "degC"  MASTER,NODE1,NODE2,NODE3,NODE4,NODE5,NODE6,NODE7,NODE8,NODE9,NODE10,NODE11,NODE12,NODE13,NODE14,NODE15,NODE16,TOOL
 SG_ motor_temp : 40|8@1- (1,0) [-128|127] "degC"  MASTER,NODE1,NODE2,NODE3,NODE4,NODE5,NODE6,NODE7,NODE8,NODE9,NODE10,NODE11,NODE12,NODE13,NODE14,NODE15,NODE16,TOOL
 SG_ fault_flags : 48|8@1+ (1,0) [0|255] "bitfield"  MASTER,NODE1,NODE2,NODE3,NODE4,NODE5,NODE6,NODE7,NODE8,NODE9,NODE10,NODE11,NODE12,NODE13,NODE14,NODE15,NODE16,TOOL
 SG_ warning_flags : 56|8@1+ (1,0) [0|255] "bitfield"  MASTER,NODE1,NODE2,NODE3,NODE4,NODE5,NODE6,NODE7,NODE8,NODE9,NODE10,NODE11,NODE12,NODE13,NODE14,NODE15,NODE16,TOOL

BO_ 791 S2_NODE_CMD_7: 8 MASTER
 SG_ node_command : 0|8@1+ (1,0) [0|255] ""  MASTER,NODE1,NODE2,NODE3,NODE4,NODE5,NODE6,NODE7,NODE8,NODE9,NODE10,NODE11,NODE12,NODE13,NODE14,NODE15,NODE16,TOOL
 SG_ node_flags : 8|8@1+ (1,0) [0|255] "bitfield"  MASTER,NODE1,NODE2,NODE3,NODE4,NODE5,NODE6,NODE7,NODE8,NODE9,NODE10,NODE11,NODE12,NODE13,NODE14,NODE15,NODE16,TOOL
 SG_ trim_rpm : 16|16@1- (0.1,0) [-3276.8|3276.7] "rpm"  MASTER,NODE1,NODE2,NODE3,NODE4,NODE5,NODE6,NODE7,NODE8,NODE9,NODE10,NODE11,NODE12,NODE13,NODE14,NODE15,NODE16,TOOL
 SG_ section_mask : 32|16@1+ (1,0) [0|65535] "bitmask"  MASTER,NODE1,NODE2,NODE3,NODE4,NODE5,NODE6,NODE7,NODE8,NODE9,NODE10,NODE11,NODE12,NODE13,NODE14,NODE15,NODE16,TOOL
 SG_ seq : 48|8@1+ (1,0) [0|255] ""  MASTER,NODE1,NODE2,NODE3,NODE4,NODE5,NODE6,NODE7,NODE8,NODE9,NODE10,NODE11,NODE12,NODE13,NODE14,NODE15,NODE16,TOOL
 SG_ reserved : 56|8@1+ (1,0) [0|255] ""  MASTER,NODE1,NODE2,NODE3,NODE4,NODE5,NODE6,NODE7,NODE8,NODE9,NODE10,NODE11,NODE12,NODE13,NODE14,NODE15,NODE16,TOOL

BO_ 839 S2_NODE_PRESENCE_7: 8 NODE7
 SG_ payload_b0 : 0|8@1+ (1,0) [0|255] "raw"  MASTER,NODE1,NODE2,NODE3,NODE4,NODE5,NODE6,NODE7,NODE8,NODE9,NODE10,NODE11,NODE12,NODE13,NODE14,NODE15,NODE16,TOOL
 SG_ payload_b1 : 8|8@1+ (1,0) [0|255] "raw"  MASTER,NODE1,NODE2,NODE3,NODE4,NODE5,NODE6,NODE7,NODE8,NODE9,NODE10,NODE11,NODE12,NODE13,NODE14,NODE15,NODE16,TOOL
 SG_ payload_b2 : 16|8@1+ (1,0) [0|255] "raw"  MASTER,NODE1,NODE2,NODE3,NODE4,NODE5,NODE6,NODE7,NODE8,NODE9,NODE10,NODE11,NODE12,NODE13,NODE14,NODE15,NODE16,TOOL
 SG_ payload_b3 : 24|8@1+ (1,0) [0|255] "raw"  MASTER,NODE1,NODE2,NODE3,NODE4,NODE5,NODE6,NODE7,NODE8,NODE9,NODE10,NODE11,NODE12,NODE13,NODE14,NODE15,NODE16,TOOL
 SG_ payload_b4 : 32|8@1+ (1,0) [0|255] "raw"  MASTER,NODE1,NODE2,NODE3,NODE4,NODE5,NODE6,NODE7,NODE8,NODE9,NODE10,NODE11,NODE12,NODE13,NODE14,NODE15,NODE16,TOOL
 SG_ payload_b5 : 40|8@1+ (1,0) [0|255] "raw"  MASTER,NODE1,NODE2,NODE3,NODE4,NODE5,NODE6,NODE7,NODE8,NODE9,NODE10,NODE11,NODE12,NODE13,NODE14,NODE15,NODE16,TOOL
 SG_ payload_b6 : 48|8@1+ (1,0) [0|255] "raw"  MASTER,NODE1,NODE2,NODE3,NODE4,NODE5,NODE6,NODE7,NODE8,NODE9,NODE10,NODE11,NODE12,NODE13,NODE14,NODE15,NODE16,TOOL
 SG_ payload_b7 : 56|8@1+ (1,0) [0|255] "raw"  MASTER,NODE1,NODE2,NODE3,NODE4,NODE5,NODE6,NODE7,NODE8,NODE9,NODE10,NODE11,NODE12,NODE13,NODE14,NODE15,NODE16,TOOL

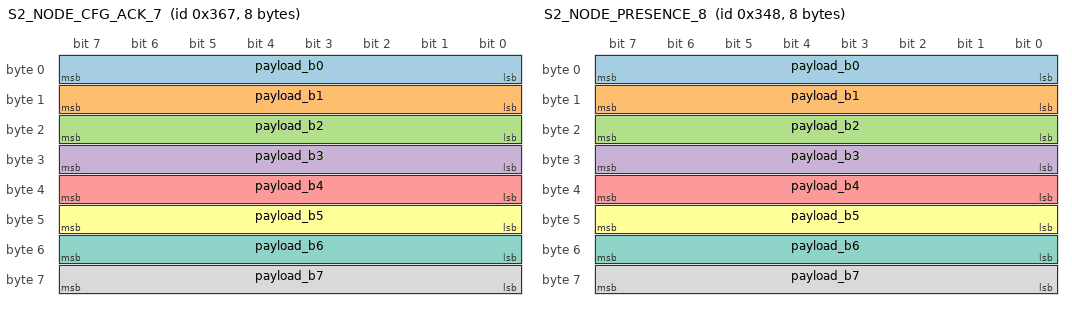
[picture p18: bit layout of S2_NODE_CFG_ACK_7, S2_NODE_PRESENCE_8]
BO_ 871 S2_NODE_CFG_ACK_7: 8 NODE7
 SG_ payload_b0 : 0|8@1+ (1,0) [0|255] "raw"  MASTER,NODE1,NODE2,NODE3,NODE4,NODE5,NODE6,NODE7,NODE8,NODE9,NODE10,NODE11,NODE12,NODE13,NODE14,NODE15,NODE16,TOOL
 SG_ payload_b1 : 8|8@1+ (1,0) [0|255] "raw"  MASTER,NODE1,NODE2,NODE3,NODE4,NODE5,NODE6,NODE7,NODE8,NODE9,NODE10,NODE11,NODE12,NODE13,NODE14,NODE15,NODE16,TOOL
 SG_ payload_b2 : 16|8@1+ (1,0) [0|255] "raw"  MASTER,NODE1,NODE2,NODE3,NODE4,NODE5,NODE6,NODE7,NODE8,NODE9,NODE10,NODE11,NODE12,NODE13,NODE14,NODE15,NODE16,TOOL
 SG_ payload_b3 : 24|8@1+ (1,0) [0|255] "raw"  MASTER,NODE1,NODE2,NODE3,NODE4,NODE5,NODE6,NODE7,NODE8,NODE9,NODE10,NODE11,NODE12,NODE13,NODE14,NODE15,NODE16,TOOL
 SG_ payload_b4 : 32|8@1+ (1,0) [0|255] "raw"  MASTER,NODE1,NODE2,NODE3,NODE4,NODE5,NODE6,NODE7,NODE8,NODE9,NODE10,NODE11,NODE12,NODE13,NODE14,NODE15,NODE16,TOOL
 SG_ payload_b5 : 40|8@1+ (1,0) [0|255] "raw"  MASTER,NODE1,NODE2,NODE3,NODE4,NODE5,NODE6,NODE7,NODE8,NODE9,NODE10,NODE11,NODE12,NODE13,NODE14,NODE15,NODE16,TOOL
 SG_ payload_b6 : 48|8@1+ (1,0) [0|255] "raw"  MASTER,NODE1,NODE2,NODE3,NODE4,NODE5,NODE6,NODE7,NODE8,NODE9,NODE10,NODE11,NODE12,NODE13,NODE14,NODE15,NODE16,TOOL
 SG_ payload_b7 : 56|8@1+ (1,0) [0|255] "raw"  MASTER,NODE1,NODE2,NODE3,NODE4,NODE5,NODE6,NODE7,NODE8,NODE9,NODE10,NODE11,NODE12,NODE13,NODE14,NODE15,NODE16,TOOL

BO_ 903 S2_NODE_STATUS_FAST_7: 8 NODE7
 SG_ status_flags : 0|8@1+ (1,0) [0|255] "bitfield"  MASTER,NODE1,NODE2,NODE3,NODE4,NODE5,NODE6,NODE7,NODE8,NODE9,NODE10,NODE11,NODE12,NODE13,NODE14,NODE15,NODE16,TOOL
 SG_ error_code : 8|8@1+ (1,0) [0|255] ""  MASTER,NODE1,NODE2,NODE3,NODE4,NODE5,NODE6,NODE7,NODE8,NODE9,NODE10,NODE11,NODE12,NODE13,NODE14,NODE15,NODE16,TOOL
 SG_ actual_rpm : 16|16@1+ (1,0) [0|10000] "rpm"  MASTER,NODE1,NODE2,NODE3,NODE4,NODE5,NODE6,NODE7,NODE8,NODE9,NODE10,NODE11,NODE12,NODE13,NODE14,NODE15,NODE16,TOOL
 SG_ actual_pos : 32|16@1+ (1.52587890625e-05,0) [0|0.9999847412109375] "rev"  MASTER,NODE1,NODE2,NODE3,NODE4,NODE5,NODE6,NODE7,NODE8,NODE9,NODE10,NODE11,NODE12,NODE13,NODE14,NODE15,NODE16,TOOL
 SG_ alive_counter : 48|8@1+ (1,0) [0|255] ""  MASTER,NODE1,NODE2,NODE3,NODE4,NODE5,NODE6,NODE7,NODE8,NODE9,NODE10,NODE11,NODE12,NODE13,NODE14,NODE15,NODE16,TOOL
 SG_ sync_error : 56|8@1- (0.00390625,0) [-0.5|0.49609375] "rev"  MASTER,NODE1,NODE2,NODE3,NODE4,NODE5,NODE6,NODE7,NODE8,NODE9,NODE10,NODE11,NODE12,NODE13,NODE14,NODE15,NODE16,TOOL

BO_ 967 S2_NODE_DIAG_7: 8 NODE7
 SG_ bus_voltage : 0|16@1+ (0.1,0) [0|6553.5] "V"  MASTER,NODE1,NODE2,NODE3,NODE4,NODE5,NODE6,NODE7,NODE8,NODE9,NODE10,NODE11,NODE12,NODE13,NODE14,NODE15,NODE16,TOOL
 SG_ motor_current : 16|16@1- (0.1,0) [-3276.8|3276.7] "A"  MASTER,NODE1,NODE2,NODE3,NODE4,NODE5,NODE6,NODE7,NODE8,NODE9,NODE10,NODE11,NODE12,NODE13,NODE14,NODE15,NODE16,TOOL
 SG_ controller_temp : 32|8@1- (1,0) [-128|127] "degC"  MASTER,NODE1,NODE2,NODE3,NODE4,NODE5,NODE6,NODE7,NODE8,NODE9,NODE10,NODE11,NODE12,NODE13,NODE14,NODE15,NODE16,TOOL
 SG_ motor_temp : 40|8@1- (1,0) [-128|127] "degC"  MASTER,NODE1,NODE2,NODE3,NODE4,NODE5,NODE6,NODE7,NODE8,NODE9,NODE10,NODE11,NODE12,NODE13,NODE14,NODE15,NODE16,TOOL
 SG_ fault_flags : 48|8@1+ (1,0) [0|255] "bitfield"  MASTER,NODE1,NODE2,NODE3,NODE4,NODE5,NODE6,NODE7,NODE8,NODE9,NODE10,NODE11,NODE12,NODE13,NODE14,NODE15,NODE16,TOOL
 SG_ warning_flags : 56|8@1+ (1,0) [0|255] "bitfield"  MASTER,NODE1,NODE2,NODE3,NODE4,NODE5,NODE6,NODE7,NODE8,NODE9,NODE10,NODE11,NODE12,NODE13,NODE14,NODE15,NODE16,TOOL

BO_ 792 S2_NODE_CMD_8: 8 MASTER
 SG_ node_command : 0|8@1+ (1,0) [0|255] ""  MASTER,NODE1,NODE2,NODE3,NODE4,NODE5,NODE6,NODE7,NODE8,NODE9,NODE10,NODE11,NODE12,NODE13,NODE14,NODE15,NODE16,TOOL
 SG_ node_flags : 8|8@1+ (1,0) [0|255] "bitfield"  MASTER,NODE1,NODE2,NODE3,NODE4,NODE5,NODE6,NODE7,NODE8,NODE9,NODE10,NODE11,NODE12,NODE13,NODE14,NODE15,NODE16,TOOL
 SG_ trim_rpm : 16|16@1- (0.1,0) [-3276.8|3276.7] "rpm"  MASTER,NODE1,NODE2,NODE3,NODE4,NODE5,NODE6,NODE7,NODE8,NODE9,NODE10,NODE11,NODE12,NODE13,NODE14,NODE15,NODE16,TOOL
 SG_ section_mask : 32|16@1+ (1,0) [0|65535] "bitmask"  MASTER,NODE1,NODE2,NODE3,NODE4,NODE5,NODE6,NODE7,NODE8,NODE9,NODE10,NODE11,NODE12,NODE13,NODE14,NODE15,NODE16,TOOL
 SG_ seq : 48|8@1+ (1,0) [0|255] ""  MASTER,NODE1,NODE2,NODE3,NODE4,NODE5,NODE6,NODE7,NODE8,NODE9,NODE10,NODE11,NODE12,NODE13,NODE14,NODE15,NODE16,TOOL
 SG_ reserved : 56|8@1+ (1,0) [0|255] ""  MASTER,NODE1,NODE2,NODE3,NODE4,NODE5,NODE6,NODE7,NODE8,NODE9,NODE10,NODE11,NODE12,NODE13,NODE14,NODE15,NODE16,TOOL

BO_ 840 S2_NODE_PRESENCE_8: 8 NODE8
 SG_ payload_b0 : 0|8@1+ (1,0) [0|255] "raw"  MASTER,NODE1,NODE2,NODE3,NODE4,NODE5,NODE6,NODE7,NODE8,NODE9,NODE10,NODE11,NODE12,NODE13,NODE14,NODE15,NODE16,TOOL
 SG_ payload_b1 : 8|8@1+ (1,0) [0|255] "raw"  MASTER,NODE1,NODE2,NODE3,NODE4,NODE5,NODE6,NODE7,NODE8,NODE9,NODE10,NODE11,NODE12,NODE13,NODE14,NODE15,NODE16,TOOL
 SG_ payload_b2 : 16|8@1+ (1,0) [0|255] "raw"  MASTER,NODE1,NODE2,NODE3,NODE4,NODE5,NODE6,NODE7,NODE8,NODE9,NODE10,NODE11,NODE12,NODE13,NODE14,NODE15,NODE16,TOOL
 SG_ payload_b3 : 24|8@1+ (1,0) [0|255] "raw"  MASTER,NODE1,NODE2,NODE3,NODE4,NODE5,NODE6,NODE7,NODE8,NODE9,NODE10,NODE11,NODE12,NODE13,NODE14,NODE15,NODE16,TOOL
 SG_ payload_b4 : 32|8@1+ (1,0) [0|255] "raw"  MASTER,NODE1,NODE2,NODE3,NODE4,NODE5,NODE6,NODE7,NODE8,NODE9,NODE10,NODE11,NODE12,NODE13,NODE14,NODE15,NODE16,TOOL
 SG_ payload_b5 : 40|8@1+ (1,0) [0|255] "raw"  MASTER,NODE1,NODE2,NODE3,NODE4,NODE5,NODE6,NODE7,NODE8,NODE9,NODE10,NODE11,NODE12,NODE13,NODE14,NODE15,NODE16,TOOL
 SG_ payload_b6 : 48|8@1+ (1,0) [0|255] "raw"  MASTER,NODE1,NODE2,NODE3,NODE4,NODE5,NODE6,NODE7,NODE8,NODE9,NODE10,NODE11,NODE12,NODE13,NODE14,NODE15,NODE16,TOOL
 SG_ payload_b7 : 56|8@1+ (1,0) [0|255] "raw"  MASTER,NODE1,NODE2,NODE3,NODE4,NODE5,NODE6,NODE7,NODE8,NODE9,NODE10,NODE11,NODE12,NODE13,NODE14,NODE15,NODE16,TOOL

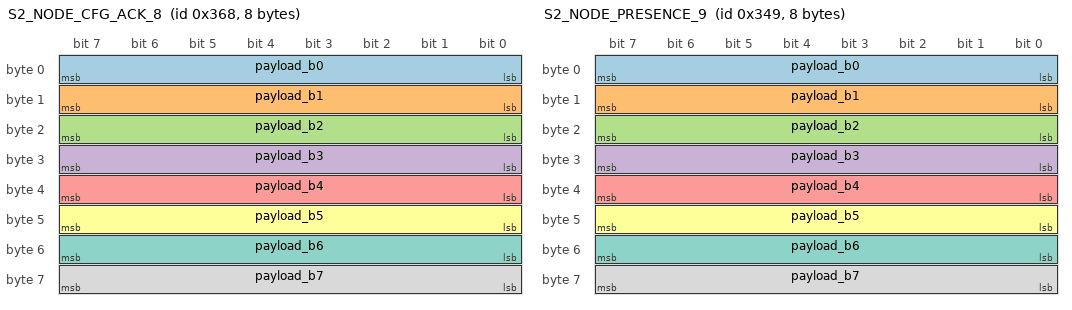
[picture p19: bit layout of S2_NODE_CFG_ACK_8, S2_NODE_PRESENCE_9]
BO_ 872 S2_NODE_CFG_ACK_8: 8 NODE8
 SG_ payload_b0 : 0|8@1+ (1,0) [0|255] "raw"  MASTER,NODE1,NODE2,NODE3,NODE4,NODE5,NODE6,NODE7,NODE8,NODE9,NODE10,NODE11,NODE12,NODE13,NODE14,NODE15,NODE16,TOOL
 SG_ payload_b1 : 8|8@1+ (1,0) [0|255] "raw"  MASTER,NODE1,NODE2,NODE3,NODE4,NODE5,NODE6,NODE7,NODE8,NODE9,NODE10,NODE11,NODE12,NODE13,NODE14,NODE15,NODE16,TOOL
 SG_ payload_b2 : 16|8@1+ (1,0) [0|255] "raw"  MASTER,NODE1,NODE2,NODE3,NODE4,NODE5,NODE6,NODE7,NODE8,NODE9,NODE10,NODE11,NODE12,NODE13,NODE14,NODE15,NODE16,TOOL
 SG_ payload_b3 : 24|8@1+ (1,0) [0|255] "raw"  MASTER,NODE1,NODE2,NODE3,NODE4,NODE5,NODE6,NODE7,NODE8,NODE9,NODE10,NODE11,NODE12,NODE13,NODE14,NODE15,NODE16,TOOL
 SG_ payload_b4 : 32|8@1+ (1,0) [0|255] "raw"  MASTER,NODE1,NODE2,NODE3,NODE4,NODE5,NODE6,NODE7,NODE8,NODE9,NODE10,NODE11,NODE12,NODE13,NODE14,NODE15,NODE16,TOOL
 SG_ payload_b5 : 40|8@1+ (1,0) [0|255] "raw"  MASTER,NODE1,NODE2,NODE3,NODE4,NODE5,NODE6,NODE7,NODE8,NODE9,NODE10,NODE11,NODE12,NODE13,NODE14,NODE15,NODE16,TOOL
 SG_ payload_b6 : 48|8@1+ (1,0) [0|255] "raw"  MASTER,NODE1,NODE2,NODE3,NODE4,NODE5,NODE6,NODE7,NODE8,NODE9,NODE10,NODE11,NODE12,NODE13,NODE14,NODE15,NODE16,TOOL
 SG_ payload_b7 : 56|8@1+ (1,0) [0|255] "raw"  MASTER,NODE1,NODE2,NODE3,NODE4,NODE5,NODE6,NODE7,NODE8,NODE9,NODE10,NODE11,NODE12,NODE13,NODE14,NODE15,NODE16,TOOL

BO_ 904 S2_NODE_STATUS_FAST_8: 8 NODE8
 SG_ status_flags : 0|8@1+ (1,0) [0|255] "bitfield"  MASTER,NODE1,NODE2,NODE3,NODE4,NODE5,NODE6,NODE7,NODE8,NODE9,NODE10,NODE11,NODE12,NODE13,NODE14,NODE15,NODE16,TOOL
 SG_ error_code : 8|8@1+ (1,0) [0|255] ""  MASTER,NODE1,NODE2,NODE3,NODE4,NODE5,NODE6,NODE7,NODE8,NODE9,NODE10,NODE11,NODE12,NODE13,NODE14,NODE15,NODE16,TOOL
 SG_ actual_rpm : 16|16@1+ (1,0) [0|10000] "rpm"  MASTER,NODE1,NODE2,NODE3,NODE4,NODE5,NODE6,NODE7,NODE8,NODE9,NODE10,NODE11,NODE12,NODE13,NODE14,NODE15,NODE16,TOOL
 SG_ actual_pos : 32|16@1+ (1.52587890625e-05,0) [0|0.9999847412109375] "rev"  MASTER,NODE1,NODE2,NODE3,NODE4,NODE5,NODE6,NODE7,NODE8,NODE9,NODE10,NODE11,NODE12,NODE13,NODE14,NODE15,NODE16,TOOL
 SG_ alive_counter : 48|8@1+ (1,0) [0|255] ""  MASTER,NODE1,NODE2,NODE3,NODE4,NODE5,NODE6,NODE7,NODE8,NODE9,NODE10,NODE11,NODE12,NODE13,NODE14,NODE15,NODE16,TOOL
 SG_ sync_error : 56|8@1- (0.00390625,0) [-0.5|0.49609375] "rev"  MASTER,NODE1,NODE2,NODE3,NODE4,NODE5,NODE6,NODE7,NODE8,NODE9,NODE10,NODE11,NODE12,NODE13,NODE14,NODE15,NODE16,TOOL

BO_ 968 S2_NODE_DIAG_8: 8 NODE8
 SG_ bus_voltage : 0|16@1+ (0.1,0) [0|6553.5] "V"  MASTER,NODE1,NODE2,NODE3,NODE4,NODE5,NODE6,NODE7,NODE8,NODE9,NODE10,NODE11,NODE12,NODE13,NODE14,NODE15,NODE16,TOOL
 SG_ motor_current : 16|16@1- (0.1,0) [-3276.8|3276.7] "A"  MASTER,NODE1,NODE2,NODE3,NODE4,NODE5,NODE6,NODE7,NODE8,NODE9,NODE10,NODE11,NODE12,NODE13,NODE14,NODE15,NODE16,TOOL
 SG_ controller_temp : 32|8@1- (1,0) [-128|127] "degC"  MASTER,NODE1,NODE2,NODE3,NODE4,NODE5,NODE6,NODE7,NODE8,NODE9,NODE10,NODE11,NODE12,NODE13,NODE14,NODE15,NODE16,TOOL
 SG_ motor_temp : 40|8@1- (1,0) [-128|127] "degC"  MASTER,NODE1,NODE2,NODE3,NODE4,NODE5,NODE6,NODE7,NODE8,NODE9,NODE10,NODE11,NODE12,NODE13,NODE14,NODE15,NODE16,TOOL
 SG_ fault_flags : 48|8@1+ (1,0) [0|255] "bitfield"  MASTER,NODE1,NODE2,NODE3,NODE4,NODE5,NODE6,NODE7,NODE8,NODE9,NODE10,NODE11,NODE12,NODE13,NODE14,NODE15,NODE16,TOOL
 SG_ warning_flags : 56|8@1+ (1,0) [0|255] "bitfield"  MASTER,NODE1,NODE2,NODE3,NODE4,NODE5,NODE6,NODE7,NODE8,NODE9,NODE10,NODE11,NODE12,NODE13,NODE14,NODE15,NODE16,TOOL

BO_ 793 S2_NODE_CMD_9: 8 MASTER
 SG_ node_command : 0|8@1+ (1,0) [0|255] ""  MASTER,NODE1,NODE2,NODE3,NODE4,NODE5,NODE6,NODE7,NODE8,NODE9,NODE10,NODE11,NODE12,NODE13,NODE14,NODE15,NODE16,TOOL
 SG_ node_flags : 8|8@1+ (1,0) [0|255] "bitfield"  MASTER,NODE1,NODE2,NODE3,NODE4,NODE5,NODE6,NODE7,NODE8,NODE9,NODE10,NODE11,NODE12,NODE13,NODE14,NODE15,NODE16,TOOL
 SG_ trim_rpm : 16|16@1- (0.1,0) [-3276.8|3276.7] "rpm"  MASTER,NODE1,NODE2,NODE3,NODE4,NODE5,NODE6,NODE7,NODE8,NODE9,NODE10,NODE11,NODE12,NODE13,NODE14,NODE15,NODE16,TOOL
 SG_ section_mask : 32|16@1+ (1,0) [0|65535] "bitmask"  MASTER,NODE1,NODE2,NODE3,NODE4,NODE5,NODE6,NODE7,NODE8,NODE9,NODE10,NODE11,NODE12,NODE13,NODE14,NODE15,NODE16,TOOL
 SG_ seq : 48|8@1+ (1,0) [0|255] ""  MASTER,NODE1,NODE2,NODE3,NODE4,NODE5,NODE6,NODE7,NODE8,NODE9,NODE10,NODE11,NODE12,NODE13,NODE14,NODE15,NODE16,TOOL
 SG_ reserved : 56|8@1+ (1,0) [0|255] ""  MASTER,NODE1,NODE2,NODE3,NODE4,NODE5,NODE6,NODE7,NODE8,NODE9,NODE10,NODE11,NODE12,NODE13,NODE14,NODE15,NODE16,TOOL

BO_ 841 S2_NODE_PRESENCE_9: 8 NODE9
 SG_ payload_b0 : 0|8@1+ (1,0) [0|255] "raw"  MASTER,NODE1,NODE2,NODE3,NODE4,NODE5,NODE6,NODE7,NODE8,NODE9,NODE10,NODE11,NODE12,NODE13,NODE14,NODE15,NODE16,TOOL
 SG_ payload_b1 : 8|8@1+ (1,0) [0|255] "raw"  MASTER,NODE1,NODE2,NODE3,NODE4,NODE5,NODE6,NODE7,NODE8,NODE9,NODE10,NODE11,NODE12,NODE13,NODE14,NODE15,NODE16,TOOL
 SG_ payload_b2 : 16|8@1+ (1,0) [0|255] "raw"  MASTER,NODE1,NODE2,NODE3,NODE4,NODE5,NODE6,NODE7,NODE8,NODE9,NODE10,NODE11,NODE12,NODE13,NODE14,NODE15,NODE16,TOOL
 SG_ payload_b3 : 24|8@1+ (1,0) [0|255] "raw"  MASTER,NODE1,NODE2,NODE3,NODE4,NODE5,NODE6,NODE7,NODE8,NODE9,NODE10,NODE11,NODE12,NODE13,NODE14,NODE15,NODE16,TOOL
 SG_ payload_b4 : 32|8@1+ (1,0) [0|255] "raw"  MASTER,NODE1,NODE2,NODE3,NODE4,NODE5,NODE6,NODE7,NODE8,NODE9,NODE10,NODE11,NODE12,NODE13,NODE14,NODE15,NODE16,TOOL
 SG_ payload_b5 : 40|8@1+ (1,0) [0|255] "raw"  MASTER,NODE1,NODE2,NODE3,NODE4,NODE5,NODE6,NODE7,NODE8,NODE9,NODE10,NODE11,NODE12,NODE13,NODE14,NODE15,NODE16,TOOL
 SG_ payload_b6 : 48|8@1+ (1,0) [0|255] "raw"  MASTER,NODE1,NODE2,NODE3,NODE4,NODE5,NODE6,NODE7,NODE8,NODE9,NODE10,NODE11,NODE12,NODE13,NODE14,NODE15,NODE16,TOOL
 SG_ payload_b7 : 56|8@1+ (1,0) [0|255] "raw"  MASTER,NODE1,NODE2,NODE3,NODE4,NODE5,NODE6,NODE7,NODE8,NODE9,NODE10,NODE11,NODE12,NODE13,NODE14,NODE15,NODE16,TOOL

BO_ 873 S2_NODE_CFG_ACK_9: 8 NODE9
 SG_ payload_b0 : 0|8@1+ (1,0) [0|255] "raw"  MASTER,NODE1,NODE2,NODE3,NODE4,NODE5,NODE6,NODE7,NODE8,NODE9,NODE10,NODE11,NODE12,NODE13,NODE14,NODE15,NODE16,TOOL
 SG_ payload_b1 : 8|8@1+ (1,0) [0|255] "raw"  MASTER,NODE1,NODE2,NODE3,NODE4,NODE5,NODE6,NODE7,NODE8,NODE9,NODE10,NODE11,NODE12,NODE13,NODE14,NODE15,NODE16,TOOL
 SG_ payload_b2 : 16|8@1+ (1,0) [0|255] "raw"  MASTER,NODE1,NODE2,NODE3,NODE4,NODE5,NODE6,NODE7,NODE8,NODE9,NODE10,NODE11,NODE12,NODE13,NODE14,NODE15,NODE16,TOOL
 SG_ payload_b3 : 24|8@1+ (1,0) [0|255] "raw"  MASTER,NODE1,NODE2,NODE3,NODE4,NODE5,NODE6,NODE7,NODE8,NODE9,NODE10,NODE11,NODE12,NODE13,NODE14,NODE15,NODE16,TOOL
 SG_ payload_b4 : 32|8@1+ (1,0) [0|255] "raw"  MASTER,NODE1,NODE2,NODE3,NODE4,NODE5,NODE6,NODE7,NODE8,NODE9,NODE10,NODE11,NODE12,NODE13,NODE14,NODE15,NODE16,TOOL
 SG_ payload_b5 : 40|8@1+ (1,0) [0|255] "raw"  MASTER,NODE1,NODE2,NODE3,NODE4,NODE5,NODE6,NODE7,NODE8,NODE9,NODE10,NODE11,NODE12,NODE13,NODE14,NODE15,NODE16,TOOL
 SG_ payload_b6 : 48|8@1+ (1,0) [0|255] "raw"  MASTER,NODE1,NODE2,NODE3,NODE4,NODE5,NODE6,NODE7,NODE8,NODE9,NODE10,NODE11,NODE12,NODE13,NODE14,NODE15,NODE16,TOOL
 SG_ payload_b7 : 56|8@1+ (1,0) [0|255] "raw"  MASTER,NODE1,NODE2,NODE3,NODE4,NODE5,NODE6,NODE7,NODE8,NODE9,NODE10,NODE11,NODE12,NODE13,NODE14,NODE15,NODE16,TOOL

BO_ 905 S2_NODE_STATUS_FAST_9: 8 NODE9
 SG_ status_flags : 0|8@1+ (1,0) [0|255] "bitfield"  MASTER,NODE1,NODE2,NODE3,NODE4,NODE5,NODE6,NODE7,NODE8,NODE9,NODE10,NODE11,NODE12,NODE13,NODE14,NODE15,NODE16,TOOL
 SG_ error_code : 8|8@1+ (1,0) [0|255] ""  MASTER,NODE1,NODE2,NODE3,NODE4,NODE5,NODE6,NODE7,NODE8,NODE9,NODE10,NODE11,NODE12,NODE13,NODE14,NODE15,NODE16,TOOL
 SG_ actual_rpm : 16|16@1+ (1,0) [0|10000] "rpm"  MASTER,NODE1,NODE2,NODE3,NODE4,NODE5,NODE6,NODE7,NODE8,NODE9,NODE10,NODE11,NODE12,NODE13,NODE14,NODE15,NODE16,TOOL
 SG_ actual_pos : 32|16@1+ (1.52587890625e-05,0) [0|0.9999847412109375] "rev"  MASTER,NODE1,NODE2,NODE3,NODE4,NODE5,NODE6,NODE7,NODE8,NODE9,NODE10,NODE11,NODE12,NODE13,NODE14,NODE15,NODE16,TOOL
 SG_ alive_counter : 48|8@1+ (1,0) [0|255] ""  MASTER,NODE1,NODE2,NODE3,NODE4,NODE5,NODE6,NODE7,NODE8,NODE9,NODE10,NODE11,NODE12,NODE13,NODE14,NODE15,NODE16,TOOL
 SG_ sync_error : 56|8@1- (0.00390625,0) [-0.5|0.49609375] "rev"  MASTER,NODE1,NODE2,NODE3,NODE4,NODE5,NODE6,NODE7,NODE8,NODE9,NODE10,NODE11,NODE12,NODE13,NODE14,NODE15,NODE16,TOOL

BO_ 969 S2_NODE_DIAG_9: 8 NODE9
 SG_ bus_voltage : 0|16@1+ (0.1,0) [0|6553.5] "V"  MASTER,NODE1,NODE2,NODE3,NODE4,NODE5,NODE6,NODE7,NODE8,NODE9,NODE10,NODE11,NODE12,NODE13,NODE14,NODE15,NODE16,TOOL
 SG_ motor_current : 16|16@1- (0.1,0) [-3276.8|3276.7] "A"  MASTER,NODE1,NODE2,NODE3,NODE4,NODE5,NODE6,NODE7,NODE8,NODE9,NODE10,NODE11,NODE12,NODE13,NODE14,NODE15,NODE16,TOOL
 SG_ controller_temp : 32|8@1- (1,0) [-128|127] "degC"  MASTER,NODE1,NODE2,NODE3,NODE4,NODE5,NODE6,NODE7,NODE8,NODE9,NODE10,NODE11,NODE12,NODE13,NODE14,NODE15,NODE16,TOOL
 SG_ motor_temp : 40|8@1- (1,0) [-128|127] "degC"  MASTER,NODE1,NODE2,NODE3,NODE4,NODE5,NODE6,NODE7,NODE8,NODE9,NODE10,NODE11,NODE12,NODE13,NODE14,NODE15,NODE16,TOOL
 SG_ fault_flags : 48|8@1+ (1,0) [0|255] "bitfield"  MASTER,NODE1,NODE2,NODE3,NODE4,NODE5,NODE6,NODE7,NODE8,NODE9,NODE10,NODE11,NODE12,NODE13,NODE14,NODE15,NODE16,TOOL
 SG_ warning_flags : 56|8@1+ (1,0) [0|255] "bitfield"  MASTER,NODE1,NODE2,NODE3,NODE4,NODE5,NODE6,NODE7,NODE8,NODE9,NODE10,NODE11,NODE12,NODE13,NODE14,NODE15,NODE16,TOOL

BO_ 794 S2_NODE_CMD_10: 8 MASTER
 SG_ node_command : 0|8@1+ (1,0) [0|255] ""  MASTER,NODE1,NODE2,NODE3,NODE4,NODE5,NODE6,NODE7,NODE8,NODE9,NODE10,NODE11,NODE12,NODE13,NODE14,NODE15,NODE16,TOOL
 SG_ node_flags : 8|8@1+ (1,0) [0|255] "bitfield"  MASTER,NODE1,NODE2,NODE3,NODE4,NODE5,NODE6,NODE7,NODE8,NODE9,NODE10,NODE11,NODE12,NODE13,NODE14,NODE15,NODE16,TOOL
 SG_ trim_rpm : 16|16@1- (0.1,0) [-3276.8|3276.7] "rpm"  MASTER,NODE1,NODE2,NODE3,NODE4,NODE5,NODE6,NODE7,NODE8,NODE9,NODE10,NODE11,NODE12,NODE13,NODE14,NODE15,NODE16,TOOL
 SG_ section_mask : 32|16@1+ (1,0) [0|65535] "bitmask"  MASTER,NODE1,NODE2,NODE3,NODE4,NODE5,NODE6,NODE7,NODE8,NODE9,NODE10,NODE11,NODE12,NODE13,NODE14,NODE15,NODE16,TOOL
 SG_ seq : 48|8@1+ (1,0) [0|255] ""  MASTER,NODE1,NODE2,NODE3,NODE4,NODE5,NODE6,NODE7,NODE8,NODE9,NODE10,NODE11,NODE12,NODE13,NODE14,NODE15,NODE16,TOOL
 SG_ reserved : 56|8@1+ (1,0) [0|255] ""  MASTER,NODE1,NODE2,NODE3,NODE4,NODE5,NODE6,NODE7,NODE8,NODE9,NODE10,NODE11,NODE12,NODE13,NODE14,NODE15,NODE16,TOOL

BO_ 842 S2_NODE_PRESENCE_10: 8 NODE10
 SG_ payload_b0 : 0|8@1+ (1,0) [0|255] "raw"  MASTER,NODE1,NODE2,NODE3,NODE4,NODE5,NODE6,NODE7,NODE8,NODE9,NODE10,NODE11,NODE12,NODE13,NODE14,NODE15,NODE16,TOOL
 SG_ payload_b1 : 8|8@1+ (1,0) [0|255] "raw"  MASTER,NODE1,NODE2,NODE3,NODE4,NODE5,NODE6,NODE7,NODE8,NODE9,NODE10,NODE11,NODE12,NODE13,NODE14,NODE15,NODE16,TOOL
 SG_ payload_b2 : 16|8@1+ (1,0) [0|255] "raw"  MASTER,NODE1,NODE2,NODE3,NODE4,NODE5,NODE6,NODE7,NODE8,NODE9,NODE10,NODE11,NODE12,NODE13,NODE14,NODE15,NODE16,TOOL
 SG_ payload_b3 : 24|8@1+ (1,0) [0|255] "raw"  MASTER,NODE1,NODE2,NODE3,NODE4,NODE5,NODE6,NODE7,NODE8,NODE9,NODE10,NODE11,NODE12,NODE13,NODE14,NODE15,NODE16,TOOL
 SG_ payload_b4 : 32|8@1+ (1,0) [0|255] "raw"  MASTER,NODE1,NODE2,NODE3,NODE4,NODE5,NODE6,NODE7,NODE8,NODE9,NODE10,NODE11,NODE12,NODE13,NODE14,NODE15,NODE16,TOOL
 SG_ payload_b5 : 40|8@1+ (1,0) [0|255] "raw"  MASTER,NODE1,NODE2,NODE3,NODE4,NODE5,NODE6,NODE7,NODE8,NODE9,NODE10,NODE11,NODE12,NODE13,NODE14,NODE15,NODE16,TOOL
 SG_ payload_b6 : 48|8@1+ (1,0) [0|255] "raw"  MASTER,NODE1,NODE2,NODE3,NODE4,NODE5,NODE6,NODE7,NODE8,NODE9,NODE10,NODE11,NODE12,NODE13,NODE14,NODE15,NODE16,TOOL
 SG_ payload_b7 : 56|8@1+ (1,0) [0|255] "raw"  MASTER,NODE1,NODE2,NODE3,NODE4,NODE5,NODE6,NODE7,NODE8,NODE9,NODE10,NODE11,NODE12,NODE13,NODE14,NODE15,NODE16,TOOL

BO_ 874 S2_NODE_CFG_ACK_10: 8 NODE10
 SG_ payload_b0 : 0|8@1+ (1,0) [0|255] "raw"  MASTER,NODE1,NODE2,NODE3,NODE4,NODE5,NODE6,NODE7,NODE8,NODE9,NODE10,NODE11,NODE12,NODE13,NODE14,NODE15,NODE16,TOOL
 SG_ payload_b1 : 8|8@1+ (1,0) [0|255] "raw"  MASTER,NODE1,NODE2,NODE3,NODE4,NODE5,NODE6,NODE7,NODE8,NODE9,NODE10,NODE11,NODE12,NODE13,NODE14,NODE15,NODE16,TOOL
 SG_ payload_b2 : 16|8@1+ (1,0) [0|255] "raw"  MASTER,NODE1,NODE2,NODE3,NODE4,NODE5,NODE6,NODE7,NODE8,NODE9,NODE10,NODE11,NODE12,NODE13,NODE14,NODE15,NODE16,TOOL
 SG_ payload_b3 : 24|8@1+ (1,0) [0|255] "raw"  MASTER,NODE1,NODE2,NODE3,NODE4,NODE5,NODE6,NODE7,NODE8,NODE9,NODE10,NODE11,NODE12,NODE13,NODE14,NODE15,NODE16,TOOL
 SG_ payload_b4 : 32|8@1+ (1,0) [0|255] "raw"  MASTER,NODE1,NODE2,NODE3,NODE4,NODE5,NODE6,NODE7,NODE8,NODE9,NODE10,NODE11,NODE12,NODE13,NODE14,NODE15,NODE16,TOOL
 SG_ payload_b5 : 40|8@1+ (1,0) [0|255] "raw"  MASTER,NODE1,NODE2,NODE3,NODE4,NODE5,NODE6,NODE7,NODE8,NODE9,NODE10,NODE11,NODE12,NODE13,NODE14,NODE15,NODE16,TOOL
 SG_ payload_b6 : 48|8@1+ (1,0) [0|255] "raw"  MASTER,NODE1,NODE2,NODE3,NODE4,NODE5,NODE6,NODE7,NODE8,NODE9,NODE10,NODE11,NODE12,NODE13,NODE14,NODE15,NODE16,TOOL
 SG_ payload_b7 : 56|8@1+ (1,0) [0|255] "raw"  MASTER,NODE1,NODE2,NODE3,NODE4,NODE5,NODE6,NODE7,NODE8,NODE9,NODE10,NODE11,NODE12,NODE13,NODE14,NODE15,NODE16,TOOL

BO_ 906 S2_NODE_STATUS_FAST_10: 8 NODE10
 SG_ status_flags : 0|8@1+ (1,0) [0|255] "bitfield"  MASTER,NODE1,NODE2,NODE3,NODE4,NODE5,NODE6,NODE7,NODE8,NODE9,NODE10,NODE11,NODE12,NODE13,NODE14,NODE15,NODE16,TOOL
 SG_ error_code : 8|8@1+ (1,0) [0|255] ""  MASTER,NODE1,NODE2,NODE3,NODE4,NODE5,NODE6,NODE7,NODE8,NODE9,NODE10,NODE11,NODE12,NODE13,NODE14,NODE15,NODE16,TOOL
 SG_ actual_rpm : 16|16@1+ (1,0) [0|10000] "rpm"  MASTER,NODE1,NODE2,NODE3,NODE4,NODE5,NODE6,NODE7,NODE8,NODE9,NODE10,NODE11,NODE12,NODE13,NODE14,NODE15,NODE16,TOOL
 SG_ actual_pos : 32|16@1+ (1.52587890625e-05,0) [0|0.9999847412109375] "rev"  MASTER,NODE1,NODE2,NODE3,NODE4,NODE5,NODE6,NODE7,NODE8,NODE9,NODE10,NODE11,NODE12,NODE13,NODE14,NODE15,NODE16,TOOL
 SG_ alive_counter : 48|8@1+ (1,0) [0|255] ""  MASTER,NODE1,NODE2,NODE3,NODE4,NODE5,NODE6,NODE7,NODE8,NODE9,NODE10,NODE11,NODE12,NODE13,NODE14,NODE15,NODE16,TOOL
 SG_ sync_error : 56|8@1- (0.00390625,0) [-0.5|0.49609375] "rev"  MASTER,NODE1,NODE2,NODE3,NODE4,NODE5,NODE6,NODE7,NODE8,NODE9,NODE10,NODE11,NODE12,NODE13,NODE14,NODE15,NODE16,TOOL

BO_ 970 S2_NODE_DIAG_10: 8 NODE10
 SG_ bus_voltage : 0|16@1+ (0.1,0) [0|6553.5] "V"  MASTER,NODE1,NODE2,NODE3,NODE4,NODE5,NODE6,NODE7,NODE8,NODE9,NODE10,NODE11,NODE12,NODE13,NODE14,NODE15,NODE16,TOOL
 SG_ motor_current : 16|16@1- (0.1,0) [-3276.8|3276.7] "A"  MASTER,NODE1,NODE2,NODE3,NODE4,NODE5,NODE6,NODE7,NODE8,NODE9,NODE10,NODE11,NODE12,NODE13,NODE14,NODE15,NODE16,TOOL
 SG_ controller_temp : 32|8@1- (1,0) [-128|127] "degC"  MASTER,NODE1,NODE2,NODE3,NODE4,NODE5,NODE6,NODE7,NODE8,NODE9,NODE10,NODE11,NODE12,NODE13,NODE14,NODE15,NODE16,TOOL
 SG_ motor_temp : 40|8@1- (1,0) [-128|127] "degC"  MASTER,NODE1,NODE2,NODE3,NODE4,NODE5,NODE6,NODE7,NODE8,NODE9,NODE10,NODE11,NODE12,NODE13,NODE14,NODE15,NODE16,TOOL
 SG_ fault_flags : 48|8@1+ (1,0) [0|255] "bitfield"  MASTER,NODE1,NODE2,NODE3,NODE4,NODE5,NODE6,NODE7,NODE8,NODE9,NODE10,NODE11,NODE12,NODE13,NODE14,NODE15,NODE16,TOOL
 SG_ warning_flags : 56|8@1+ (1,0) [0|255] "bitfield"  MASTER,NODE1,NODE2,NODE3,NODE4,NODE5,NODE6,NODE7,NODE8,NODE9,NODE10,NODE11,NODE12,NODE13,NODE14,NODE15,NODE16,TOOL

BO_ 795 S2_NODE_CMD_11: 8 MASTER
 SG_ node_command : 0|8@1+ (1,0) [0|255] ""  MASTER,NODE1,NODE2,NODE3,NODE4,NODE5,NODE6,NODE7,NODE8,NODE9,NODE10,NODE11,NODE12,NODE13,NODE14,NODE15,NODE16,TOOL
 SG_ node_flags : 8|8@1+ (1,0) [0|255] "bitfield"  MASTER,NODE1,NODE2,NODE3,NODE4,NODE5,NODE6,NODE7,NODE8,NODE9,NODE10,NODE11,NODE12,NODE13,NODE14,NODE15,NODE16,TOOL
 SG_ trim_rpm : 16|16@1- (0.1,0) [-3276.8|3276.7] "rpm"  MASTER,NODE1,NODE2,NODE3,NODE4,NODE5,NODE6,NODE7,NODE8,NODE9,NODE10,NODE11,NODE12,NODE13,NODE14,NODE15,NODE16,TOOL
 SG_ section_mask : 32|16@1+ (1,0) [0|65535] "bitmask"  MASTER,NODE1,NODE2,NODE3,NODE4,NODE5,NODE6,NODE7,NODE8,NODE9,NODE10,NODE11,NODE12,NODE13,NODE14,NODE15,NODE16,TOOL
 SG_ seq : 48|8@1+ (1,0) [0|255] ""  MASTER,NODE1,NODE2,NODE3,NODE4,NODE5,NODE6,NODE7,NODE8,NODE9,NODE10,NODE11,NODE12,NODE13,NODE14,NODE15,NODE16,TOOL
 SG_ reserved : 56|8@1+ (1,0) [0|255] ""  MASTER,NODE1,NODE2,NODE3,NODE4,NODE5,NODE6,NODE7,NODE8,NODE9,NODE10,NODE11,NODE12,NODE13,NODE14,NODE15,NODE16,TOOL

BO_ 843 S2_NODE_PRESENCE_11: 8 NODE11
 SG_ payload_b0 : 0|8@1+ (1,0) [0|255] "raw"  MASTER,NODE1,NODE2,NODE3,NODE4,NODE5,NODE6,NODE7,NODE8,NODE9,NODE10,NODE11,NODE12,NODE13,NODE14,NODE15,NODE16,TOOL
 SG_ payload_b1 : 8|8@1+ (1,0) [0|255] "raw"  MASTER,NODE1,NODE2,NODE3,NODE4,NODE5,NODE6,NODE7,NODE8,NODE9,NODE10,NODE11,NODE12,NODE13,NODE14,NODE15,NODE16,TOOL
 SG_ payload_b2 : 16|8@1+ (1,0) [0|255] "raw"  MASTER,NODE1,NODE2,NODE3,NODE4,NODE5,NODE6,NODE7,NODE8,NODE9,NODE10,NODE11,NODE12,NODE13,NODE14,NODE15,NODE16,TOOL
 SG_ payload_b3 : 24|8@1+ (1,0) [0|255] "raw"  MASTER,NODE1,NODE2,NODE3,NODE4,NODE5,NODE6,NODE7,NODE8,NODE9,NODE10,NODE11,NODE12,NODE13,NODE14,NODE15,NODE16,TOOL
 SG_ payload_b4 : 32|8@1+ (1,0) [0|255] "raw"  MASTER,NODE1,NODE2,NODE3,NODE4,NODE5,NODE6,NODE7,NODE8,NODE9,NODE10,NODE11,NODE12,NODE13,NODE14,NODE15,NODE16,TOOL
 SG_ payload_b5 : 40|8@1+ (1,0) [0|255] "raw"  MASTER,NODE1,NODE2,NODE3,NODE4,NODE5,NODE6,NODE7,NODE8,NODE9,NODE10,NODE11,NODE12,NODE13,NODE14,NODE15,NODE16,TOOL
 SG_ payload_b6 : 48|8@1+ (1,0) [0|255] "raw"  MASTER,NODE1,NODE2,NODE3,NODE4,NODE5,NODE6,NODE7,NODE8,NODE9,NODE10,NODE11,NODE12,NODE13,NODE14,NODE15,NODE16,TOOL
 SG_ payload_b7 : 56|8@1+ (1,0) [0|255] "raw"  MASTER,NODE1,NODE2,NODE3,NODE4,NODE5,NODE6,NODE7,NODE8,NODE9,NODE10,NODE11,NODE12,NODE13,NODE14,NODE15,NODE16,TOOL

BO_ 875 S2_NODE_CFG_ACK_11: 8 NODE11
 SG_ payload_b0 : 0|8@1+ (1,0) [0|255] "raw"  MASTER,NODE1,NODE2,NODE3,NODE4,NODE5,NODE6,NODE7,NODE8,NODE9,NODE10,NODE11,NODE12,NODE13,NODE14,NODE15,NODE16,TOOL
 SG_ payload_b1 : 8|8@1+ (1,0) [0|255] "raw"  MASTER,NODE1,NODE2,NODE3,NODE4,NODE5,NODE6,NODE7,NODE8,NODE9,NODE10,NODE11,NODE12,NODE13,NODE14,NODE15,NODE16,TOOL
 SG_ payload_b2 : 16|8@1+ (1,0) [0|255] "raw"  MASTER,NODE1,NODE2,NODE3,NODE4,NODE5,NODE6,NODE7,NODE8,NODE9,NODE10,NODE11,NODE12,NODE13,NODE14,NODE15,NODE16,TOOL
 SG_ payload_b3 : 24|8@1+ (1,0) [0|255] "raw"  MASTER,NODE1,NODE2,NODE3,NODE4,NODE5,NODE6,NODE7,NODE8,NODE9,NODE10,NODE11,NODE12,NODE13,NODE14,NODE15,NODE16,TOOL
 SG_ payload_b4 : 32|8@1+ (1,0) [0|255] "raw"  MASTER,NODE1,NODE2,NODE3,NODE4,NODE5,NODE6,NODE7,NODE8,NODE9,NODE10,NODE11,NODE12,NODE13,NODE14,NODE15,NODE16,TOOL
 SG_ payload_b5 : 40|8@1+ (1,0) [0|255] "raw"  MASTER,NODE1,NODE2,NODE3,NODE4,NODE5,NODE6,NODE7,NODE8,NODE9,NODE10,NODE11,NODE12,NODE13,NODE14,NODE15,NODE16,TOOL
 SG_ payload_b6 : 48|8@1+ (1,0) [0|255] "raw"  MASTER,NODE1,NODE2,NODE3,NODE4,NODE5,NODE6,NODE7,NODE8,NODE9,NODE10,NODE11,NODE12,NODE13,NODE14,NODE15,NODE16,TOOL
 SG_ payload_b7 : 56|8@1+ (1,0) [0|255] "raw"  MASTER,NODE1,NODE2,NODE3,NODE4,NODE5,NODE6,NODE7,NODE8,NODE9,NODE10,NODE11,NODE12,NODE13,NODE14,NODE15,NODE16,TOOL

BO_ 907 S2_NODE_STATUS_FAST_11: 8 NODE11
 SG_ status_flags : 0|8@1+ (1,0) [0|255] "bitfield"  MASTER,NODE1,NODE2,NODE3,NODE4,NODE5,NODE6,NODE7,NODE8,NODE9,NODE10,NODE11,NODE12,NODE13,NODE14,NODE15,NODE16,TOOL
 SG_ error_code : 8|8@1+ (1,0) [0|255] ""  MASTER,NODE1,NODE2,NODE3,NODE4,NODE5,NODE6,NODE7,NODE8,NODE9,NODE10,NODE11,NODE12,NODE13,NODE14,NODE15,NODE16,TOOL
 SG_ actual_rpm : 16|16@1+ (1,0) [0|10000] "rpm"  MASTER,NODE1,NODE2,NODE3,NODE4,NODE5,NODE6,NODE7,NODE8,NODE9,NODE10,NODE11,NODE12,NODE13,NODE14,NODE15,NODE16,TOOL
 SG_ actual_pos : 32|16@1+ (1.52587890625e-05,0) [0|0.9999847412109375] "rev"  MASTER,NODE1,NODE2,NODE3,NODE4,NODE5,NODE6,NODE7,NODE8,NODE9,NODE10,NODE11,NODE12,NODE13,NODE14,NODE15,NODE16,TOOL
 SG_ alive_counter : 48|8@1+ (1,0) [0|255] ""  MASTER,NODE1,NODE2,NODE3,NODE4,NODE5,NODE6,NODE7,NODE8,NODE9,NODE10,NODE11,NODE12,NODE13,NODE14,NODE15,NODE16,TOOL
 SG_ sync_error : 56|8@1- (0.00390625,0) [-0.5|0.49609375] "rev"  MASTER,NODE1,NODE2,NODE3,NODE4,NODE5,NODE6,NODE7,NODE8,NODE9,NODE10,NODE11,NODE12,NODE13,NODE14,NODE15,NODE16,TOOL

BO_ 971 S2_NODE_DIAG_11: 8 NODE11
 SG_ bus_voltage : 0|16@1+ (0.1,0) [0|6553.5] "V"  MASTER,NODE1,NODE2,NODE3,NODE4,NODE5,NODE6,NODE7,NODE8,NODE9,NODE10,NODE11,NODE12,NODE13,NODE14,NODE15,NODE16,TOOL
 SG_ motor_current : 16|16@1- (0.1,0) [-3276.8|3276.7] "A"  MASTER,NODE1,NODE2,NODE3,NODE4,NODE5,NODE6,NODE7,NODE8,NODE9,NODE10,NODE11,NODE12,NODE13,NODE14,NODE15,NODE16,TOOL
 SG_ controller_temp : 32|8@1- (1,0) [-128|127] "degC"  MASTER,NODE1,NODE2,NODE3,NODE4,NODE5,NODE6,NODE7,NODE8,NODE9,NODE10,NODE11,NODE12,NODE13,NODE14,NODE15,NODE16,TOOL
 SG_ motor_temp : 40|8@1- (1,0) [-128|127] "degC"  MASTER,NODE1,NODE2,NODE3,NODE4,NODE5,NODE6,NODE7,NODE8,NODE9,NODE10,NODE11,NODE12,NODE13,NODE14,NODE15,NODE16,TOOL
 SG_ fault_flags : 48|8@1+ (1,0) [0|255] "bitfield"  MASTER,NODE1,NODE2,NODE3,NODE4,NODE5,NODE6,NODE7,NODE8,NODE9,NODE10,NODE11,NODE12,NODE13,NODE14,NODE15,NODE16,TOOL
 SG_ warning_flags : 56|8@1+ (1,0) [0|255] "bitfield"  MASTER,NODE1,NODE2,NODE3,NODE4,NODE5,NODE6,NODE7,NODE8,NODE9,NODE10,NODE11,NODE12,NODE13,NODE14,NODE15,NODE16,TOOL

BO_ 796 S2_NODE_CMD_12: 8 MASTER
 SG_ node_command : 0|8@1+ (1,0) [0|255] ""  MASTER,NODE1,NODE2,NODE3,NODE4,NODE5,NODE6,NODE7,NODE8,NODE9,NODE10,NODE11,NODE12,NODE13,NODE14,NODE15,NODE16,TOOL
 SG_ node_flags : 8|8@1+ (1,0) [0|255] "bitfield"  MASTER,NODE1,NODE2,NODE3,NODE4,NODE5,NODE6,NODE7,NODE8,NODE9,NODE10,NODE11,NODE12,NODE13,NODE14,NODE15,NODE16,TOOL
 SG_ trim_rpm : 16|16@1- (0.1,0) [-3276.8|3276.7] "rpm"  MASTER,NODE1,NODE2,NODE3,NODE4,NODE5,NODE6,NODE7,NODE8,NODE9,NODE10,NODE11,NODE12,NODE13,NODE14,NODE15,NODE16,TOOL
 SG_ section_mask : 32|16@1+ (1,0) [0|65535] "bitmask"  MASTER,NODE1,NODE2,NODE3,NODE4,NODE5,NODE6,NODE7,NODE8,NODE9,NODE10,NODE11,NODE12,NODE13,NODE14,NODE15,NODE16,TOOL
 SG_ seq : 48|8@1+ (1,0) [0|255] ""  MASTER,NODE1,NODE2,NODE3,NODE4,NODE5,NODE6,NODE7,NODE8,NODE9,NODE10,NODE11,NODE12,NODE13,NODE14,NODE15,NODE16,TOOL
 SG_ reserved : 56|8@1+ (1,0) [0|255] ""  MASTER,NODE1,NODE2,NODE3,NODE4,NODE5,NODE6,NODE7,NODE8,NODE9,NODE10,NODE11,NODE12,NODE13,NODE14,NODE15,NODE16,TOOL

BO_ 844 S2_NODE_PRESENCE_12: 8 NODE12
 SG_ payload_b0 : 0|8@1+ (1,0) [0|255] "raw"  MASTER,NODE1,NODE2,NODE3,NODE4,NODE5,NODE6,NODE7,NODE8,NODE9,NODE10,NODE11,NODE12,NODE13,NODE14,NODE15,NODE16,TOOL
 SG_ payload_b1 : 8|8@1+ (1,0) [0|255] "raw"  MASTER,NODE1,NODE2,NODE3,NODE4,NODE5,NODE6,NODE7,NODE8,NODE9,NODE10,NODE11,NODE12,NODE13,NODE14,NODE15,NODE16,TOOL
 SG_ payload_b2 : 16|8@1+ (1,0) [0|255] "raw"  MASTER,NODE1,NODE2,NODE3,NODE4,NODE5,NODE6,NODE7,NODE8,NODE9,NODE10,NODE11,NODE12,NODE13,NODE14,NODE15,NODE16,TOOL
 SG_ payload_b3 : 24|8@1+ (1,0) [0|255] "raw"  MASTER,NODE1,NODE2,NODE3,NODE4,NODE5,NODE6,NODE7,NODE8,NODE9,NODE10,NODE11,NODE12,NODE13,NODE14,NODE15,NODE16,TOOL
 SG_ payload_b4 : 32|8@1+ (1,0) [0|255] "raw"  MASTER,NODE1,NODE2,NODE3,NODE4,NODE5,NODE6,NODE7,NODE8,NODE9,NODE10,NODE11,NODE12,NODE13,NODE14,NODE15,NODE16,TOOL
 SG_ payload_b5 : 40|8@1+ (1,0) [0|255] "raw"  MASTER,NODE1,NODE2,NODE3,NODE4,NODE5,NODE6,NODE7,NODE8,NODE9,NODE10,NODE11,NODE12,NODE13,NODE14,NODE15,NODE16,TOOL
 SG_ payload_b6 : 48|8@1+ (1,0) [0|255] "raw"  MASTER,NODE1,NODE2,NODE3,NODE4,NODE5,NODE6,NODE7,NODE8,NODE9,NODE10,NODE11,NODE12,NODE13,NODE14,NODE15,NODE16,TOOL
 SG_ payload_b7 : 56|8@1+ (1,0) [0|255] "raw"  MASTER,NODE1,NODE2,NODE3,NODE4,NODE5,NODE6,NODE7,NODE8,NODE9,NODE10,NODE11,NODE12,NODE13,NODE14,NODE15,NODE16,TOOL

BO_ 876 S2_NODE_CFG_ACK_12: 8 NODE12
 SG_ payload_b0 : 0|8@1+ (1,0) [0|255] "raw"  MASTER,NODE1,NODE2,NODE3,NODE4,NODE5,NODE6,NODE7,NODE8,NODE9,NODE10,NODE11,NODE12,NODE13,NODE14,NODE15,NODE16,TOOL
 SG_ payload_b1 : 8|8@1+ (1,0) [0|255] "raw"  MASTER,NODE1,NODE2,NODE3,NODE4,NODE5,NODE6,NODE7,NODE8,NODE9,NODE10,NODE11,NODE12,NODE13,NODE14,NODE15,NODE16,TOOL
 SG_ payload_b2 : 16|8@1+ (1,0) [0|255] "raw"  MASTER,NODE1,NODE2,NODE3,NODE4,NODE5,NODE6,NODE7,NODE8,NODE9,NODE10,NODE11,NODE12,NODE13,NODE14,NODE15,NODE16,TOOL
 SG_ payload_b3 : 24|8@1+ (1,0) [0|255] "raw"  MASTER,NODE1,NODE2,NODE3,NODE4,NODE5,NODE6,NODE7,NODE8,NODE9,NODE10,NODE11,NODE12,NODE13,NODE14,NODE15,NODE16,TOOL
 SG_ payload_b4 : 32|8@1+ (1,0) [0|255] "raw"  MASTER,NODE1,NODE2,NODE3,NODE4,NODE5,NODE6,NODE7,NODE8,NODE9,NODE10,NODE11,NODE12,NODE13,NODE14,NODE15,NODE16,TOOL
 SG_ payload_b5 : 40|8@1+ (1,0) [0|255] "raw"  MASTER,NODE1,NODE2,NODE3,NODE4,NODE5,NODE6,NODE7,NODE8,NODE9,NODE10,NODE11,NODE12,NODE13,NODE14,NODE15,NODE16,TOOL
 SG_ payload_b6 : 48|8@1+ (1,0) [0|255] "raw"  MASTER,NODE1,NODE2,NODE3,NODE4,NODE5,NODE6,NODE7,NODE8,NODE9,NODE10,NODE11,NODE12,NODE13,NODE14,NODE15,NODE16,TOOL
 SG_ payload_b7 : 56|8@1+ (1,0) [0|255] "raw"  MASTER,NODE1,NODE2,NODE3,NODE4,NODE5,NODE6,NODE7,NODE8,NODE9,NODE10,NODE11,NODE12,NODE13,NODE14,NODE15,NODE16,TOOL

BO_ 908 S2_NODE_STATUS_FAST_12: 8 NODE12
 SG_ status_flags : 0|8@1+ (1,0) [0|255] "bitfield"  MASTER,NODE1,NODE2,NODE3,NODE4,NODE5,NODE6,NODE7,NODE8,NODE9,NODE10,NODE11,NODE12,NODE13,NODE14,NODE15,NODE16,TOOL
 SG_ error_code : 8|8@1+ (1,0) [0|255] ""  MASTER,NODE1,NODE2,NODE3,NODE4,NODE5,NODE6,NODE7,NODE8,NODE9,NODE10,NODE11,NODE12,NODE13,NODE14,NODE15,NODE16,TOOL
 SG_ actual_rpm : 16|16@1+ (1,0) [0|10000] "rpm"  MASTER,NODE1,NODE2,NODE3,NODE4,NODE5,NODE6,NODE7,NODE8,NODE9,NODE10,NODE11,NODE12,NODE13,NODE14,NODE15,NODE16,TOOL
 SG_ actual_pos : 32|16@1+ (1.52587890625e-05,0) [0|0.9999847412109375] "rev"  MASTER,NODE1,NODE2,NODE3,NODE4,NODE5,NODE6,NODE7,NODE8,NODE9,NODE10,NODE11,NODE12,NODE13,NODE14,NODE15,NODE16,TOOL
 SG_ alive_counter : 48|8@1+ (1,0) [0|255] ""  MASTER,NODE1,NODE2,NODE3,NODE4,NODE5,NODE6,NODE7,NODE8,NODE9,NODE10,NODE11,NODE12,NODE13,NODE14,NODE15,NODE16,TOOL
 SG_ sync_error : 56|8@1- (0.00390625,0) [-0.5|0.49609375] "rev"  MASTER,NODE1,NODE2,NODE3,NODE4,NODE5,NODE6,NODE7,NODE8,NODE9,NODE10,NODE11,NODE12,NODE13,NODE14,NODE15,NODE16,TOOL

CM_ SG_ 768 control_flags "bit0=drive_enable, bit1=sync_enable, bit2=estop, bit3=diag_enable";
CM_ SG_ 785 section_mask "Bytes 4-5 carry the full 16-bit section mask, not a position offset.";
CM_ SG_ 646 status_flags "bit0=ready, bit1=enabled, bit2=running, bit3=sync_locked, bit4=warning_active, bit5=fault_active, bit6=position_valid, bit7=can_timeout";
CM_ SG_ 710 fault_flags "bit0=overcurrent, bit1=undervoltage, bit2=overvoltage, bit3=overtemperature, bit4=encoder_fault, bit5=hall_fault, bit6=motor_stall, bit7=driver_fault";
CM_ SG_ 710 warning_flags "bit0=rpm_deviation, bit1=sync_deviation, bit2=temp_high, bit3=current_high, bit4=communication_late";
CM_ SG_ 535 node_flags "bit0=allow_run, bit1=invert_dir, bit2=use_local_sensor";
CM_ SG_ 535 section_mask "NODE_CMD bytes 4-5 are used as section mask in current ECU firmware, not position offset.";
CM_ SG_ 647 status_flags "bit0=ready, bit1=enabled, bit2=running, bit3=sync_locked, bit4=warning_active, bit5=fault_active, bit6=position_valid, bit7=can_timeout";
CM_ SG_ 711 fault_flags "bit0=overcurrent, bit1=undervoltage, bit2=overvoltage, bit3=overtemperature, bit4=encoder_fault, bit5=hall_fault, bit6=motor_stall, bit7=driver_fault";
CM_ SG_ 711 warning_flags "bit0=rpm_deviation, bit1=sync_deviation, bit2=temp_high, bit3=current_high, bit4=communication_late";
CM_ SG_ 536 node_flags "bit0=allow_run, bit1=invert_dir, bit2=use_local_sensor";
CM_ SG_ 536 section_mask "NODE_CMD bytes 4-5 are used as section mask in current ECU firmware, not position offset.";
CM_ SG_ 648 status_flags "bit0=ready, bit1=enabled, bit2=running, bit3=sync_locked, bit4=warning_active, bit5=fault_active, bit6=position_valid, bit7=can_timeout";
CM_ SG_ 712 fault_flags "bit0=overcurrent, bit1=undervoltage, bit2=overvoltage, bit3=overtemperature, bit4=encoder_fault, bit5=hall_fault, bit6=motor_stall, bit7=driver_fault";
CM_ SG_ 712 warning_flags "bit0=rpm_deviation, bit1=sync_deviation, bit2=temp_high, bit3=current_high, bit4=communication_late";
CM_ SG_ 537 node_flags "bit0=allow_run, bit1=invert_dir, bit2=use_local_sensor";
CM_ SG_ 537 section_mask "NODE_CMD bytes 4-5 are used as section mask in current ECU firmware, not position offset.";
CM_ SG_ 649 status_flags "bit0=ready, bit1=enabled, bit2=running, bit3=sync_locked, bit4=warning_active, bit5=fault_active, bit6=position_valid, bit7=can_timeout";
CM_ SG_ 713 fault_flags "bit0=overcurrent, bit1=undervoltage, bit2=overvoltage, bit3=overtemperature, bit4=encoder_fault, bit5=hall_fault, bit6=motor_stall, bit7=driver_fault";
CM_ SG_ 713 warning_flags "bit0=rpm_deviation, bit1=sync_deviation, bit2=temp_high, bit3=current_high, bit4=communication_late";
CM_ SG_ 538 node_flags "bit0=allow_run, bit1=invert_dir, bit2=use_local_sensor";
CM_ SG_ 538 section_mask "NODE_CMD bytes 4-5 are used as section mask in current ECU firmware, not position offset.";
CM_ SG_ 650 status_flags "bit0=ready, bit1=enabled, bit2=running, bit3=sync_locked, bit4=warning_active, bit5=fault_active, bit6=position_valid, bit7=can_timeout";
CM_ SG_ 714 fault_flags "bit0=overcurrent, bit1=undervoltage, bit2=overvoltage, bit3=overtemperature, bit4=encoder_fault, bit5=hall_fault, bit6=motor_stall, bit7=driver_fault";
CM_ SG_ 714 warning_flags "bit0=rpm_deviation, bit1=sync_deviation, bit2=temp_high, bit3=current_high, bit4=communication_late";
CM_ SG_ 539 node_flags "bit0=allow_run, bit1=invert_dir, bit2=use_local_sensor";
CM_ SG_ 539 section_mask "NODE_CMD bytes 4-5 are used as section mask in current ECU firmware, not position offset.";
CM_ SG_ 651 status_flags "bit0=ready, bit1=enabled, bit2=running, bit3=sync_locked, bit4=warning_active, bit5=fault_active, bit6=position_valid, bit7=can_timeout";
CM_ SG_ 715 fault_flags "bit0=overcurrent, bit1=undervoltage, bit2=overvoltage, bit3=overtemperature, bit4=encoder_fault, bit5=hall_fault, bit6=motor_stall, bit7=driver_fault";
CM_ SG_ 715 warning_flags "bit0=rpm_deviation, bit1=sync_deviation, bit2=temp_high, bit3=current_high, bit4=communication_late";
CM_ SG_ 540 node_flags "bit0=allow_run, bit1=invert_dir, bit2=use_local_sensor";
CM_ SG_ 540 section_mask "NODE_CMD bytes 4-5 are used as section mask in current ECU firmware, not position offset.";
CM_ SG_ 652 status_flags "bit0=ready, bit1=enabled, bit2=running, bit3=sync_locked, bit4=warning_active, bit5=fault_active, bit6=position_valid, bit7=can_timeout";
CM_ SG_ 716 fault_flags "bit0=overcurrent, bit1=undervoltage, bit2=overvoltage, bit3=overtemperature, bit4=encoder_fault, bit5=hall_fault, bit6=motor_stall, bit7=driver_fault";
CM_ SG_ 716 warning_flags "bit0=rpm_deviation, bit1=sync_deviation, bit2=temp_high, bit3=current_high, bit4=communication_late";
CM_ SG_ 541 node_flags "bit0=allow_run, bit1=invert_dir, bit2=use_local_sensor";
CM_ SG_ 541 section_mask "NODE_CMD bytes 4-5 are used as section mask in current ECU firmware, not position offset.";
CM_ SG_ 653 status_flags "bit0=ready, bit1=enabled, bit2=running, bit3=sync_locked, bit4=warning_active, bit5=fault_active, bit6=position_valid, bit7=can_timeout";
CM_ SG_ 717 fault_flags "bit0=overcurrent, bit1=undervoltage, bit2=overvoltage, bit3=overtemperature, bit4=encoder_fault, bit5=hall_fault, bit6=motor_stall, bit7=driver_fault";
CM_ SG_ 717 warning_flags "bit0=rpm_deviation, bit1=sync_deviation, bit2=temp_high, bit3=current_high, bit4=communication_late";
CM_ SG_ 542 node_flags "bit0=allow_run, bit1=invert_dir, bit2=use_local_sensor";
CM_ SG_ 542 section_mask "NODE_CMD bytes 4-5 are used as section mask in current ECU firmware, not position offset.";
CM_ SG_ 654 status_flags "bit0=ready, bit1=enabled, bit2=running, bit3=sync_locked, bit4=warning_active, bit5=fault_active, bit6=position_valid, bit7=can_timeout";
CM_ SG_ 718 fault_flags "bit0=overcurrent, bit1=undervoltage, bit2=overvoltage, bit3=overtemperature, bit4=encoder_fault, bit5=hall_fault, bit6=motor_stall, bit7=driver_fault";
CM_ SG_ 718 warning_flags "bit0=rpm_deviation, bit1=sync_deviation, bit2=temp_high, bit3=current_high, bit4=communication_late";
CM_ SG_ 543 node_flags "bit0=allow_run, bit1=invert_dir, bit2=use_local_sensor";
CM_ SG_ 543 section_mask "NODE_CMD bytes 4-5 are used as section mask in current ECU firmware, not position offset.";
CM_ SG_ 655 status_flags "bit0=ready, bit1=enabled, bit2=running, bit3=sync_locked, bit4=warning_active, bit5=fault_active, bit6=position_valid, bit7=can_timeout";
CM_ SG_ 719 fault_flags "bit0=overcurrent, bit1=undervoltage, bit2=overvoltage, bit3=overtemperature, bit4=encoder_fault, bit5=hall_fault, bit6=motor_stall, bit7=driver_fault";
CM_ SG_ 719 warning_flags "bit0=rpm_deviation, bit1=sync_deviation, bit2=temp_high, bit3=current_high, bit4=communication_late";
CM_ SG_ 544 node_flags "bit0=allow_run, bit1=invert_dir, bit2=use_local_sensor";
CM_ SG_ 544 section_mask "NODE_CMD bytes 4-5 are used as section mask in current ECU firmware, not position offset.";
CM_ SG_ 656 status_flags "bit0=ready, bit1=enabled, bit2=running, bit3=sync_locked, bit4=warning_active, bit5=fault_active, bit6=position_valid, bit7=can_timeout";
CM_ SG_ 720 fault_flags "bit0=overcurrent, bit1=undervoltage, bit2=overvoltage, bit3=overtemperature, bit4=encoder_fault, bit5=hall_fault, bit6=motor_stall, bit7=driver_fault";
CM_ SG_ 720 warning_flags "bit0=rpm_deviation, bit1=sync_deviation, bit2=temp_high, bit3=current_high, bit4=communication_late";
CM_ BO_ 768 "S2 runtime bank global control.";
CM_ SG_ 785 node_flags "bit0=allow_run, bit1=invert_dir, bit2=use_local_sensor";
CM_ SG_ 785 section_mask "NODE_CMD bytes 4-5 are used as section mask in current ECU firmware, not position offset.";
CM_ SG_ 897 status_flags "bit0=ready, bit1=enabled, bit2=running, bit3=sync_locked, bit4=warning_active, bit5=fault_active, bit6=position_valid, bit7=can_timeout";
CM_ SG_ 961 fault_flags "bit0=overcurrent, bit1=undervoltage, bit2=overvoltage, bit3=overtemperature, bit4=encoder_fault, bit5=hall_fault, bit6=motor_stall, bit7=driver_fault";
CM_ SG_ 961 warning_flags "bit0=rpm_deviation, bit1=sync_deviation, bit2=temp_high, bit3=current_high, bit4=communication_late";
CM_ SG_ 786 node_flags "bit0=allow_run, bit1=invert_dir, bit2=use_local_sensor";
CM_ SG_ 786 section_mask "NODE_CMD bytes 4-5 are used as section mask in current ECU firmware, not position offset.";
CM_ SG_ 898 status_flags "bit0=ready, bit1=enabled, bit2=running, bit3=sync_locked, bit4=warning_active, bit5=fault_active, bit6=position_valid, bit7=can_timeout";
CM_ SG_ 962 fault_flags "bit0=overcurrent, bit1=undervoltage, bit2=overvoltage, bit3=overtemperature, bit4=encoder_fault, bit5=hall_fault, bit6=motor_stall, bit7=driver_fault";
CM_ SG_ 962 warning_flags "bit0=rpm_deviation, bit1=sync_deviation, bit2=temp_high, bit3=current_high, bit4=communication_late";
CM_ SG_ 787 node_flags "bit0=allow_run, bit1=invert_dir, bit2=use_local_sensor";
CM_ SG_ 787 section_mask "NODE_CMD bytes 4-5 are used as section mask in current ECU firmware, not position offset.";
CM_ SG_ 899 status_flags "bit0=ready, bit1=enabled, bit2=running, bit3=sync_locked, bit4=warning_active, bit5=fault_active, bit6=position_valid, bit7=can_timeout";
CM_ SG_ 963 fault_flags "bit0=overcurrent, bit1=undervoltage, bit2=overvoltage, bit3=overtemperature, bit4=encoder_fault, bit5=hall_fault, bit6=motor_stall, bit7=driver_fault";
CM_ SG_ 963 warning_flags "bit0=rpm_deviation, bit1=sync_deviation, bit2=temp_high, bit3=current_high, bit4=communication_late";
CM_ SG_ 788 node_flags "bit0=allow_run, bit1=invert_dir, bit2=use_local_sensor";
CM_ SG_ 788 section_mask "NODE_CMD bytes 4-5 are used as section mask in current ECU firmware, not position offset.";
CM_ SG_ 900 status_flags "bit0=ready, bit1=enabled, bit2=running, bit3=sync_locked, bit4=warning_active, bit5=fault_active, bit6=position_valid, bit7=can_timeout";
CM_ SG_ 964 fault_flags "bit0=overcurrent, bit1=undervoltage, bit2=overvoltage, bit3=overtemperature, bit4=encoder_fault, bit5=hall_fault, bit6=motor_stall, bit7=driver_fault";
CM_ SG_ 964 warning_flags "bit0=rpm_deviation, bit1=sync_deviation, bit2=temp_high, bit3=current_high, bit4=communication_late";
CM_ SG_ 789 node_flags "bit0=allow_run, bit1=invert_dir, bit2=use_local_sensor";
CM_ SG_ 789 section_mask "NODE_CMD bytes 4-5 are used as section mask in current ECU firmware, not position offset.";
CM_ SG_ 901 status_flags "bit0=ready, bit1=enabled, bit2=running, bit3=sync_locked, bit4=warning_active, bit5=fault_active, bit6=position_valid, bit7=can_timeout";
CM_ SG_ 965 fault_flags "bit0=overcurrent, bit1=undervoltage, bit2=overvoltage, bit3=overtemperature, bit4=encoder_fault, bit5=hall_fault, bit6=motor_stall, bit7=driver_fault";
CM_ SG_ 965 warning_flags "bit0=rpm_deviation, bit1=sync_deviation, bit2=temp_high, bit3=current_high, bit4=communication_late";
CM_ SG_ 790 node_flags "bit0=allow_run, bit1=invert_dir, bit2=use_local_sensor";
CM_ SG_ 790 section_mask "NODE_CMD bytes 4-5 are used as section mask in current ECU firmware, not position offset.";
CM_ SG_ 902 status_flags "bit0=ready, bit1=enabled, bit2=running, bit3=sync_locked, bit4=warning_active, bit5=fault_active, bit6=position_valid, bit7=can_timeout";
CM_ SG_ 966 fault_flags "bit0=overcurrent, bit1=undervoltage, bit2=overvoltage, bit3=overtemperature, bit4=encoder_fault, bit5=hall_fault, bit6=motor_stall, bit7=driver_fault";
CM_ SG_ 966 warning_flags "bit0=rpm_deviation, bit1=sync_deviation, bit2=temp_high, bit3=current_high, bit4=communication_late";
CM_ SG_ 791 node_flags "bit0=allow_run, bit1=invert_dir, bit2=use_local_sensor";
CM_ SG_ 791 section_mask "NODE_CMD bytes 4-5 are used as section mask in current ECU firmware, not position offset.";
CM_ SG_ 903 status_flags "bit0=ready, bit1=enabled, bit2=running, bit3=sync_locked, bit4=warning_active, bit5=fault_active, bit6=position_valid, bit7=can_timeout";
CM_ SG_ 967 fault_flags "bit0=overcurrent, bit1=undervoltage, bit2=overvoltage, bit3=overtemperature, bit4=encoder_fault, bit5=hall_fault, bit6=motor_stall, bit7=driver_fault";
CM_ SG_ 967 warning_flags "bit0=rpm_deviation, bit1=sync_deviation, bit2=temp_high, bit3=current_high, bit4=communication_late";
CM_ SG_ 792 node_flags "bit0=allow_run, bit1=invert_dir, bit2=use_local_sensor";
CM_ SG_ 792 section_mask "NODE_CMD bytes 4-5 are used as section mask in current ECU firmware, not position offset.";
CM_ SG_ 904 status_flags "bit0=ready, bit1=enabled, bit2=running, bit3=sync_locked, bit4=warning_active, bit5=fault_active, bit6=position_valid, bit7=can_timeout";
CM_ SG_ 968 fault_flags "bit0=overcurrent, bit1=undervoltage, bit2=overvoltage, bit3=overtemperature, bit4=encoder_fault, bit5=hall_fault, bit6=motor_stall, bit7=driver_fault";
CM_ SG_ 968 warning_flags "bit0=rpm_deviation, bit1=sync_deviation, bit2=temp_high, bit3=current_high, bit4=communication_late";
CM_ SG_ 793 node_flags "bit0=allow_run, bit1=invert_dir, bit2=use_local_sensor";
CM_ SG_ 793 section_mask "NODE_CMD bytes 4-5 are used as section mask in current ECU firmware, not position offset.";
CM_ SG_ 905 status_flags "bit0=ready, bit1=enabled, bit2=running, bit3=sync_locked, bit4=warning_active, bit5=fault_active, bit6=position_valid, bit7=can_timeout";
CM_ SG_ 969 fault_flags "bit0=overcurrent, bit1=undervoltage, bit2=overvoltage, bit3=overtemperature, bit4=encoder_fault, bit5=hall_fault, bit6=motor_stall, bit7=driver_fault";
CM_ SG_ 969 warning_flags "bit0=rpm_deviation, bit1=sync_deviation, bit2=temp_high, bit3=current_high, bit4=communication_late";
CM_ SG_ 794 node_flags "bit0=allow_run, bit1=invert_dir, bit2=use_local_sensor";
CM_ SG_ 794 section_mask "NODE_CMD bytes 4-5 are used as section mask in current ECU firmware, not position offset.";
CM_ SG_ 906 status_flags "bit0=ready, bit1=enabled, bit2=running, bit3=sync_locked, bit4=warning_active, bit5=fault_active, bit6=position_valid, bit7=can_timeout";
CM_ SG_ 970 fault_flags "bit0=overcurrent, bit1=undervoltage, bit2=overvoltage, bit3=overtemperature, bit4=encoder_fault, bit5=hall_fault, bit6=motor_stall, bit7=driver_fault";
CM_ SG_ 970 warning_flags "bit0=rpm_deviation, bit1=sync_deviation, bit2=temp_high, bit3=current_high, bit4=communication_late";
CM_ SG_ 795 node_flags "bit0=allow_run, bit1=invert_dir, bit2=use_local_sensor";
CM_ SG_ 795 section_mask "NODE_CMD bytes 4-5 are used as section mask in current ECU firmware, not position offset.";
CM_ SG_ 907 status_flags "bit0=ready, bit1=enabled, bit2=running, bit3=sync_locked, bit4=warning_active, bit5=fault_active, bit6=position_valid, bit7=can_timeout";
CM_ SG_ 971 fault_flags "bit0=overcurrent, bit1=undervoltage, bit2=overvoltage, bit3=overtemperature, bit4=encoder_fault, bit5=hall_fault, bit6=motor_stall, bit7=driver_fault";
CM_ SG_ 971 warning_flags "bit0=rpm_deviation, bit1=sync_deviation, bit2=temp_high, bit3=current_high, bit4=communication_late";
CM_ SG_ 796 node_flags "bit0=allow_run, bit1=invert_dir, bit2=use_local_sensor";
CM_ SG_ 796 section_mask "NODE_CMD bytes 4-5 are used as section mask in current ECU firmware, not position offset.";
CM_ SG_ 908 status_flags "bit0=ready, bit1=enabled, bit2=running, bit3=sync_locked, bit4=warning_active, bit5=fault_active, bit6=position_valid, bit7=can_timeout";

BA_DEF_ BO_  "GenMsgCycleTime" INT 0 65535;
BA_DEF_DEF_  "GenMsgCycleTime" 0;
BA_ "GenMsgCycleTime" BO_ 646 20;
BA_ "GenMsgCycleTime" BO_ 710 100;
BA_ "GenMsgCycleTime" BO_ 535 50;
BA_ "GenMsgCycleTime" BO_ 583 1000;
BA_ "GenMsgCycleTime" BO_ 647 20;
BA_ "GenMsgCycleTime" BO_ 711 100;
BA_ "GenMsgCycleTime" BO_ 536 50;
BA_ "GenMsgCycleTime" BO_ 584 1000;
BA_ "GenMsgCycleTime" BO_ 648 20;
BA_ "GenMsgCycleTime" BO_ 712 100;
BA_ "GenMsgCycleTime" BO_ 537 50;
BA_ "GenMsgCycleTime" BO_ 585 1000;
BA_ "GenMsgCycleTime" BO_ 649 20;
BA_ "GenMsgCycleTime" BO_ 713 100;
BA_ "GenMsgCycleTime" BO_ 538 50;
BA_ "GenMsgCycleTime" BO_ 586 1000;
BA_ "GenMsgCycleTime" BO_ 650 20;
BA_ "GenMsgCycleTime" BO_ 714 100;
BA_ "GenMsgCycleTime" BO_ 539 50;
BA_ "GenMsgCycleTime" BO_ 587 1000;
BA_ "GenMsgCycleTime" BO_ 651 20;
BA_ "GenMsgCycleTime" BO_ 715 100;
BA_ "GenMsgCycleTime" BO_ 540 50;
BA_ "GenMsgCycleTime" BO_ 588 1000;
BA_ "GenMsgCycleTime" BO_ 652 20;
BA_ "GenMsgCycleTime" BO_ 716 100;
BA_ "GenMsgCycleTime" BO_ 541 50;
BA_ "GenMsgCycleTime" BO_ 589 1000;
BA_ "GenMsgCycleTime" BO_ 653 20;
BA_ "GenMsgCycleTime" BO_ 717 100;
BA_ "GenMsgCycleTime" BO_ 542 50;
BA_ "GenMsgCycleTime" BO_ 590 1000;
BA_ "GenMsgCycleTime" BO_ 654 20;
BA_ "GenMsgCycleTime" BO_ 718 100;
BA_ "GenMsgCycleTime" BO_ 543 50;
BA_ "GenMsgCycleTime" BO_ 591 1000;
BA_ "GenMsgCycleTime" BO_ 655 20;
BA_ "GenMsgCycleTime" BO_ 719 100;
BA_ "GenMsgCycleTime" BO_ 544 50;
BA_ "GenMsgCycleTime" BO_ 592 1000;
BA_ "GenMsgCycleTime" BO_ 656 20;
BA_ "GenMsgCycleTime" BO_ 720 100;
BA_ "GenMsgCycleTime" BO_ 768 20;
BA_ "GenMsgCycleTime" BO_ 769 100;
BA_ "GenMsgCycleTime" BO_ 785 50;
BA_ "GenMsgCycleTime" BO_ 833 1000;
BA_ "GenMsgCycleTime" BO_ 897 20;
BA_ "GenMsgCycleTime" BO_ 961 100;
BA_ "GenMsgCycleTime" BO_ 786 50;
BA_ "GenMsgCycleTime" BO_ 834 1000;
BA_ "GenMsgCycleTime" BO_ 898 20;
BA_ "GenMsgCycleTime" BO_ 962 100;
BA_ "GenMsgCycleTime" BO_ 787 50;
BA_ "GenMsgCycleTime" BO_ 835 1000;
BA_ "GenMsgCycleTime" BO_ 899 20;
BA_ "GenMsgCycleTime" BO_ 963 100;
BA_ "GenMsgCycleTime" BO_ 788 50;
BA_ "GenMsgCycleTime" BO_ 836 1000;
BA_ "GenMsgCycleTime" BO_ 900 20;
BA_ "GenMsgCycleTime" BO_ 964 100;
BA_ "GenMsgCycleTime" BO_ 789 50;
BA_ "GenMsgCycleTime" BO_ 837 1000;
BA_ "GenMsgCycleTime" BO_ 901 20;
BA_ "GenMsgCycleTime" BO_ 965 100;
BA_ "GenMsgCycleTime" BO_ 790 50;
BA_ "GenMsgCycleTime" BO_ 838 1000;
BA_ "GenMsgCycleTime" BO_ 902 20;
BA_ "GenMsgCycleTime" BO_ 966 100;
BA_ "GenMsgCycleTime" BO_ 791 50;
BA_ "GenMsgCycleTime" BO_ 839 1000;
BA_ "GenMsgCycleTime" BO_ 903 20;
BA_ "GenMsgCycleTime" BO_ 967 100;
BA_ "GenMsgCycleTime" BO_ 792 50;
BA_ "GenMsgCycleTime" BO_ 840 1000;
BA_ "GenMsgCycleTime" BO_ 904 20;
BA_ "GenMsgCycleTime" BO_ 968 100;
BA_ "GenMsgCycleTime" BO_ 793 50;
BA_ "GenMsgCycleTime" BO_ 841 1000;
BA_ "GenMsgCycleTime" BO_ 905 20;
BA_ "GenMsgCycleTime" BO_ 969 100;
BA_ "GenMsgCycleTime" BO_ 794 50;
BA_ "GenMsgCycleTime" BO_ 842 1000;
BA_ "GenMsgCycleTime" BO_ 906 20;
BA_ "GenMsgCycleTime" BO_ 970 100;
BA_ "GenMsgCycleTime" BO_ 795 50;
BA_ "GenMsgCycleTime" BO_ 843 1000;
BA_ "GenMsgCycleTime" BO_ 907 20;
BA_ "GenMsgCycleTime" BO_ 971 100;
BA_ "GenMsgCycleTime" BO_ 796 50;
BA_ "GenMsgCycleTime" BO_ 844 1000;
BA_ "GenMsgCycleTime" BO_ 908 20;
VAL_ 535 node_command 0 "NOP" 1 "ENABLE" 2 "DISABLE" 3 "ZERO_POS" 4 "CLEAR_FAULT";
VAL_ 536 node_command 0 "NOP" 1 "ENABLE" 2 "DISABLE" 3 "ZERO_POS" 4 "CLEAR_FAULT";
VAL_ 537 node_command 0 "NOP" 1 "ENABLE" 2 "DISABLE" 3 "ZERO_POS" 4 "CLEAR_FAULT";
VAL_ 538 node_command 0 "NOP" 1 "ENABLE" 2 "DISABLE" 3 "ZERO_POS" 4 "CLEAR_FAULT";
VAL_ 539 node_command 0 "NOP" 1 "ENABLE" 2 "DISABLE" 3 "ZERO_POS" 4 "CLEAR_FAULT";
VAL_ 540 node_command 0 "NOP" 1 "ENABLE" 2 "DISABLE" 3 "ZERO_POS" 4 "CLEAR_FAULT";
VAL_ 541 node_command 0 "NOP" 1 "ENABLE" 2 "DISABLE" 3 "ZERO_POS" 4 "CLEAR_FAULT";
VAL_ 542 node_command 0 "NOP" 1 "ENABLE" 2 "DISABLE" 3 "ZERO_POS" 4 "CLEAR_FAULT";
VAL_ 543 node_command 0 "NOP" 1 "ENABLE" 2 "DISABLE" 3 "ZERO_POS" 4 "CLEAR_FAULT";
VAL_ 544 node_command 0 "NOP" 1 "ENABLE" 2 "DISABLE" 3 "ZERO_POS" 4 "CLEAR_FAULT";
VAL_ 768 system_mode 0 "OFF" 1 "MANUAL" 2 "AUTO" 3 "CALIBRATION" 4 "FAULT_HOLD";
VAL_ 770 estop_cmd 165 "EMERGENCY_STOP";
VAL_ 770 reason 0 "manual" 1 "comm_fault" 2 "master_fault";
VAL_ 785 node_command 0 "NOP" 1 "ENABLE" 2 "DISABLE" 3 "ZERO_POS" 4 "CLEAR_FAULT";
VAL_ 786 node_command 0 "NOP" 1 "ENABLE" 2 "DISABLE" 3 "ZERO_POS" 4 "CLEAR_FAULT";
VAL_ 787 node_command 0 "NOP" 1 "ENABLE" 2 "DISABLE" 3 "ZERO_POS" 4 "CLEAR_FAULT";
VAL_ 788 node_command 0 "NOP" 1 "ENABLE" 2 "DISABLE" 3 "ZERO_POS" 4 "CLEAR_FAULT";
VAL_ 789 node_command 0 "NOP" 1 "ENABLE" 2 "DISABLE" 3 "ZERO_POS" 4 "CLEAR_FAULT";
VAL_ 790 node_command 0 "NOP" 1 "ENABLE" 2 "DISABLE" 3 "ZERO_POS" 4 "CLEAR_FAULT";
VAL_ 791 node_command 0 "NOP" 1 "ENABLE" 2 "DISABLE" 3 "ZERO_POS" 4 "CLEAR_FAULT";
VAL_ 792 node_command 0 "NOP" 1 "ENABLE" 2 "DISABLE" 3 "ZERO_POS" 4 "CLEAR_FAULT";
VAL_ 793 node_command 0 "NOP" 1 "ENABLE" 2 "DISABLE" 3 "ZERO_POS" 4 "CLEAR_FAULT";
VAL_ 794 node_command 0 "NOP" 1 "ENABLE" 2 "DISABLE" 3 "ZERO_POS" 4 "CLEAR_FAULT";
VAL_ 795 node_command 0 "NOP" 1 "ENABLE" 2 "DISABLE" 3 "ZERO_POS" 4 "CLEAR_FAULT";
VAL_ 796 node_command 0 "NOP" 1 "ENABLE" 2 "DISABLE" 3 "ZERO_POS" 4 "CLEAR_FAULT";
